VERSION ""

NS_ :

BS_:

BU_: PowertrainControlModule AtmosphericSensor SafetyRestraintSystem2 Aftertreatment_2_GasOutlet Aftertreatment_2_GasIntake DieselParticulateFilterControl Turbocharger SafetyRestraintSystem1 CabDisplay2 Aftertreatment_1_GasOutlet Aftertreatment_1_GasIntake OnBoardDataLogger OffBoardDiagnosticTool2 OffBoardDiagnosticTool1 FileServer ParkingBrakeController SeatController2 FanDriveController SteeringColumnUnit CommunicationUnitRadio CommunicationUnitSatellite CommunicationUnitCellular PropulsionBatteryCharger ChassisController2 ChassisController1 EngineValveControl AuxiliaryHeater2 AuxiliaryHeater1 ClutchUnit RampControl InformationSystem1 SuspensionSystemController2 OilSensor VehicleDynamicStability ExhaustEmissionController TransmissionDisplay2 TransmissionDisplay1 ClimateControl2 WaterPumpController RearAxleSteeringController LightingOperatorControl SeatController1 IgnitionController2 IgnitionController1 TirePressureController CabController2 CabController1 PneumaticSystemController SuspensionSystemController1 HydraulicPumpController EnduranceBrakingSystem RetarderExhaustEngine2 OnBoardDiagnosticUnit HeadwayController RetarderExhaustEngine1 CabDisplay1 ManagementComputer VirtualTerminal OffVehicleGateway PowerTakeOffFront HitchControl AuxiliaryValveControl BodyController TractorTrailerBridge1 StarterSystem ElectricalSystem VehicleSecurity VehicleNavigation AerodynamicControl ElectricalChargingSystem ClimateControl1 TripRecorder InstrumentCluster SuspensionDriveAxle2 SuspensionDriveAxle1 SuspensionSteerAxle SteeringController FuelSystem CruiseControl RetarderDriveline RetarderEngine BrakesDriveAxle2 BrakesDriveAxle1 BrakesSystemController BrakesSteerAxle AxleDrive2 AxleDrive1 AxleSteering PowerTakeOff ShiftConsoleSecondary ShiftConsolePrimary Transmission2 Transmission1 Engine2 Engine1

BO_ 2364643326 HVESP1S1: 8 Vector__XXX
 SG_ Status1CRC : 56|8@1+ (1,0) [0|255] "" Vector__XXX
 SG_ Status1Counter : 52|4@1+ (1,0) [0|15] "" Vector__XXX
 SG_ OperationalStatus : 44|4@1+ (1,0) [0|15] "" Vector__XXX
 SG_ HVBusConnectionStatus : 40|4@1+ (1,0) [0|15] "" Vector__XXX
 SG_ InternalChargerStatus : 32|2@1+ (1,0) [0|3] "" Vector__XXX
 SG_ CellBalancingActive : 30|2@1+ (1,0) [0|3] "" Vector__XXX
 SG_ CellBalanceStatus : 28|2@1+ (1,0) [0|3] "" Vector__XXX
 SG_ StOfChargeStatus : 24|4@1+ (1,0) [0|15] "" Vector__XXX
 SG_ InertiaSwStatus : 22|2@1+ (1,0) [0|3] "" Vector__XXX
 SG_ HVILStatus : 20|2@1+ (1,0) [0|3] "" Vector__XXX
 SG_ HVBusPassiveIsolTestStatus : 16|4@1+ (1,0) [0|15] "" Vector__XXX
 SG_ HVBusActiveIsolTestStatus : 12|4@1+ (1,0) [0|15] "" Vector__XXX
 SG_ CenterOfPackContactorSt : 10|2@1+ (1,0) [0|3] "" Vector__XXX
 SG_ HVBusPreChargeRelaySt : 8|2@1+ (1,0) [0|3] "" Vector__XXX
 SG_ HVBusDisconnectForewarning : 4|4@1+ (1,0) [0|15] "" Vector__XXX
 SG_ HVBusContactorSt11076 : 2|2@1+ (1,0) [0|3] "" Vector__XXX
 SG_ HVBusContactorSt : 0|2@1+ (1,0) [0|3] "" Vector__XXX

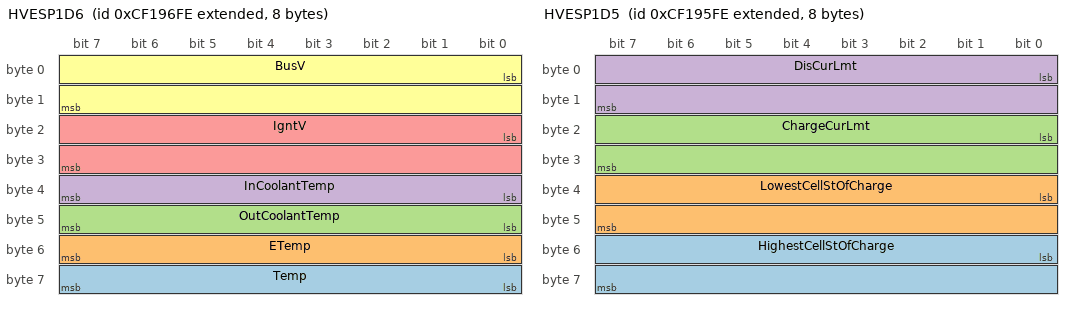
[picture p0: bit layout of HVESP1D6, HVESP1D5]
BO_ 2364643070 HVESP1D6: 8 Vector__XXX
 SG_ Temp : 56|8@1+ (1,-40) [-40|210] "°C" Vector__XXX
 SG_ ETemp : 48|8@1+ (1,-40) [-40|210] "°C" Vector__XXX
 SG_ OutCoolantTemp : 40|8@1+ (1,-40) [-40|210] "°C" Vector__XXX
 SG_ InCoolantTemp : 32|8@1+ (1,-40) [-40|210] "°C" Vector__XXX
 SG_ IgntV : 16|16@1+ (0.01,0) [0|642.55] "V" Vector__XXX
 SG_ BusV : 0|16@1+ (0.05,0) [0|3212.75] "V" Vector__XXX

BO_ 2364642814 HVESP1D5: 8 Vector__XXX
 SG_ HighestCellStOfCharge : 48|16@1+ (0.0015625,0) [0|100.3984375] "%" Vector__XXX
 SG_ LowestCellStOfCharge : 32|16@1+ (0.0015625,0) [0|100.3984375] "%" Vector__XXX
 SG_ ChargeCurLmt : 16|16@1+ (0.05,-1600) [0|1612.75] "A" Vector__XXX
 SG_ DisCurLmt : 0|16@1+ (0.05,-1600) [-1600|0] "A" Vector__XXX

BO_ 2364642558 HVESP1D4: 8 Vector__XXX
 SG_ CellBalancingCount : 32|16@1+ (1,0) [0|64255] "" Vector__XXX
 SG_ ChargeCapacity : 16|16@1+ (0.01,0) [0|642.55] "Ah" Vector__XXX
 SG_ DisCapacity : 0|16@1+ (0.01,0) [0|642.55] "Ah" Vector__XXX

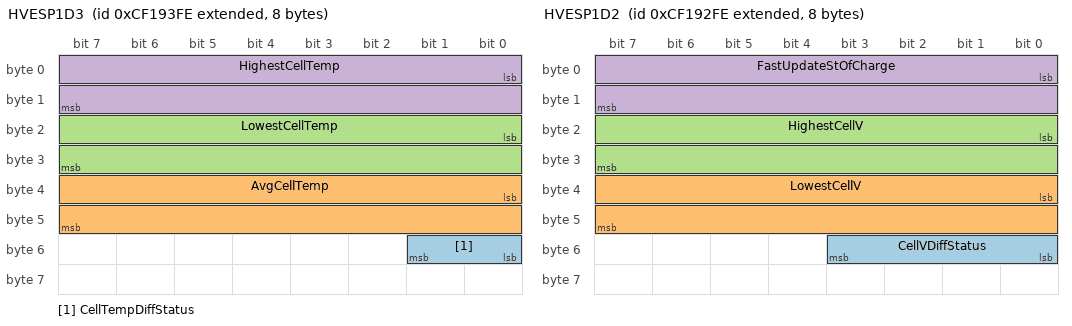
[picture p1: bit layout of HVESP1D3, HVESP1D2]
BO_ 2364642302 HVESP1D3: 8 Vector__XXX
 SG_ CellTempDiffStatus : 48|2@1+ (1,0) [0|3] "" Vector__XXX
 SG_ AvgCellTemp : 32|16@1+ (0.03125,-273) [-273|1734.96875] "°C" Vector__XXX
 SG_ LowestCellTemp : 16|16@1+ (0.03125,-273) [-273|1734.96875] "°C" Vector__XXX
 SG_ HighestCellTemp : 0|16@1+ (0.03125,-273) [-273|1734.96875] "°C" Vector__XXX

BO_ 2364642046 HVESP1D2: 8 Vector__XXX
 SG_ CellVDiffStatus : 48|4@1+ (1,0) [0|15] "" Vector__XXX
 SG_ LowestCellV : 32|16@1+ (0.001,0) [0|64.255] "V" Vector__XXX
 SG_ HighestCellV : 16|16@1+ (0.001,0) [0|64.255] "V" Vector__XXX
 SG_ FastUpdateStOfCharge : 0|16@1+ (0.0015625,0) [0|100.3984375] "%" Vector__XXX

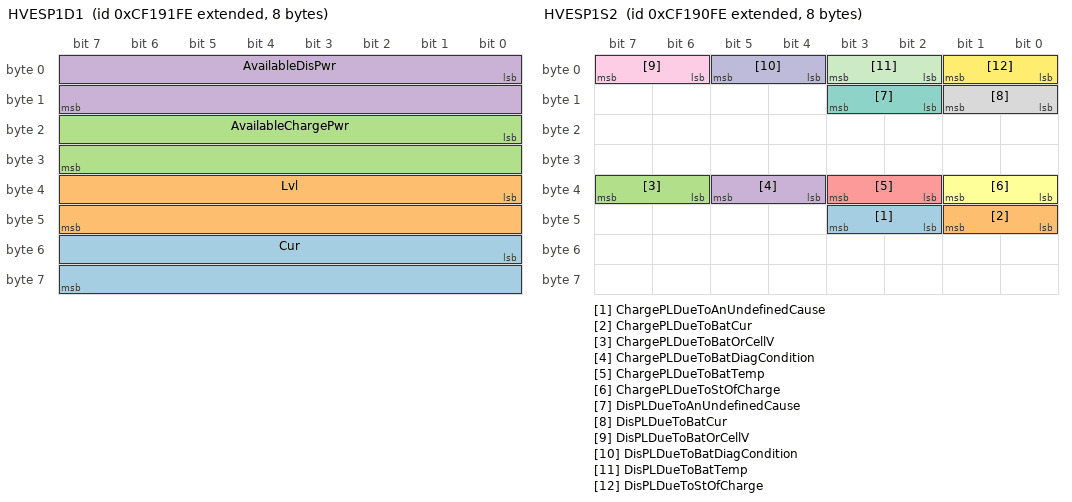
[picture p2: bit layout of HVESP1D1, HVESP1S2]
BO_ 2364641790 HVESP1D1: 8 Vector__XXX
 SG_ Cur : 48|16@1+ (0.05,-1600) [-1600|1612.75] "A" Vector__XXX
 SG_ Lvl : 32|16@1+ (0.05,0) [0|3212.75] "V" Vector__XXX
 SG_ AvailableChargePwr : 16|16@1+ (0.05,0) [0|3212.75] "kW" Vector__XXX
 SG_ AvailableDisPwr : 0|16@1+ (0.05,0) [0|3212.75] "kW" Vector__XXX

BO_ 2364641534 HVESP1S2: 8 Vector__XXX
 SG_ ChargePLDueToAnUndefinedCause : 42|2@1+ (1,0) [0|3] "" Vector__XXX
 SG_ ChargePLDueToBatCur : 40|2@1+ (1,0) [0|3] "" Vector__XXX
 SG_ ChargePLDueToBatOrCellV : 38|2@1+ (1,0) [0|3] "" Vector__XXX
 SG_ ChargePLDueToBatDiagCondition : 36|2@1+ (1,0) [0|3] "" Vector__XXX
 SG_ ChargePLDueToBatTemp : 34|2@1+ (1,0) [0|3] "" Vector__XXX
 SG_ ChargePLDueToStOfCharge : 32|2@1+ (1,0) [0|3] "" Vector__XXX
 SG_ DisPLDueToAnUndefinedCause : 10|2@1+ (1,0) [0|3] "" Vector__XXX
 SG_ DisPLDueToBatCur : 8|2@1+ (1,0) [0|3] "" Vector__XXX
 SG_ DisPLDueToBatOrCellV : 6|2@1+ (1,0) [0|3] "" Vector__XXX
 SG_ DisPLDueToBatDiagCondition : 4|2@1+ (1,0) [0|3] "" Vector__XXX
 SG_ DisPLDueToBatTemp : 2|2@1+ (1,0) [0|3] "" Vector__XXX
 SG_ DisPLDueToStOfCharge : 0|2@1+ (1,0) [0|3] "" Vector__XXX

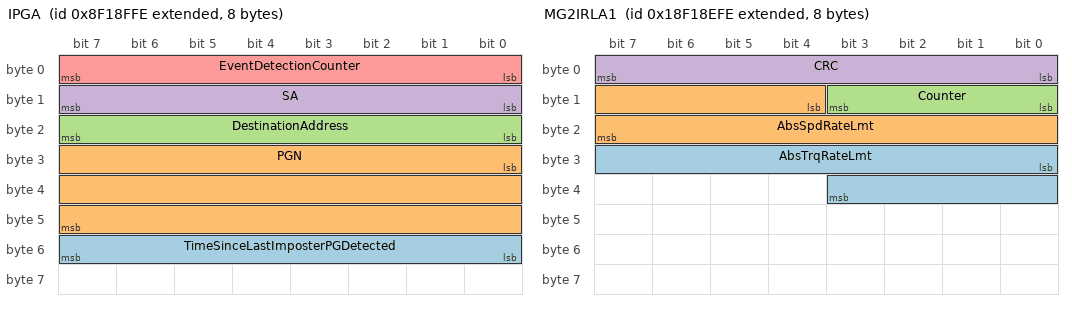
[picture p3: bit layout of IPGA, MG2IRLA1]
BO_ 2297532414 IPGA: 8 Vector__XXX
 SG_ TimeSinceLastImposterPGDetected : 48|8@1+ (1,0) [0|250] "min" Vector__XXX
 SG_ PGN : 24|24@1+ (1,0) [0|16777215] "" Vector__XXX
 SG_ DestinationAddress : 16|8@1+ (1,0) [0|255] "" Vector__XXX
 SG_ SA : 8|8@1+ (1,0) [0|255] "" Vector__XXX
 SG_ EventDetectionCounter : 0|8@1+ (1,0) [0|250] "" Vector__XXX

BO_ 2565967614 MG2IRLA1: 8 Vector__XXX
 SG_ AbsTrqRateLmt : 24|12@1+ (2,0) [0|8030] "%/s" Vector__XXX
 SG_ AbsSpdRateLmt : 12|12@1+ (0.25,0) [0|1003.75] "%/s" Vector__XXX
 SG_ Counter : 8|4@1+ (1,0) [0|15] "" Vector__XXX
 SG_ CRC : 0|8@1+ (1,0) [0|255] "" Vector__XXX

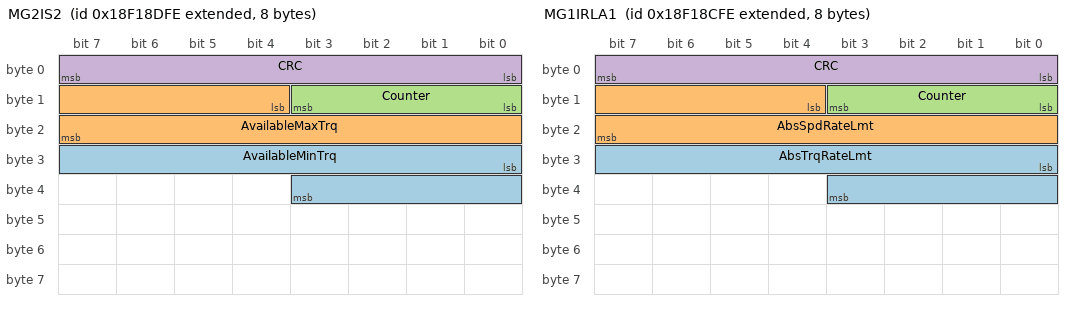
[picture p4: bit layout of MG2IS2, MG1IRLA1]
BO_ 2565967358 MG2IS2: 8 Vector__XXX
 SG_ AvailableMinTrq : 24|12@1+ (0.0625,-125) [-125|125.9375] "%" Vector__XXX
 SG_ AvailableMaxTrq : 12|12@1+ (0.0625,-125) [-125|125.9375] "%" Vector__XXX
 SG_ Counter : 8|4@1+ (1,0) [0|15] "" Vector__XXX
 SG_ CRC : 0|8@1+ (1,0) [0|255] "" Vector__XXX

BO_ 2565967102 MG1IRLA1: 8 Vector__XXX
 SG_ AbsTrqRateLmt : 24|12@1+ (2,0) [0|8030] "%/s" Vector__XXX
 SG_ AbsSpdRateLmt : 12|12@1+ (0.25,0) [0|1003.75] "%/s" Vector__XXX
 SG_ Counter : 8|4@1+ (1,0) [0|15] "" Vector__XXX
 SG_ CRC : 0|8@1+ (1,0) [0|255] "" Vector__XXX

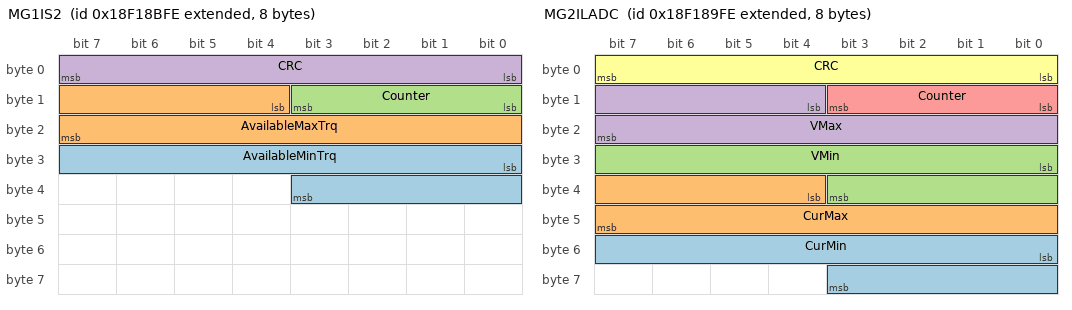
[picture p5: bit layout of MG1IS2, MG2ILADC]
BO_ 2565966846 MG1IS2: 8 Vector__XXX
 SG_ AvailableMinTrq : 24|12@1+ (0.0625,-125) [-125|125.9375] "%" Vector__XXX
 SG_ AvailableMaxTrq : 12|12@1+ (0.0625,-125) [-125|125.9375] "%" Vector__XXX
 SG_ Counter : 8|4@1+ (1,0) [0|15] "" Vector__XXX
 SG_ CRC : 0|8@1+ (1,0) [0|255] "" Vector__XXX

BO_ 2565966590 MG2ILV: 8 Vector__XXX
 SG_ UnswitchedSLIV : 16|16@1+ (0.05,0) [0|3212.75] "V" Vector__XXX
 SG_ SwitchedIgntV : 0|16@1+ (0.05,0) [0|3212.75] "V" Vector__XXX

BO_ 2565966334 MG2ILADC: 8 Vector__XXX
 SG_ CurMin : 48|12@1+ (0.0625,-125) [-125|125.9375] "%" Vector__XXX
 SG_ CurMax : 36|12@1+ (0.0625,-125) [-125|125.9375] "%" Vector__XXX
 SG_ VMin : 24|12@1+ (0.0625,-125) [-125|125.9375] "%" Vector__XXX
 SG_ VMax : 12|12@1+ (0.0625,-125) [-125|125.9375] "%" Vector__XXX
 SG_ Counter : 8|4@1+ (1,0) [0|15] "" Vector__XXX
 SG_ CRC : 0|8@1+ (1,0) [0|255] "" Vector__XXX

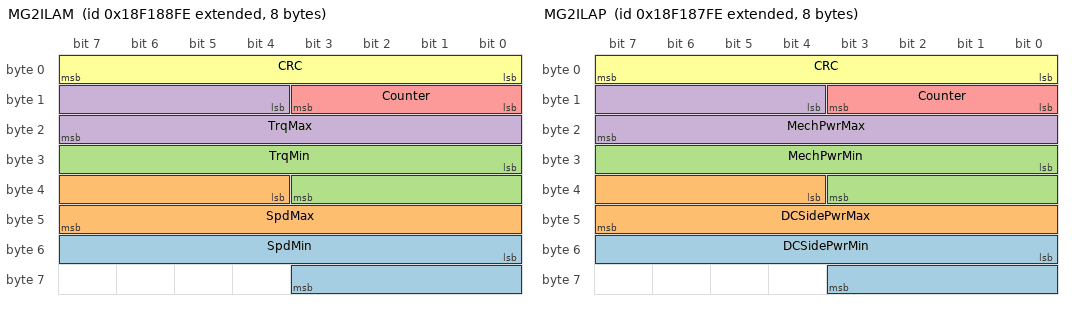
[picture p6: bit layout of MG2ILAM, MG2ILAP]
BO_ 2565966078 MG2ILAM: 8 Vector__XXX
 SG_ SpdMin : 48|12@1+ (0.0625,-125) [-125|125.9375] "%" Vector__XXX
 SG_ SpdMax : 36|12@1+ (0.0625,-125) [-125|125.9375] "%" Vector__XXX
 SG_ TrqMin : 24|12@1+ (0.0625,-125) [-125|125.9375] "%" Vector__XXX
 SG_ TrqMax : 12|12@1+ (0.0625,-125) [-125|125.9375] "%" Vector__XXX
 SG_ Counter : 8|4@1+ (1,0) [0|15] "" Vector__XXX
 SG_ CRC : 0|8@1+ (1,0) [0|255] "" Vector__XXX

BO_ 2565965822 MG2ILAP: 8 Vector__XXX
 SG_ DCSidePwrMin : 48|12@1+ (0.0625,-125) [-125|125.9375] "%" Vector__XXX
 SG_ DCSidePwrMax : 36|12@1+ (0.0625,-125) [-125|125.9375] "%" Vector__XXX
 SG_ MechPwrMin : 24|12@1+ (0.0625,-125) [-125|125.9375] "%" Vector__XXX
 SG_ MechPwrMax : 12|12@1+ (0.0625,-125) [-125|125.9375] "%" Vector__XXX
 SG_ Counter : 8|4@1+ (1,0) [0|15] "" Vector__XXX
 SG_ CRC : 0|8@1+ (1,0) [0|255] "" Vector__XXX

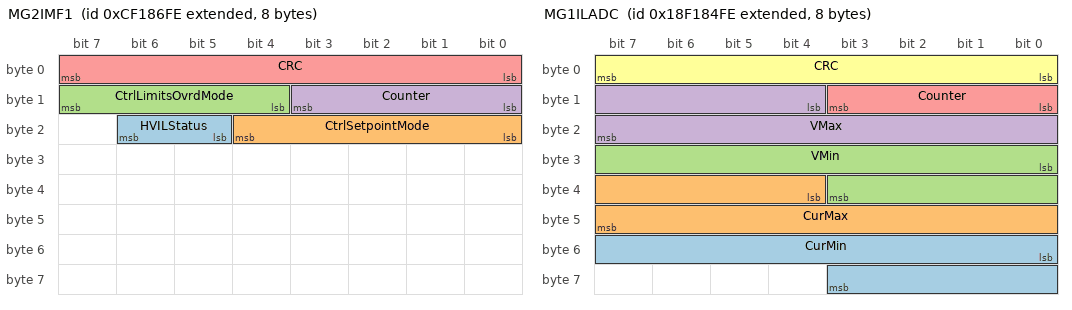
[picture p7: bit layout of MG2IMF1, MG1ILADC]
BO_ 2364638974 MG2IMF1: 8 Vector__XXX
 SG_ HVILStatus : 21|2@1+ (1,0) [0|3] "" Vector__XXX
 SG_ CtrlSetpointMode : 16|5@1+ (1,0) [0|31] "" Vector__XXX
 SG_ CtrlLimitsOvrdMode : 12|4@1+ (1,0) [0|15] "" Vector__XXX
 SG_ Counter : 8|4@1+ (1,0) [0|15] "" Vector__XXX
 SG_ CRC : 0|8@1+ (1,0) [0|255] "" Vector__XXX

BO_ 2565965310 MG1ILV: 8 Vector__XXX
 SG_ UnswitchedSLIV : 16|16@1+ (0.05,0) [0|3212.75] "V" Vector__XXX
 SG_ SwitchedIgntV : 0|16@1+ (0.05,0) [0|3212.75] "V" Vector__XXX

BO_ 2565965054 MG1ILADC: 8 Vector__XXX
 SG_ CurMin : 48|12@1+ (0.0625,-125) [-125|125.9375] "%" Vector__XXX
 SG_ CurMax : 36|12@1+ (0.0625,-125) [-125|125.9375] "%" Vector__XXX
 SG_ VMin : 24|12@1+ (0.0625,-125) [-125|125.9375] "%" Vector__XXX
 SG_ VMax : 12|12@1+ (0.0625,-125) [-125|125.9375] "%" Vector__XXX
 SG_ Counter : 8|4@1+ (1,0) [0|15] "" Vector__XXX
 SG_ CRC : 0|8@1+ (1,0) [0|255] "" Vector__XXX

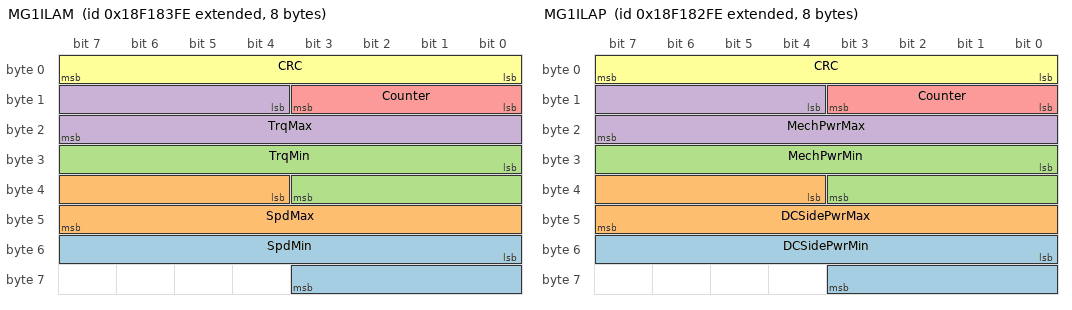
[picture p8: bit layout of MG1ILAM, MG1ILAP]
BO_ 2565964798 MG1ILAM: 8 Vector__XXX
 SG_ SpdMin : 48|12@1+ (0.0625,-125) [-125|125.9375] "%" Vector__XXX
 SG_ SpdMax : 36|12@1+ (0.0625,-125) [-125|125.9375] "%" Vector__XXX
 SG_ TrqMin : 24|12@1+ (0.0625,-125) [-125|125.9375] "%" Vector__XXX
 SG_ TrqMax : 12|12@1+ (0.0625,-125) [-125|125.9375] "%" Vector__XXX
 SG_ Counter : 8|4@1+ (1,0) [0|15] "" Vector__XXX
 SG_ CRC : 0|8@1+ (1,0) [0|255] "" Vector__XXX

BO_ 2565964542 MG1ILAP: 8 Vector__XXX
 SG_ DCSidePwrMin : 48|12@1+ (0.0625,-125) [-125|125.9375] "%" Vector__XXX
 SG_ DCSidePwrMax : 36|12@1+ (0.0625,-125) [-125|125.9375] "%" Vector__XXX
 SG_ MechPwrMin : 24|12@1+ (0.0625,-125) [-125|125.9375] "%" Vector__XXX
 SG_ MechPwrMax : 12|12@1+ (0.0625,-125) [-125|125.9375] "%" Vector__XXX
 SG_ Counter : 8|4@1+ (1,0) [0|15] "" Vector__XXX
 SG_ CRC : 0|8@1+ (1,0) [0|255] "" Vector__XXX

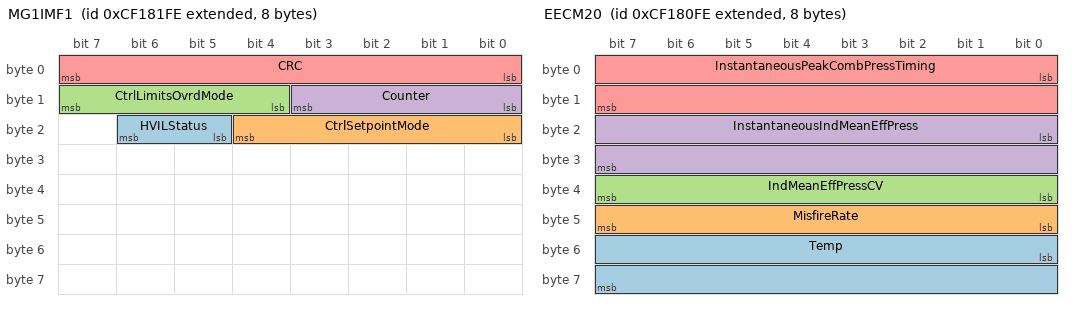
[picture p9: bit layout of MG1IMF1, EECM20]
BO_ 2364637694 MG1IMF1: 8 Vector__XXX
 SG_ HVILStatus : 21|2@1+ (1,0) [0|3] "" Vector__XXX
 SG_ CtrlSetpointMode : 16|5@1+ (1,0) [0|31] "" Vector__XXX
 SG_ CtrlLimitsOvrdMode : 12|4@1+ (1,0) [0|15] "" Vector__XXX
 SG_ Counter : 8|4@1+ (1,0) [0|15] "" Vector__XXX
 SG_ CRC : 0|8@1+ (1,0) [0|255] "" Vector__XXX

BO_ 2364637438 EECM20: 8 Vector__XXX
 SG_ Temp : 48|16@1+ (0.03125,-273) [-273|1734.96875] "°C" Vector__XXX
 SG_ MisfireRate : 40|8@1+ (0.4,0) [0|100] "%" Vector__XXX
 SG_ IndMeanEffPressCV : 32|8@1+ (0.04,0) [0|10] "%" Vector__XXX
 SG_ InstantaneousIndMeanEffPress : 16|16@1+ (0.0001220703125,-1) [-1|6.8436279296875] "MPa" Vector__XXX
 SG_ InstantaneousPeakCombPressTiming : 0|16@1+ (0.00390625,-125) [-125|125.99609375] "deg" Vector__XXX

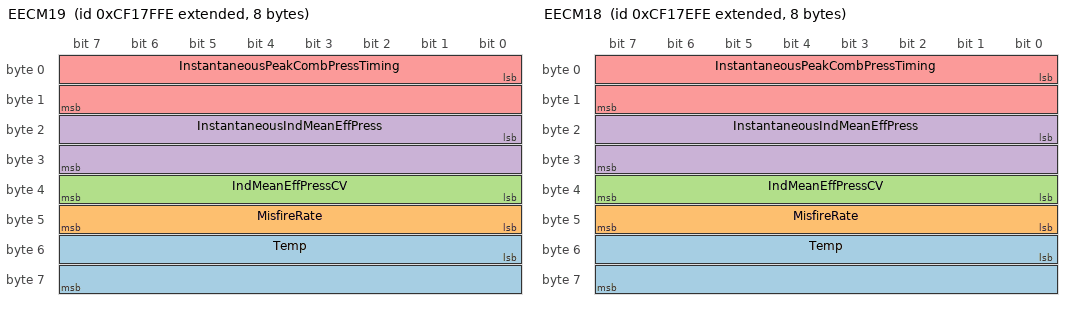
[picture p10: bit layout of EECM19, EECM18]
BO_ 2364637182 EECM19: 8 Vector__XXX
 SG_ Temp : 48|16@1+ (0.03125,-273) [-273|1734.96875] "°C" Vector__XXX
 SG_ MisfireRate : 40|8@1+ (0.4,0) [0|100] "%" Vector__XXX
 SG_ IndMeanEffPressCV : 32|8@1+ (0.04,0) [0|10] "%" Vector__XXX
 SG_ InstantaneousIndMeanEffPress : 16|16@1+ (0.0001220703125,-1) [-1|6.8436279296875] "MPa" Vector__XXX
 SG_ InstantaneousPeakCombPressTiming : 0|16@1+ (0.00390625,-125) [-125|125.99609375] "deg" Vector__XXX

BO_ 2364636926 EECM18: 8 Vector__XXX
 SG_ Temp : 48|16@1+ (0.03125,-273) [-273|1734.96875] "°C" Vector__XXX
 SG_ MisfireRate : 40|8@1+ (0.4,0) [0|100] "%" Vector__XXX
 SG_ IndMeanEffPressCV : 32|8@1+ (0.04,0) [0|10] "%" Vector__XXX
 SG_ InstantaneousIndMeanEffPress : 16|16@1+ (0.0001220703125,-1) [-1|6.8436279296875] "MPa" Vector__XXX
 SG_ InstantaneousPeakCombPressTiming : 0|16@1+ (0.00390625,-125) [-125|125.99609375] "deg" Vector__XXX

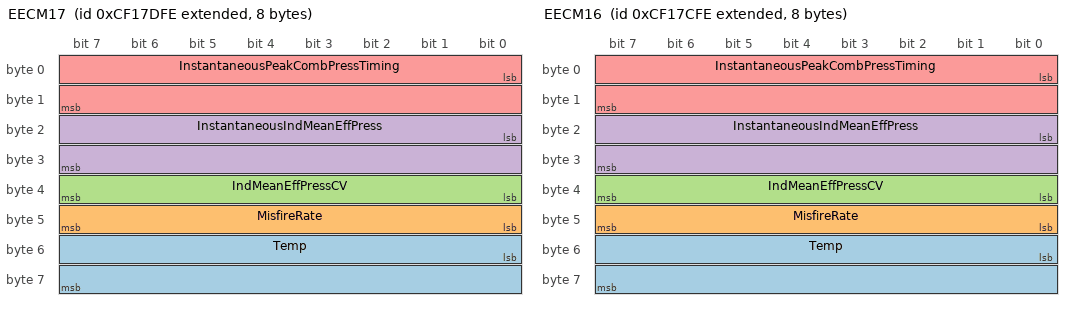
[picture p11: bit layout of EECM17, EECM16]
BO_ 2364636670 EECM17: 8 Vector__XXX
 SG_ Temp : 48|16@1+ (0.03125,-273) [-273|1734.96875] "°C" Vector__XXX
 SG_ MisfireRate : 40|8@1+ (0.4,0) [0|100] "%" Vector__XXX
 SG_ IndMeanEffPressCV : 32|8@1+ (0.04,0) [0|10] "%" Vector__XXX
 SG_ InstantaneousIndMeanEffPress : 16|16@1+ (0.0001220703125,-1) [-1|6.8436279296875] "MPa" Vector__XXX
 SG_ InstantaneousPeakCombPressTiming : 0|16@1+ (0.00390625,-125) [-125|125.99609375] "deg" Vector__XXX

BO_ 2364636414 EECM16: 8 Vector__XXX
 SG_ Temp : 48|16@1+ (0.03125,-273) [-273|1734.96875] "°C" Vector__XXX
 SG_ MisfireRate : 40|8@1+ (0.4,0) [0|100] "%" Vector__XXX
 SG_ IndMeanEffPressCV : 32|8@1+ (0.04,0) [0|10] "%" Vector__XXX
 SG_ InstantaneousIndMeanEffPress : 16|16@1+ (0.0001220703125,-1) [-1|6.8436279296875] "MPa" Vector__XXX
 SG_ InstantaneousPeakCombPressTiming : 0|16@1+ (0.00390625,-125) [-125|125.99609375] "deg" Vector__XXX

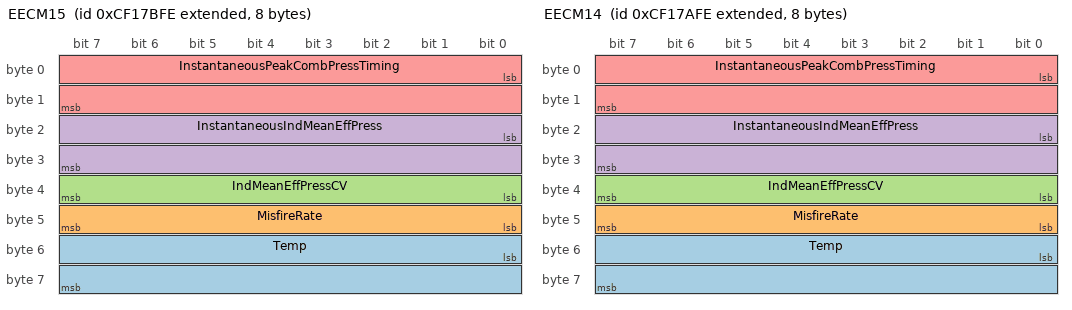
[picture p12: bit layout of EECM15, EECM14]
BO_ 2364636158 EECM15: 8 Vector__XXX
 SG_ Temp : 48|16@1+ (0.03125,-273) [-273|1734.96875] "°C" Vector__XXX
 SG_ MisfireRate : 40|8@1+ (0.4,0) [0|100] "%" Vector__XXX
 SG_ IndMeanEffPressCV : 32|8@1+ (0.04,0) [0|10] "%" Vector__XXX
 SG_ InstantaneousIndMeanEffPress : 16|16@1+ (0.0001220703125,-1) [-1|6.8436279296875] "MPa" Vector__XXX
 SG_ InstantaneousPeakCombPressTiming : 0|16@1+ (0.00390625,-125) [-125|125.99609375] "deg" Vector__XXX

BO_ 2364635902 EECM14: 8 Vector__XXX
 SG_ Temp : 48|16@1+ (0.03125,-273) [-273|1734.96875] "°C" Vector__XXX
 SG_ MisfireRate : 40|8@1+ (0.4,0) [0|100] "%" Vector__XXX
 SG_ IndMeanEffPressCV : 32|8@1+ (0.04,0) [0|10] "%" Vector__XXX
 SG_ InstantaneousIndMeanEffPress : 16|16@1+ (0.0001220703125,-1) [-1|6.8436279296875] "MPa" Vector__XXX
 SG_ InstantaneousPeakCombPressTiming : 0|16@1+ (0.00390625,-125) [-125|125.99609375] "deg" Vector__XXX

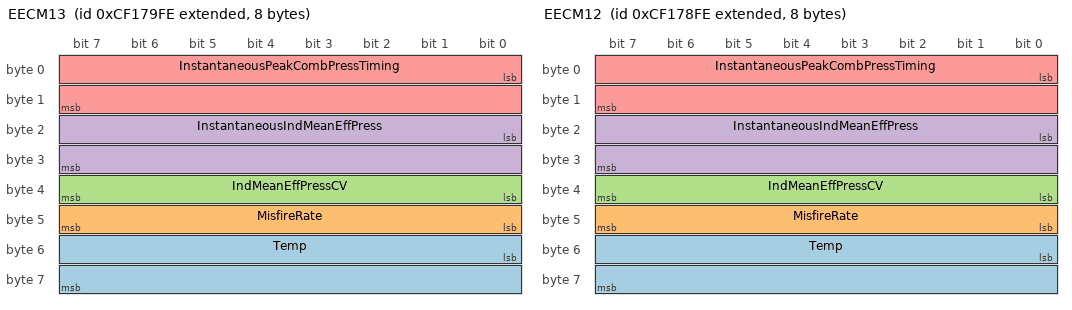
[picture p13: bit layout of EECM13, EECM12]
BO_ 2364635646 EECM13: 8 Vector__XXX
 SG_ Temp : 48|16@1+ (0.03125,-273) [-273|1734.96875] "°C" Vector__XXX
 SG_ MisfireRate : 40|8@1+ (0.4,0) [0|100] "%" Vector__XXX
 SG_ IndMeanEffPressCV : 32|8@1+ (0.04,0) [0|10] "%" Vector__XXX
 SG_ InstantaneousIndMeanEffPress : 16|16@1+ (0.0001220703125,-1) [-1|6.8436279296875] "MPa" Vector__XXX
 SG_ InstantaneousPeakCombPressTiming : 0|16@1+ (0.00390625,-125) [-125|125.99609375] "deg" Vector__XXX

BO_ 2364635390 EECM12: 8 Vector__XXX
 SG_ Temp : 48|16@1+ (0.03125,-273) [-273|1734.96875] "°C" Vector__XXX
 SG_ MisfireRate : 40|8@1+ (0.4,0) [0|100] "%" Vector__XXX
 SG_ IndMeanEffPressCV : 32|8@1+ (0.04,0) [0|10] "%" Vector__XXX
 SG_ InstantaneousIndMeanEffPress : 16|16@1+ (0.0001220703125,-1) [-1|6.8436279296875] "MPa" Vector__XXX
 SG_ InstantaneousPeakCombPressTiming : 0|16@1+ (0.00390625,-125) [-125|125.99609375] "deg" Vector__XXX

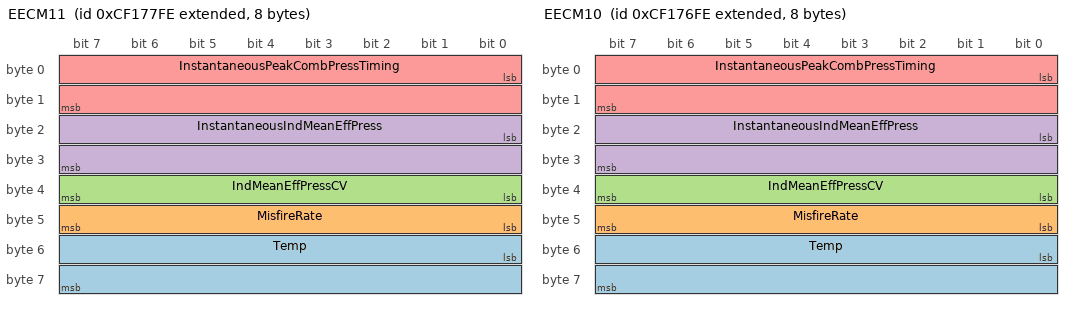
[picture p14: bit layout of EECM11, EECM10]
BO_ 2364635134 EECM11: 8 Vector__XXX
 SG_ Temp : 48|16@1+ (0.03125,-273) [-273|1734.96875] "°C" Vector__XXX
 SG_ MisfireRate : 40|8@1+ (0.4,0) [0|100] "%" Vector__XXX
 SG_ IndMeanEffPressCV : 32|8@1+ (0.04,0) [0|10] "%" Vector__XXX
 SG_ InstantaneousIndMeanEffPress : 16|16@1+ (0.0001220703125,-1) [-1|6.8436279296875] "MPa" Vector__XXX
 SG_ InstantaneousPeakCombPressTiming : 0|16@1+ (0.00390625,-125) [-125|125.99609375] "deg" Vector__XXX

BO_ 2364634878 EECM10: 8 Vector__XXX
 SG_ Temp : 48|16@1+ (0.03125,-273) [-273|1734.96875] "°C" Vector__XXX
 SG_ MisfireRate : 40|8@1+ (0.4,0) [0|100] "%" Vector__XXX
 SG_ IndMeanEffPressCV : 32|8@1+ (0.04,0) [0|10] "%" Vector__XXX
 SG_ InstantaneousIndMeanEffPress : 16|16@1+ (0.0001220703125,-1) [-1|6.8436279296875] "MPa" Vector__XXX
 SG_ InstantaneousPeakCombPressTiming : 0|16@1+ (0.00390625,-125) [-125|125.99609375] "deg" Vector__XXX

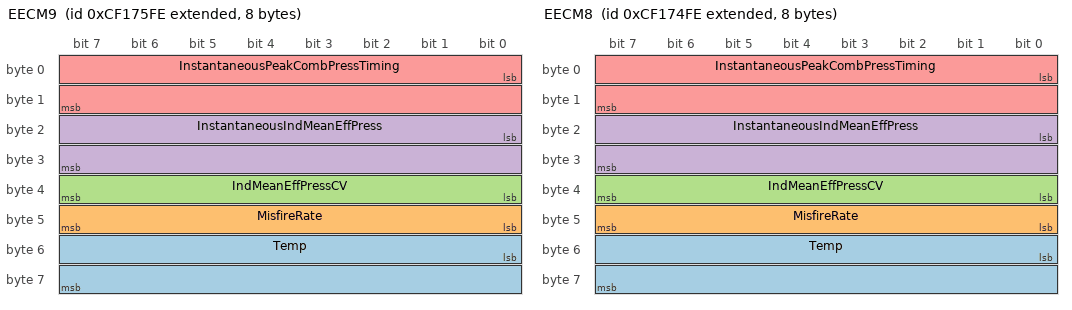
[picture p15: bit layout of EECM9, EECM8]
BO_ 2364634622 EECM9: 8 Vector__XXX
 SG_ Temp : 48|16@1+ (0.03125,-273) [-273|1734.96875] "°C" Vector__XXX
 SG_ MisfireRate : 40|8@1+ (0.4,0) [0|100] "%" Vector__XXX
 SG_ IndMeanEffPressCV : 32|8@1+ (0.04,0) [0|10] "%" Vector__XXX
 SG_ InstantaneousIndMeanEffPress : 16|16@1+ (0.0001220703125,-1) [-1|6.8436279296875] "MPa" Vector__XXX
 SG_ InstantaneousPeakCombPressTiming : 0|16@1+ (0.00390625,-125) [-125|125.99609375] "deg" Vector__XXX

BO_ 2364634366 EECM8: 8 Vector__XXX
 SG_ Temp : 48|16@1+ (0.03125,-273) [-273|1734.96875] "°C" Vector__XXX
 SG_ MisfireRate : 40|8@1+ (0.4,0) [0|100] "%" Vector__XXX
 SG_ IndMeanEffPressCV : 32|8@1+ (0.04,0) [0|10] "%" Vector__XXX
 SG_ InstantaneousIndMeanEffPress : 16|16@1+ (0.0001220703125,-1) [-1|6.8436279296875] "MPa" Vector__XXX
 SG_ InstantaneousPeakCombPressTiming : 0|16@1+ (0.00390625,-125) [-125|125.99609375] "deg" Vector__XXX

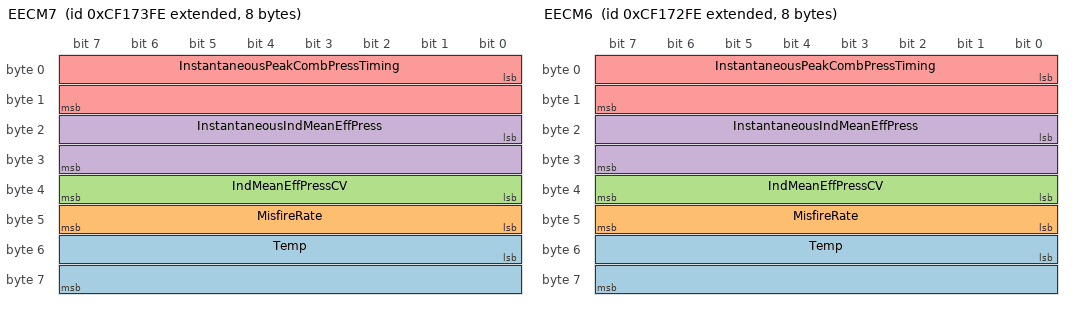
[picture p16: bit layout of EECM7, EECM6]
BO_ 2364634110 EECM7: 8 Vector__XXX
 SG_ Temp : 48|16@1+ (0.03125,-273) [-273|1734.96875] "°C" Vector__XXX
 SG_ MisfireRate : 40|8@1+ (0.4,0) [0|100] "%" Vector__XXX
 SG_ IndMeanEffPressCV : 32|8@1+ (0.04,0) [0|10] "%" Vector__XXX
 SG_ InstantaneousIndMeanEffPress : 16|16@1+ (0.0001220703125,-1) [-1|6.8436279296875] "MPa" Vector__XXX
 SG_ InstantaneousPeakCombPressTiming : 0|16@1+ (0.00390625,-125) [-125|125.99609375] "deg" Vector__XXX

BO_ 2364633854 EECM6: 8 Vector__XXX
 SG_ Temp : 48|16@1+ (0.03125,-273) [-273|1734.96875] "°C" Vector__XXX
 SG_ MisfireRate : 40|8@1+ (0.4,0) [0|100] "%" Vector__XXX
 SG_ IndMeanEffPressCV : 32|8@1+ (0.04,0) [0|10] "%" Vector__XXX
 SG_ InstantaneousIndMeanEffPress : 16|16@1+ (0.0001220703125,-1) [-1|6.8436279296875] "MPa" Vector__XXX
 SG_ InstantaneousPeakCombPressTiming : 0|16@1+ (0.00390625,-125) [-125|125.99609375] "deg" Vector__XXX

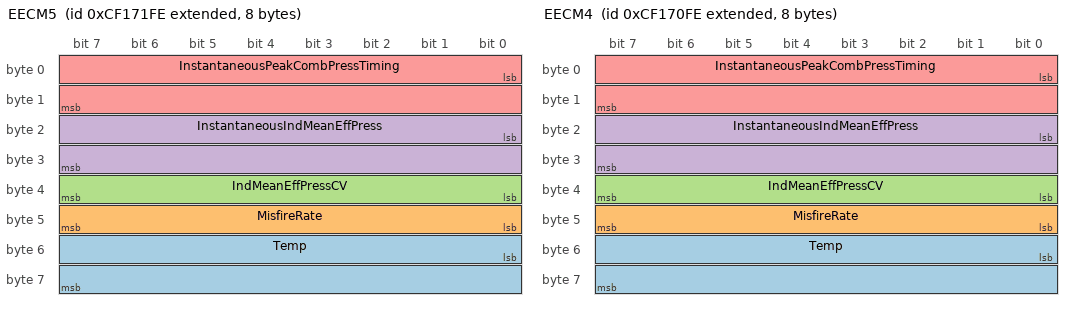
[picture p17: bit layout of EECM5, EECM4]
BO_ 2364633598 EECM5: 8 Vector__XXX
 SG_ Temp : 48|16@1+ (0.03125,-273) [-273|1734.96875] "°C" Vector__XXX
 SG_ MisfireRate : 40|8@1+ (0.4,0) [0|100] "%" Vector__XXX
 SG_ IndMeanEffPressCV : 32|8@1+ (0.04,0) [0|10] "%" Vector__XXX
 SG_ InstantaneousIndMeanEffPress : 16|16@1+ (0.0001220703125,-1) [-1|6.8436279296875] "MPa" Vector__XXX
 SG_ InstantaneousPeakCombPressTiming : 0|16@1+ (0.00390625,-125) [-125|125.99609375] "deg" Vector__XXX

BO_ 2364633342 EECM4: 8 Vector__XXX
 SG_ Temp : 48|16@1+ (0.03125,-273) [-273|1734.96875] "°C" Vector__XXX
 SG_ MisfireRate : 40|8@1+ (0.4,0) [0|100] "%" Vector__XXX
 SG_ IndMeanEffPressCV : 32|8@1+ (0.04,0) [0|10] "%" Vector__XXX
 SG_ InstantaneousIndMeanEffPress : 16|16@1+ (0.0001220703125,-1) [-1|6.8436279296875] "MPa" Vector__XXX
 SG_ InstantaneousPeakCombPressTiming : 0|16@1+ (0.00390625,-125) [-125|125.99609375] "deg" Vector__XXX

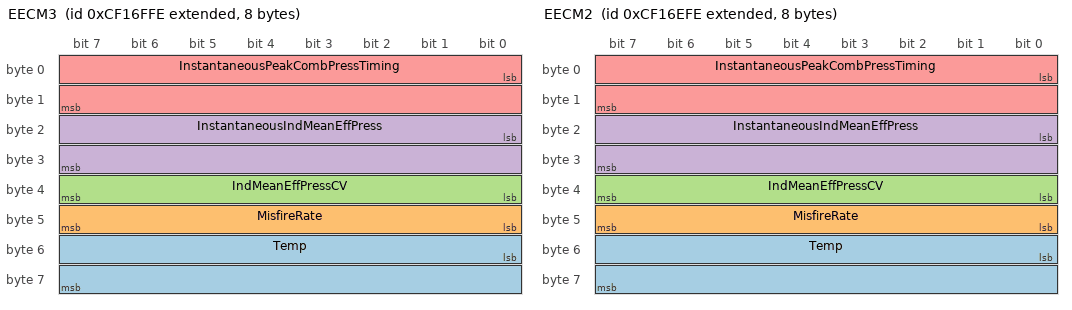
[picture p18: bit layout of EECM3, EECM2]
BO_ 2364633086 EECM3: 8 Vector__XXX
 SG_ Temp : 48|16@1+ (0.03125,-273) [-273|1734.96875] "°C" Vector__XXX
 SG_ MisfireRate : 40|8@1+ (0.4,0) [0|100] "%" Vector__XXX
 SG_ IndMeanEffPressCV : 32|8@1+ (0.04,0) [0|10] "%" Vector__XXX
 SG_ InstantaneousIndMeanEffPress : 16|16@1+ (0.0001220703125,-1) [-1|6.8436279296875] "MPa" Vector__XXX
 SG_ InstantaneousPeakCombPressTiming : 0|16@1+ (0.00390625,-125) [-125|125.99609375] "deg" Vector__XXX

BO_ 2364632830 EECM2: 8 Vector__XXX
 SG_ Temp : 48|16@1+ (0.03125,-273) [-273|1734.96875] "°C" Vector__XXX
 SG_ MisfireRate : 40|8@1+ (0.4,0) [0|100] "%" Vector__XXX
 SG_ IndMeanEffPressCV : 32|8@1+ (0.04,0) [0|10] "%" Vector__XXX
 SG_ InstantaneousIndMeanEffPress : 16|16@1+ (0.0001220703125,-1) [-1|6.8436279296875] "MPa" Vector__XXX
 SG_ InstantaneousPeakCombPressTiming : 0|16@1+ (0.00390625,-125) [-125|125.99609375] "deg" Vector__XXX

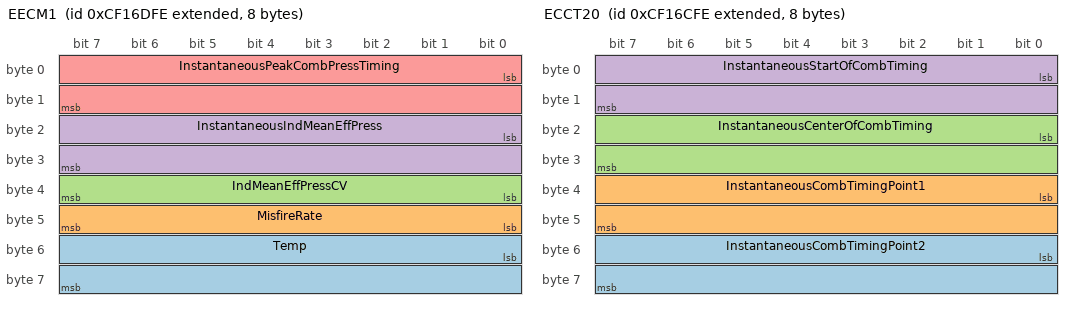
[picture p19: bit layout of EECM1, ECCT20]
BO_ 2364632574 EECM1: 8 Vector__XXX
 SG_ Temp : 48|16@1+ (0.03125,-273) [-273|1734.96875] "°C" Vector__XXX
 SG_ MisfireRate : 40|8@1+ (0.4,0) [0|100] "%" Vector__XXX
 SG_ IndMeanEffPressCV : 32|8@1+ (0.04,0) [0|10] "%" Vector__XXX
 SG_ InstantaneousIndMeanEffPress : 16|16@1+ (0.0001220703125,-1) [-1|6.8436279296875] "MPa" Vector__XXX
 SG_ InstantaneousPeakCombPressTiming : 0|16@1+ (0.00390625,-125) [-125|125.99609375] "deg" Vector__XXX

BO_ 2364632318 ECCT20: 8 Vector__XXX
 SG_ InstantaneousCombTimingPoint2 : 48|16@1+ (0.00390625,-125) [-125|125.99609375] "deg" Vector__XXX
 SG_ InstantaneousCombTimingPoint1 : 32|16@1+ (0.00390625,-125) [-125|125.99609375] "deg" Vector__XXX
 SG_ InstantaneousCenterOfCombTiming : 16|16@1+ (0.00390625,-125) [-125|125.99609375] "deg" Vector__XXX
 SG_ InstantaneousStartOfCombTiming : 0|16@1+ (0.00390625,-125) [-125|125.99609375] "deg" Vector__XXX

BO_ 2364632062 ECCT19: 8 Vector__XXX
 SG_ InstantaneousCombTimingPoint2 : 48|16@1+ (0.00390625,-125) [-125|125.99609375] "deg" Vector__XXX
 SG_ InstantaneousCombTimingPoint1 : 32|16@1+ (0.00390625,-125) [-125|125.99609375] "deg" Vector__XXX
 SG_ InstantaneousCenterOfCombTiming : 16|16@1+ (0.00390625,-125) [-125|125.99609375] "deg" Vector__XXX
 SG_ InstantaneousStartOfCombTiming : 0|16@1+ (0.00390625,-125) [-125|125.99609375] "deg" Vector__XXX

BO_ 2364631806 ECCT18: 8 Vector__XXX
 SG_ InstantaneousCombTimingPoint2 : 48|16@1+ (0.00390625,-125) [-125|125.99609375] "deg" Vector__XXX
 SG_ InstantaneousCombTimingPoint1 : 32|16@1+ (0.00390625,-125) [-125|125.99609375] "deg" Vector__XXX
 SG_ InstantaneousCenterOfCombTiming : 16|16@1+ (0.00390625,-125) [-125|125.99609375] "deg" Vector__XXX
 SG_ InstantaneousStartOfCombTiming : 0|16@1+ (0.00390625,-125) [-125|125.99609375] "deg" Vector__XXX

BO_ 2364631550 ECCT17: 8 Vector__XXX
 SG_ InstantaneousCombTimingPoint2 : 48|16@1+ (0.00390625,-125) [-125|125.99609375] "deg" Vector__XXX
 SG_ InstantaneousCombTimingPoint1 : 32|16@1+ (0.00390625,-125) [-125|125.99609375] "deg" Vector__XXX
 SG_ InstantaneousCenterOfCombTiming : 16|16@1+ (0.00390625,-125) [-125|125.99609375] "deg" Vector__XXX
 SG_ InstantaneousStartOfCombTiming : 0|16@1+ (0.00390625,-125) [-125|125.99609375] "deg" Vector__XXX

BO_ 2364631294 ECCT16: 8 Vector__XXX
 SG_ InstantaneousCombTimingPoint2 : 48|16@1+ (0.00390625,-125) [-125|125.99609375] "deg" Vector__XXX
 SG_ InstantaneousCombTimingPoint1 : 32|16@1+ (0.00390625,-125) [-125|125.99609375] "deg" Vector__XXX
 SG_ InstantaneousCenterOfCombTiming : 16|16@1+ (0.00390625,-125) [-125|125.99609375] "deg" Vector__XXX
 SG_ InstantaneousStartOfCombTiming : 0|16@1+ (0.00390625,-125) [-125|125.99609375] "deg" Vector__XXX

BO_ 2364631038 ECCT15: 8 Vector__XXX
 SG_ InstantaneousCombTimingPoint2 : 48|16@1+ (0.00390625,-125) [-125|125.99609375] "deg" Vector__XXX
 SG_ InstantaneousCombTimingPoint1 : 32|16@1+ (0.00390625,-125) [-125|125.99609375] "deg" Vector__XXX
 SG_ InstantaneousCenterOfCombTiming : 16|16@1+ (0.00390625,-125) [-125|125.99609375] "deg" Vector__XXX
 SG_ InstantaneousStartOfCombTiming : 0|16@1+ (0.00390625,-125) [-125|125.99609375] "deg" Vector__XXX

BO_ 2364630782 ECCT14: 8 Vector__XXX
 SG_ InstantaneousCombTimingPoint2 : 48|16@1+ (0.00390625,-125) [-125|125.99609375] "deg" Vector__XXX
 SG_ InstantaneousCombTimingPoint1 : 32|16@1+ (0.00390625,-125) [-125|125.99609375] "deg" Vector__XXX
 SG_ InstantaneousCenterOfCombTiming : 16|16@1+ (0.00390625,-125) [-125|125.99609375] "deg" Vector__XXX
 SG_ InstantaneousStartOfCombTiming : 0|16@1+ (0.00390625,-125) [-125|125.99609375] "deg" Vector__XXX

BO_ 2364630526 ECCT13: 8 Vector__XXX
 SG_ InstantaneousCombTimingPoint2 : 48|16@1+ (0.00390625,-125) [-125|125.99609375] "deg" Vector__XXX
 SG_ InstantaneousCombTimingPoint1 : 32|16@1+ (0.00390625,-125) [-125|125.99609375] "deg" Vector__XXX
 SG_ InstantaneousCenterOfCombTiming : 16|16@1+ (0.00390625,-125) [-125|125.99609375] "deg" Vector__XXX
 SG_ InstantaneousStartOfCombTiming : 0|16@1+ (0.00390625,-125) [-125|125.99609375] "deg" Vector__XXX

BO_ 2364630270 ECCT12: 8 Vector__XXX
 SG_ InstantaneousCombTimingPoint2 : 48|16@1+ (0.00390625,-125) [-125|125.99609375] "deg" Vector__XXX
 SG_ InstantaneousCombTimingPoint1 : 32|16@1+ (0.00390625,-125) [-125|125.99609375] "deg" Vector__XXX
 SG_ InstantaneousCenterOfCombTiming : 16|16@1+ (0.00390625,-125) [-125|125.99609375] "deg" Vector__XXX
 SG_ InstantaneousStartOfCombTiming : 0|16@1+ (0.00390625,-125) [-125|125.99609375] "deg" Vector__XXX

BO_ 2364630014 ECCT11: 8 Vector__XXX
 SG_ InstantaneousCombTimingPoint2 : 48|16@1+ (0.00390625,-125) [-125|125.99609375] "deg" Vector__XXX
 SG_ InstantaneousCombTimingPoint1 : 32|16@1+ (0.00390625,-125) [-125|125.99609375] "deg" Vector__XXX
 SG_ InstantaneousCenterOfCombTiming : 16|16@1+ (0.00390625,-125) [-125|125.99609375] "deg" Vector__XXX
 SG_ InstantaneousStartOfCombTiming : 0|16@1+ (0.00390625,-125) [-125|125.99609375] "deg" Vector__XXX

BO_ 2364629758 ECCT10: 8 Vector__XXX
 SG_ InstantaneousCombTimingPoint2 : 48|16@1+ (0.00390625,-125) [-125|125.99609375] "deg" Vector__XXX
 SG_ InstantaneousCombTimingPoint1 : 32|16@1+ (0.00390625,-125) [-125|125.99609375] "deg" Vector__XXX
 SG_ InstantaneousCenterOfCombTiming : 16|16@1+ (0.00390625,-125) [-125|125.99609375] "deg" Vector__XXX
 SG_ InstantaneousStartOfCombTiming : 0|16@1+ (0.00390625,-125) [-125|125.99609375] "deg" Vector__XXX

BO_ 2364629502 ECCT9: 8 Vector__XXX
 SG_ InstantaneousCombTimingPoint2 : 48|16@1+ (0.00390625,-125) [-125|125.99609375] "deg" Vector__XXX
 SG_ InstantaneousCombTimingPoint1 : 32|16@1+ (0.00390625,-125) [-125|125.99609375] "deg" Vector__XXX
 SG_ InstantaneousCenterOfCombTiming : 16|16@1+ (0.00390625,-125) [-125|125.99609375] "deg" Vector__XXX
 SG_ InstantaneousStartOfCombTiming : 0|16@1+ (0.00390625,-125) [-125|125.99609375] "deg" Vector__XXX

BO_ 2364629246 ECCT8: 8 Vector__XXX
 SG_ InstantaneousCombTimingPoint2 : 48|16@1+ (0.00390625,-125) [-125|125.99609375] "deg" Vector__XXX
 SG_ InstantaneousCombTimingPoint1 : 32|16@1+ (0.00390625,-125) [-125|125.99609375] "deg" Vector__XXX
 SG_ InstantaneousCenterOfCombTiming : 16|16@1+ (0.00390625,-125) [-125|125.99609375] "deg" Vector__XXX
 SG_ InstantaneousStartOfCombTiming : 0|16@1+ (0.00390625,-125) [-125|125.99609375] "deg" Vector__XXX

BO_ 2364628990 ECCT7: 8 Vector__XXX
 SG_ InstantaneousCombTimingPoint2 : 48|16@1+ (0.00390625,-125) [-125|125.99609375] "deg" Vector__XXX
 SG_ InstantaneousCombTimingPoint1 : 32|16@1+ (0.00390625,-125) [-125|125.99609375] "deg" Vector__XXX
 SG_ InstantaneousCenterOfCombTiming : 16|16@1+ (0.00390625,-125) [-125|125.99609375] "deg" Vector__XXX
 SG_ InstantaneousStartOfCombTiming : 0|16@1+ (0.00390625,-125) [-125|125.99609375] "deg" Vector__XXX

BO_ 2364628734 ECCT6: 8 Vector__XXX
 SG_ InstantaneousCombTimingPoint2 : 48|16@1+ (0.00390625,-125) [-125|125.99609375] "deg" Vector__XXX
 SG_ InstantaneousCombTimingPoint1 : 32|16@1+ (0.00390625,-125) [-125|125.99609375] "deg" Vector__XXX
 SG_ InstantaneousCenterOfCombTiming : 16|16@1+ (0.00390625,-125) [-125|125.99609375] "deg" Vector__XXX
 SG_ InstantaneousStartOfCombTiming : 0|16@1+ (0.00390625,-125) [-125|125.99609375] "deg" Vector__XXX

BO_ 2364628478 ECCT5: 8 Vector__XXX
 SG_ InstantaneousCombTimingPoint2 : 48|16@1+ (0.00390625,-125) [-125|125.99609375] "deg" Vector__XXX
 SG_ InstantaneousCombTimingPoint1 : 32|16@1+ (0.00390625,-125) [-125|125.99609375] "deg" Vector__XXX
 SG_ InstantaneousCenterOfCombTiming : 16|16@1+ (0.00390625,-125) [-125|125.99609375] "deg" Vector__XXX
 SG_ InstantaneousStartOfCombTiming : 0|16@1+ (0.00390625,-125) [-125|125.99609375] "deg" Vector__XXX

BO_ 2364628222 ECCT4: 8 Vector__XXX
 SG_ InstantaneousCombTimingPoint2 : 48|16@1+ (0.00390625,-125) [-125|125.99609375] "deg" Vector__XXX
 SG_ InstantaneousCombTimingPoint1 : 32|16@1+ (0.00390625,-125) [-125|125.99609375] "deg" Vector__XXX
 SG_ InstantaneousCenterOfCombTiming : 16|16@1+ (0.00390625,-125) [-125|125.99609375] "deg" Vector__XXX
 SG_ InstantaneousStartOfCombTiming : 0|16@1+ (0.00390625,-125) [-125|125.99609375] "deg" Vector__XXX

BO_ 2364627966 ECCT3: 8 Vector__XXX
 SG_ InstantaneousCombTimingPoint2 : 48|16@1+ (0.00390625,-125) [-125|125.99609375] "deg" Vector__XXX
 SG_ InstantaneousCombTimingPoint1 : 32|16@1+ (0.00390625,-125) [-125|125.99609375] "deg" Vector__XXX
 SG_ InstantaneousCenterOfCombTiming : 16|16@1+ (0.00390625,-125) [-125|125.99609375] "deg" Vector__XXX
 SG_ InstantaneousStartOfCombTiming : 0|16@1+ (0.00390625,-125) [-125|125.99609375] "deg" Vector__XXX

BO_ 2364627710 ECCT2: 8 Vector__XXX
 SG_ InstantaneousCombTimingPoint2 : 48|16@1+ (0.00390625,-125) [-125|125.99609375] "deg" Vector__XXX
 SG_ InstantaneousCombTimingPoint1 : 32|16@1+ (0.00390625,-125) [-125|125.99609375] "deg" Vector__XXX
 SG_ InstantaneousCenterOfCombTiming : 16|16@1+ (0.00390625,-125) [-125|125.99609375] "deg" Vector__XXX
 SG_ InstantaneousStartOfCombTiming : 0|16@1+ (0.00390625,-125) [-125|125.99609375] "deg" Vector__XXX

BO_ 2364627454 ECCT1: 8 Vector__XXX
 SG_ InstantaneousCombTimingPoint2 : 48|16@1+ (0.00390625,-125) [-125|125.99609375] "deg" Vector__XXX
 SG_ InstantaneousCombTimingPoint1 : 32|16@1+ (0.00390625,-125) [-125|125.99609375] "deg" Vector__XXX
 SG_ InstantaneousCenterOfCombTiming : 16|16@1+ (0.00390625,-125) [-125|125.99609375] "deg" Vector__XXX
 SG_ InstantaneousStartOfCombTiming : 0|16@1+ (0.00390625,-125) [-125|125.99609375] "deg" Vector__XXX

BO_ 2364627198 ECCP20: 8 Vector__XXX
 SG_ Timing4Press : 48|16@1+ (0.0009765625,0) [0|62.7490234375] "MPa" Vector__XXX
 SG_ Timing3Press : 32|16@1+ (0.0009765625,0) [0|62.7490234375] "MPa" Vector__XXX
 SG_ Timing2Press : 16|16@1+ (0.0009765625,0) [0|62.7490234375] "MPa" Vector__XXX
 SG_ Timing1Press : 0|16@1+ (0.0009765625,0) [0|62.7490234375] "MPa" Vector__XXX

BO_ 2364626942 ECCP19: 8 Vector__XXX
 SG_ Timing4Press : 48|16@1+ (0.0009765625,0) [0|62.7490234375] "MPa" Vector__XXX
 SG_ Timing3Press : 32|16@1+ (0.0009765625,0) [0|62.7490234375] "MPa" Vector__XXX
 SG_ Timing2Press : 16|16@1+ (0.0009765625,0) [0|62.7490234375] "MPa" Vector__XXX
 SG_ Timing1Press : 0|16@1+ (0.0009765625,0) [0|62.7490234375] "MPa" Vector__XXX

BO_ 2364626686 ECCP18: 8 Vector__XXX
 SG_ Timing4Press : 48|16@1+ (0.0009765625,0) [0|62.7490234375] "MPa" Vector__XXX
 SG_ Timing3Press : 32|16@1+ (0.0009765625,0) [0|62.7490234375] "MPa" Vector__XXX
 SG_ Timing2Press : 16|16@1+ (0.0009765625,0) [0|62.7490234375] "MPa" Vector__XXX
 SG_ Timing1Press : 0|16@1+ (0.0009765625,0) [0|62.7490234375] "MPa" Vector__XXX

BO_ 2364626430 ECCP17: 8 Vector__XXX
 SG_ Timing4Press : 48|16@1+ (0.0009765625,0) [0|62.7490234375] "MPa" Vector__XXX
 SG_ Timing3Press : 32|16@1+ (0.0009765625,0) [0|62.7490234375] "MPa" Vector__XXX
 SG_ Timing2Press : 16|16@1+ (0.0009765625,0) [0|62.7490234375] "MPa" Vector__XXX
 SG_ Timing1Press : 0|16@1+ (0.0009765625,0) [0|62.7490234375] "MPa" Vector__XXX

BO_ 2364626174 ECCP16: 8 Vector__XXX
 SG_ Timing4Press : 48|16@1+ (0.0009765625,0) [0|62.7490234375] "MPa" Vector__XXX
 SG_ Timing3Press : 32|16@1+ (0.0009765625,0) [0|62.7490234375] "MPa" Vector__XXX
 SG_ Timing2Press : 16|16@1+ (0.0009765625,0) [0|62.7490234375] "MPa" Vector__XXX
 SG_ Timing1Press : 0|16@1+ (0.0009765625,0) [0|62.7490234375] "MPa" Vector__XXX

BO_ 2364625918 ECCP15: 8 Vector__XXX
 SG_ Timing4Press : 48|16@1+ (0.0009765625,0) [0|62.7490234375] "MPa" Vector__XXX
 SG_ Timing3Press : 32|16@1+ (0.0009765625,0) [0|62.7490234375] "MPa" Vector__XXX
 SG_ Timing2Press : 16|16@1+ (0.0009765625,0) [0|62.7490234375] "MPa" Vector__XXX
 SG_ Timing1Press : 0|16@1+ (0.0009765625,0) [0|62.7490234375] "MPa" Vector__XXX

BO_ 2364625662 ECCP14: 8 Vector__XXX
 SG_ Timing4Press : 48|16@1+ (0.0009765625,0) [0|62.7490234375] "MPa" Vector__XXX
 SG_ Timing3Press : 32|16@1+ (0.0009765625,0) [0|62.7490234375] "MPa" Vector__XXX
 SG_ Timing2Press : 16|16@1+ (0.0009765625,0) [0|62.7490234375] "MPa" Vector__XXX
 SG_ Timing1Press : 0|16@1+ (0.0009765625,0) [0|62.7490234375] "MPa" Vector__XXX

BO_ 2364625406 ECCP13: 8 Vector__XXX
 SG_ Timing4Press : 48|16@1+ (0.0009765625,0) [0|62.7490234375] "MPa" Vector__XXX
 SG_ Timing3Press : 32|16@1+ (0.0009765625,0) [0|62.7490234375] "MPa" Vector__XXX
 SG_ Timing2Press : 16|16@1+ (0.0009765625,0) [0|62.7490234375] "MPa" Vector__XXX
 SG_ Timing1Press : 0|16@1+ (0.0009765625,0) [0|62.7490234375] "MPa" Vector__XXX

BO_ 2364625150 ECCP12: 8 Vector__XXX
 SG_ Timing4Press : 48|16@1+ (0.0009765625,0) [0|62.7490234375] "MPa" Vector__XXX
 SG_ Timing3Press : 32|16@1+ (0.0009765625,0) [0|62.7490234375] "MPa" Vector__XXX
 SG_ Timing2Press : 16|16@1+ (0.0009765625,0) [0|62.7490234375] "MPa" Vector__XXX
 SG_ Timing1Press : 0|16@1+ (0.0009765625,0) [0|62.7490234375] "MPa" Vector__XXX

BO_ 2364624894 ECCP11: 8 Vector__XXX
 SG_ Timing4Press : 48|16@1+ (0.0009765625,0) [0|62.7490234375] "MPa" Vector__XXX
 SG_ Timing3Press : 32|16@1+ (0.0009765625,0) [0|62.7490234375] "MPa" Vector__XXX
 SG_ Timing2Press : 16|16@1+ (0.0009765625,0) [0|62.7490234375] "MPa" Vector__XXX
 SG_ Timing1Press : 0|16@1+ (0.0009765625,0) [0|62.7490234375] "MPa" Vector__XXX

BO_ 2364624638 ECCP10: 8 Vector__XXX
 SG_ Timing4Press : 48|16@1+ (0.0009765625,0) [0|62.7490234375] "MPa" Vector__XXX
 SG_ Timing3Press : 32|16@1+ (0.0009765625,0) [0|62.7490234375] "MPa" Vector__XXX
 SG_ Timing2Press : 16|16@1+ (0.0009765625,0) [0|62.7490234375] "MPa" Vector__XXX
 SG_ Timing1Press : 0|16@1+ (0.0009765625,0) [0|62.7490234375] "MPa" Vector__XXX

BO_ 2364624382 ECCP9: 8 Vector__XXX
 SG_ Timing4Press : 48|16@1+ (0.0009765625,0) [0|62.7490234375] "MPa" Vector__XXX
 SG_ Timing3Press : 32|16@1+ (0.0009765625,0) [0|62.7490234375] "MPa" Vector__XXX
 SG_ Timing2Press : 16|16@1+ (0.0009765625,0) [0|62.7490234375] "MPa" Vector__XXX
 SG_ Timing1Press : 0|16@1+ (0.0009765625,0) [0|62.7490234375] "MPa" Vector__XXX

BO_ 2364624126 ECCP8: 8 Vector__XXX
 SG_ Timing4Press : 48|16@1+ (0.0009765625,0) [0|62.7490234375] "MPa" Vector__XXX
 SG_ Timing3Press : 32|16@1+ (0.0009765625,0) [0|62.7490234375] "MPa" Vector__XXX
 SG_ Timing2Press : 16|16@1+ (0.0009765625,0) [0|62.7490234375] "MPa" Vector__XXX
 SG_ Timing1Press : 0|16@1+ (0.0009765625,0) [0|62.7490234375] "MPa" Vector__XXX

BO_ 2364623870 ECCP7: 8 Vector__XXX
 SG_ Timing4Press : 48|16@1+ (0.0009765625,0) [0|62.7490234375] "MPa" Vector__XXX
 SG_ Timing3Press : 32|16@1+ (0.0009765625,0) [0|62.7490234375] "MPa" Vector__XXX
 SG_ Timing2Press : 16|16@1+ (0.0009765625,0) [0|62.7490234375] "MPa" Vector__XXX
 SG_ Timing1Press : 0|16@1+ (0.0009765625,0) [0|62.7490234375] "MPa" Vector__XXX

BO_ 2364623614 ECCP6: 8 Vector__XXX
 SG_ Timing4Press : 48|16@1+ (0.0009765625,0) [0|62.7490234375] "MPa" Vector__XXX
 SG_ Timing3Press : 32|16@1+ (0.0009765625,0) [0|62.7490234375] "MPa" Vector__XXX
 SG_ Timing2Press : 16|16@1+ (0.0009765625,0) [0|62.7490234375] "MPa" Vector__XXX
 SG_ Timing1Press : 0|16@1+ (0.0009765625,0) [0|62.7490234375] "MPa" Vector__XXX

BO_ 2364623358 ECCP5: 8 Vector__XXX
 SG_ Timing4Press : 48|16@1+ (0.0009765625,0) [0|62.7490234375] "MPa" Vector__XXX
 SG_ Timing3Press : 32|16@1+ (0.0009765625,0) [0|62.7490234375] "MPa" Vector__XXX
 SG_ Timing2Press : 16|16@1+ (0.0009765625,0) [0|62.7490234375] "MPa" Vector__XXX
 SG_ Timing1Press : 0|16@1+ (0.0009765625,0) [0|62.7490234375] "MPa" Vector__XXX

BO_ 2364623102 ECCP4: 8 Vector__XXX
 SG_ Timing4Press : 48|16@1+ (0.0009765625,0) [0|62.7490234375] "MPa" Vector__XXX
 SG_ Timing3Press : 32|16@1+ (0.0009765625,0) [0|62.7490234375] "MPa" Vector__XXX
 SG_ Timing2Press : 16|16@1+ (0.0009765625,0) [0|62.7490234375] "MPa" Vector__XXX
 SG_ Timing1Press : 0|16@1+ (0.0009765625,0) [0|62.7490234375] "MPa" Vector__XXX

BO_ 2364622846 ECCP3: 8 Vector__XXX
 SG_ Timing4Press : 48|16@1+ (0.0009765625,0) [0|62.7490234375] "MPa" Vector__XXX
 SG_ Timing3Press : 32|16@1+ (0.0009765625,0) [0|62.7490234375] "MPa" Vector__XXX
 SG_ Timing2Press : 16|16@1+ (0.0009765625,0) [0|62.7490234375] "MPa" Vector__XXX
 SG_ Timing1Press : 0|16@1+ (0.0009765625,0) [0|62.7490234375] "MPa" Vector__XXX

BO_ 2364622590 ECCP2: 8 Vector__XXX
 SG_ Timing4Press : 48|16@1+ (0.0009765625,0) [0|62.7490234375] "MPa" Vector__XXX
 SG_ Timing3Press : 32|16@1+ (0.0009765625,0) [0|62.7490234375] "MPa" Vector__XXX
 SG_ Timing2Press : 16|16@1+ (0.0009765625,0) [0|62.7490234375] "MPa" Vector__XXX
 SG_ Timing1Press : 0|16@1+ (0.0009765625,0) [0|62.7490234375] "MPa" Vector__XXX

CM_ BO_ 2364643326 "High Voltage Energy Storage Pack 1 Status 1
Status data set 1 for High Voltage Energy Storage Pack 1.";
CM_ SG_ 2364643326 Status1CRC "The CRC is defined as follows:
• Length: 8 bits
• Polynomial: x^8+x^5+x^3+x^2+x+1
• Initial Value: FFh
• Input Data Reflection: Not reflected
• Result Data Reflection: Not reflected
• XOR value: FFh
SAE makes no claim of the functional safety ...";
CM_ SG_ 2364643326 Status1Counter "The message counter is used to detect situations where the transmitting ECU malfunction repeats the same frame all the time. The receiver of the information may use the counter parameter to detect this situation. The transmitting device will ...";
CM_ SG_ 2364643326 OperationalStatus "Provides feedback on where this High Voltage Energy Storage Pack instance is in its operating spectrum, and includes feedback in response to the Operation Consent [i.e. SPN 11035 (HVESP1 Operation Consent)] and Power Down Command [i.e. SPN 11030 ...";
CM_ SG_ 2364643326 HVBusConnectionStatus "This parameter provides high level feedback on this High Voltage Energy Storage Pack instance high voltage bus connection.  For specific contactor information, see SPN 11075 (HVESP1 High-Voltage Bus (Positive) Contactor State), SPN 11076 (HVESP1 ...";
CM_ SG_ 2364643326 InternalChargerStatus "Indicates that the charger in this HVES instance is on.  External chargers may use the External Energy Source Connection Status (SPN 7898) and related SPs.
This parameter is for one of multiple packs in an HVESS. If there is only one pack in the ...";
CM_ SG_ 2364643326 CellBalancingActive "Indicates whether or not the cells in this High Voltage Energy Storage Pack instance are currently being balanced.
This parameter is for one of multiple packs in an HVESS.  If there is only one pack in the system, the HVESS parameters should be ...";
CM_ SG_ 2364643326 CellBalanceStatus "Indicates whether or not the cells in this High Voltage Energy Storage Pack instance are balanced.
This parameter is for one of multiple packs in an HVESS.  If there is only one pack in the system, the HVESS parameters should be used. If there are ...";
CM_ SG_ 2364643326 StOfChargeStatus "Status of this High Voltage Energy Storage Pack instance State of Charge (SOC).  Note:  A given HVES controller may not support all of the states.
This parameter is for one of multiple packs in an HVESS.  If there is only one pack in the system, ...";
CM_ SG_ 2364643326 InertiaSwStatus "Switch indicating that an impact has been sensed by this High Voltage Energy Storage Pack instance. The impact indication may require action by another controller, or by this HVES instance itself.  For example, a controller may elect to take this ...";
CM_ SG_ 2364643326 HVILStatus "Status of the High Voltage Interlock Loop from the viewpoint of this High Voltage Energy Storage Pack instance.
This parameter is for one of multiple packs in an HVESS. If there is only one pack in the system, the HVESS parameters should be used ...";
CM_ SG_ 2364643326 HVBusPassiveIsolTestStatus "Status of the high-voltage bus electrical passive isolation test as performed by this High Voltage Energy Storage Pack instance.
This parameter is for one of multiple packs in an HVESS. If there is only one pack in the system, the HVESS parameters ...";
CM_ SG_ 2364643326 HVBusActiveIsolTestStatus "Status of the high-voltage bus electrical active isolation test as performed by this High Voltage Energy Storage Pack instance.
This parameter is for one of multiple packs in an HVESS. If there is only one pack in the system, the HVESS parameters ...";
CM_ SG_ 2364643326 CenterOfPackContactorSt "Position of the center high-voltage contactor.  When this contactor is closed, the positive half of this High Voltage Energy Storage Pack instance is connected to the negative half.  If a system controls the positive, negative, and center contactors ...";
CM_ SG_ 2364643326 HVBusPreChargeRelaySt "Position of the high-voltage bus contactor pre-charge relay.  When this relay is closed, this High Voltage Energy Storage Pack instance is bringing the high-voltage bus up to its operating level.
This parameter is for one of multiple packs in an ...";
CM_ SG_ 2364643326 HVBusDisconnectForewarning "Indicates that this High Voltage Energy Storage Pack instance is about to disconnect from the high voltage bus due to unacceptable conditions.
This parameter is for one of multiple packs in an HVESS. If there is only one pack in the system, the ...";
CM_ SG_ 2364643326 HVBusContactorSt11076 "Position of this High Voltage Energy Storage Pack instance negative side bus contactor.  When this contactor is closed, the negative side of this HVES instance is connected to the negative side of the high-voltage bus.  If a system controls the ...";
CM_ SG_ 2364643326 HVBusContactorSt "Position of this High Voltage Energy Storage Pack instance positive side bus contactor.  When this contactor is closed, the positive side of this HVES instance is connected to the positive side of the high-voltage bus.  In systems where all ...";
CM_ BO_ 2364643070 "High Voltage Energy Storage Pack 1 Data 6
Data set 6 (external or interface data) for High Voltage Energy Storage Pack 1.";
CM_ SG_ 2364643070 Temp "The temperature of this High Voltage Energy Storage Pack instance. The value may be determined from a unique sensor specifically for this purpose, or by aggregating various temperature sensor readings within the pack.
This parameter is for one of ...";
CM_ SG_ 2364643070 ETemp "The temperature of the electronics or control modules in this High Voltage Energy Storage Pack instance.  If there are multiple temperature sensors then this parameter would be set to the maximum sensor reading.
This parameter is for one of ...";
CM_ SG_ 2364643070 OutCoolantTemp "The temperature of liquid coolant as it exits this High Voltage Energy Storage Pack instance.
This parameter is for one of multiple packs in an HVESS.  If there is only one pack in the system, the HVESS parameters should be used. If there are ...";
CM_ SG_ 2364643070 InCoolantTemp "The temperature of liquid coolant as it enters this High Voltage Energy Storage Pack instance.
This parameter is for one of multiple packs in an HVESS.  If there is only one pack in the system, the HVESS parameters should be used. If there are ...";
CM_ SG_ 2364643070 IgntV "The voltage level at the ignition input of this High Voltage Energy Storage Pack controller.
This parameter is for one of multiple packs in an HVESS.  If there is only one pack in the system, the HVESS parameters should be used.  If there are ...";
CM_ SG_ 2364643070 BusV "The voltage level of the high voltage bus, as measured by this High Voltage Energy Storage Pack instance on the bus side (not the battery side) of its contactors.
This parameter is for one of multiple packs in an HVESS.  If there is only one pack ...";
CM_ BO_ 2364642814 "High Voltage Energy Storage Pack 1 Data 5
Data set 5 (electrical data) for High Voltage Energy Storage Pack 1.";
CM_ SG_ 2364642814 HighestCellStOfCharge "Indicates the state of charge of the highest-charged cell in this High Voltage Energy Storage Pack instance.  0% means no charge remaining, 100% means the cell is fully charged.  If a single state of charge value covers more than one cell, the value ...";
CM_ SG_ 2364642814 LowestCellStOfCharge "Indicates the state of charge of the lowest-charged cell in this High Voltage Energy Storage Pack instance.  0% means no charge remaining, 100% means the cell is fully charged.   If a single state of charge value covers more than one cell, the value ...";
CM_ SG_ 2364642814 ChargeCurLmt "The maximum instantaneous current flow limit into this High Voltage Energy Storage Pack instance. This parameter is defined from the high voltage energy storage pack's point of view and should reflect the instantaneous capability of the pack.  The ...";
CM_ SG_ 2364642814 DisCurLmt "The maximum instantaneous current flow limit out of this High Voltage Energy Storage Pack instance. This parameter is defined from the high voltage energy storage pack's point of view and should reflect the instantaneous capability of the pack.  The ...";
CM_ BO_ 2364642558 "High Voltage Energy Storage Pack 1 Data 4
Data set 4 (electrical data) for High Voltage Energy Storage Pack 1.";
CM_ SG_ 2364642558 CellBalancingCount "The number of cells that are currently being balanced in this High Voltage Energy Storage Pack instance.
This parameter is for one of multiple packs in an HVESS.  If there is only one pack in the system, the HVESS parameters should be used.  If ...";
CM_ SG_ 2364642558 ChargeCapacity "The amount of unused electrical charge storage in this High Voltage Energy Storage Pack instance that is available to be filled by charging, i.e. “how much empty space is remaining in the tank”.  See SPN 11091 (HVESP1 Charge Energy Capacity) for ...";
CM_ SG_ 2364642558 DisCapacity "The amount of stored electrical charge in this High Voltage Energy Storage Pack instance that is available for use by the hybrid system, i.e. “how full is the tank”.  See SPN 11090 (HVESP1 Discharge Energy Capacity) for kilowatt-hours (kWh).
This ...";
CM_ BO_ 2364642302 "High Voltage Energy Storage Pack 1 Data 3
Data set 3 (thermal data) for High Voltage Energy Storage Pack 1.";
CM_ SG_ 2364642302 CellTempDiffStatus "Indicates whether or not the differential between the highest and lowest cell temperatures are within acceptable limits per this High Voltage Energy Storage Pack instance.  The actual temperature differential can be calculated by subtracting SPN ...";
CM_ SG_ 2364642302 AvgCellTemp "The average temperature level of all cells in this High Voltage Energy Storage Pack instance.
This parameter is for one of multiple packs in an HVESS.  If there is only one pack in the system, the HVESS parameters should be used.  If there are ...";
CM_ SG_ 2364642302 LowestCellTemp "The lowest temperature level reported by any cell in this High Voltage Energy Storage Pack instance.  If a single temperature sensor covers more than one cell, the value in this parameter is for the smallest group of cells measured.  See SPN 11122 ...";
CM_ SG_ 2364642302 HighestCellTemp "The highest temperature level reported by any cell in this High Voltage Energy Storage Pack instance.  If a single temperature sensor covers more than one cell, the value in this parameter is for the smallest group of cells measured.   See SPN 11120 ...";
CM_ BO_ 2364642046 "High Voltage Energy Storage Pack 1 Data 2
Data set 2 (electrical data) for High Voltage Energy Storage Pack 1.";
CM_ SG_ 2364642046 CellVDiffStatus "Indicates whether or not the differential between the highest and lowest cell voltages are within acceptable limits, according to this High Voltage Energy Storage Pack instance. The actual voltage differential can be calculated by subtracting SPN ...";
CM_ SG_ 2364642046 LowestCellV "The lowest voltage level reported by any cell in this High Voltage Energy Storage Pack instance. If a single voltage sensor covers more than one cell, the value in this parameter is for the smallest group of cells measured.  See SPN 11117 (HVESP1 ...";
CM_ SG_ 2364642046 HighestCellV "The highest voltage level reported by any cell in this High Voltage Energy Storage Pack instance. If a single voltage sensor covers more than one cell, the value in this parameter is for the smallest group of cells measured. See SPN 11115 (HVESP1 ...";
CM_ SG_ 2364642046 FastUpdateStOfCharge "Indicates this High Voltage Energy Storage Pack instance state of charge.  0% means no charge remaining, 100% means the system is fully charged in terms of physical limits of this energy storage pack instance.  Acceptable state of charge upper and ...";
CM_ BO_ 2364641790 "High Voltage Energy Storage Pack 1 Data 1
Data set 1 (electrical data) for High Voltage Energy Storage Pack 1.";
CM_ SG_ 2364641790 Cur "The current in or out of this High Voltage Energy Storage Pack instance. This parameter should be synchronized with SPN 11052 (HVESP1 Voltage Level) such that a realized power value can be calculated.  This parameter is defined from the high voltage ...";
CM_ SG_ 2364641790 Lvl "The voltage level of this High Voltage Energy Storage Pack instance. This parameter should be synchronized with SPN 11053 (HVESP1 Current) such that a realized power value can be calculated.  If the HVES component physically contains the contactors ...";
CM_ SG_ 2364641790 AvailableChargePwr "The rate at which this High Voltage Energy Storage Pack instance can currently receive energy from a regenerative or recharging system.
This parameter is for one of multiple packs in an HVESS.  If there is only one pack in the system, the HVESS ...";
CM_ SG_ 2364641790 AvailableDisPwr "The rate at which this High Voltage Energy Storage Pack instance can currently provide energy for propulsion or other uses.
This parameter is for one of multiple packs in an HVESS.  If there is only one pack in the system, the HVESS parameters ...";
CM_ BO_ 2364641534 "High Voltage Energy Storage Pack 1 Status 2
Status data set 2 for High Voltage Energy Storage Pack 1.";
CM_ SG_ 2364641534 ChargePLDueToAnUndefinedCause "Indicates whether or not charge power of this HVES instance is being limited due to an undefined cause.
This parameter is for one of multiple packs in an HVESS.  If there is only one pack in the system, the HVESS parameters should be used. If there ...";
CM_ SG_ 2364641534 ChargePLDueToBatCur "Indicates whether or not charge power of this HVES instance is being limited due to battery current.
This parameter is for one of multiple packs in an HVESS.  If there is only one pack in the system, the HVESS parameters should be used. If there ...";
CM_ SG_ 2364641534 ChargePLDueToBatOrCellV "Indicates whether or not charge power of this HVES instance is being limited due to a battery or cell voltage level.
This parameter is for one of multiple packs in an HVESS.  If there is only one pack in the system, the HVESS parameters should be ...";
CM_ SG_ 2364641534 ChargePLDueToBatDiagCondition "Indicates whether or not charge power of this HVES instance is being limited due to a battery diagnostic condition.
This parameter is for one of multiple packs in an HVESS.  If there is only one pack in the system, the HVESS parameters should be ...";
CM_ SG_ 2364641534 ChargePLDueToBatTemp "Indicates whether or not charge power of this HVES instance is being limited due to battery temperature.
This parameter is for one of multiple packs in an HVESS.  If there is only one pack in the system, the HVESS parameters should be used. If ...";
CM_ SG_ 2364641534 ChargePLDueToStOfCharge "Indicates whether or not charge power of this HVES instance is being limited due to state of charge.
This parameter is for one of multiple packs in an HVESS.  If there is only one pack in the system, the HVESS parameters should be used. If there ...";
CM_ SG_ 2364641534 DisPLDueToAnUndefinedCause "Indicates whether or not discharge power of this HVES instance is being limited due to an undefined cause.
This parameter is for one of multiple packs in an HVESS.  If there is only one pack in the system, the HVESS parameters should be used. If ...";
CM_ SG_ 2364641534 DisPLDueToBatCur "Indicates whether or not discharge power of this HVES instance is being limited due to battery current.
This parameter is for one of multiple packs in an HVESS.  If there is only one pack in the system, the HVESS parameters should be used. If there ...";
CM_ SG_ 2364641534 DisPLDueToBatOrCellV "Indicates whether or not discharge power of this HVES instance is being limited due to a battery or cell voltage level.
This parameter is for one of multiple packs in an HVESS.  If there is only one pack in the system, the HVESS parameters should ...";
CM_ SG_ 2364641534 DisPLDueToBatDiagCondition "Indicates whether or not discharge power of this HVES instance is being limited due to a battery diagnostic condition.
This parameter is for one of multiple packs in an HVESS.  If there is only one pack in the system, the HVESS parameters should be ...";
CM_ SG_ 2364641534 DisPLDueToBatTemp "Indicates whether or not discharge power of this HVES instance is being limited due to battery temperature.
This parameter is for one of multiple packs in an HVESS.  If there is only one pack in the system, the HVESS parameters should be used. If ...";
CM_ SG_ 2364641534 DisPLDueToStOfCharge "Indicates whether or not discharge power of this HVES instance is being limited due to state of charge.
This parameter is for one of multiple packs in an HVESS.  If there is only one pack in the system, the HVESS parameters should be used. If there ...";
CM_ BO_ 2297532414 "Impostor PG Alert
An \"impostor\" is defined as a network component broadcasting messages from a source address that has already been successfully and rightfully claimed by an existing network component. The unexpected duplicate communication could ...";
CM_ SG_ 2297532414 TimeSinceLastImposterPGDetected "For the given impostor PG being reported on, this parameter indicates how much time has elapsed since the impostor PG instance was last detected during the current ECU power cycle, i.e. when the last attack ended. See SPN 10840 for details on how to ...";
CM_ SG_ 2297532414 PGN "This parameter identifies an unexpected duplicate PG (message) being broadcast from a source address that is already rightfully claimed. If no impostor PG(s) have been detected, each byte of this parameter shall be set to a value of 255.";
CM_ SG_ 2297532414 DestinationAddress "Indicates the destination address to which the impostor is broadcasting the detected PG. If no impostor PG(s) have been detected, this parameter shall be set to a value of 254.";
CM_ SG_ 2297532414 SA "Indicates the source address from which an impostor is broadcasting the detected PG. If no impostor PG(s) have been detected, this parameter shall be set to a value of 254.";
CM_ SG_ 2297532414 EventDetectionCounter "For a given detected impostor PG being reported on, this parameter indicates the number of impostor message sequences that have been detected by the legitimate sender since the counter was last reset.
The counter increments on the first detection ...";
CM_ BO_ 2565967614 "Motor/Generator 2 Inverter Rate Limits Active 1
Reports the active rate limits for this instance of inverter being controlled. Some examples of use would be for a hybrid or electric vehicle propulsion motor or generator.";
CM_ SG_ 2565967614 AbsTrqRateLmt "The inverter reports its active maximum rate of change for the absolute motor torque (i.e. |d(torque)|/dt) in all control modes.
Refer to SPN 10236 [Reference Torque] to convert %/sec to Nm/sec.
(Torque Rate Limit in Nm/sec) = (Torque Rate Limit ...";
CM_ SG_ 2565967614 AbsSpdRateLmt "The Inverter reports its active maximum rate of change for the absolute motor speed  (i.e. |d(speed)|/dt) in all control modes.
Refer to SPN 10237 [Reference Speed] to convert %/sec to RPM/sec.
(Speed Rate Limit in rpm/sec) = (Speed Rate Limit in ...";
CM_ SG_ 2565967614 Counter "The message counter is used to detect situations where the transmitting ECU malfunction repeats the same frame all the time. The receiver of the information may use the counter parameter to detect this situation. The transmitting device will ...";
CM_ SG_ 2565967614 CRC "The CRC is defined as follows:
• Length: 8 bits
• Polynomial: x^8+x^5+x^3+x^2+x+1
• Initial Value: FFh
• Input Data Reflection: Not reflected
• Result Data Reflection: Not reflected
• XOR value: FFh
SAE makes no claim of the functional safety ...";
CM_ BO_ 2565967358 "Motor/Generator 2 Inverter Status 2
Second Status Message from the Inverter.  Some examples of use would be for a hybrid or electric vehicle propulsion motor or generator.";
CM_ SG_ 2565967358 AvailableMinTrq "This is an estimate of the minimum available motor torque including active deratings at the present motor speed.  This refers to the motor rotor output and excludes any gearbox that may be attached to the motor.
Refer to SPN 10236 [Reference ...";
CM_ SG_ 2565967358 AvailableMaxTrq "This is an estimate of the maximum available motor torque including active deratings at the present motor speed.  This refers to the motor rotor output and excludes any gearbox that may be attached to the motor.
Refer to SPN 10236 [Reference ...";
CM_ SG_ 2565967358 Counter "The message counter is used to detect situations where the transmitting ECU malfunction repeats the same frame all the time. The receiver of the information may use the counter parameter to detect this situation. The transmitting device will ...";
CM_ SG_ 2565967358 CRC "The CRC is defined as follows:
• Length: 8 bits
• Polynomial: x^8+x^5+x^3+x^2+x+1
• Initial Value: FFh
• Input Data Reflection: Not reflected
• Result Data Reflection: Not reflected
• XOR value: FFh
SAE makes no claim of the functional safety ...";
CM_ BO_ 2565967102 "Motor/Generator 1 Inverter Rate Limits Active 1
Reports the active rate limits for this instance of inverter being controlled. Some examples of use would be for a hybrid or electric vehicle propulsion motor or generator.";
CM_ SG_ 2565967102 AbsTrqRateLmt "The active maximum rate of change for the absolute motor torque (i.e. |d(torque)|/dt) in all control modes of this motor/generator inverter instance.
Refer to SPN 10170 [Reference Torque] to convert %/sec to Nm/sec.
(Torque Rate Limit in Nm/sec) = ...";
CM_ SG_ 2565967102 AbsSpdRateLmt "The active maximum rate of change for the absolute motor speed  (i.e. |d(speed)|/dt) in all control modes of this motor/generator inverter instance.
Refer to SPN 10171 [Reference Speed] to convert %/sec to RPM/sec.
(Speed Rate Limit in rpm/sec) = ...";
CM_ SG_ 2565967102 Counter "The message counter is used to detect situations where the transmitting ECU malfunction repeats the same frame all the time. The receiver of the information may use the counter parameter to detect this situation. The transmitting device will ...";
CM_ SG_ 2565967102 CRC "The CRC is defined as follows:
• Length: 8 bits
• Polynomial: x^8+x^5+x^3+x^2+x+1
• Initial Value: FFh
• Input Data Reflection: Not reflected
• Result Data Reflection: Not reflected
• XOR value: FFh
SAE makes no claim of the functional safety ...";
CM_ BO_ 2565966846 "Motor/Generator 1 Inverter Status 2
Second Status Message from the Inverter.  Some examples of use would be for a hybrid or electric vehicle propulsion motor or generator.";
CM_ SG_ 2565966846 AvailableMinTrq "This is an estimate of the minimum available motor torque including active deratings at the present motor speed.  This refers to the motor rotor output and excludes any gearbox that may be attached to the motor.
Refer to SPN 10170 [Reference ...";
CM_ SG_ 2565966846 AvailableMaxTrq "This is an estimate of the maximum available motor torque including active deratings at the present motor speed.  This refers to the motor rotor output and excludes any gearbox that may be attached to the motor.
Refer to SPN 10170 [Reference ...";
CM_ SG_ 2565966846 Counter "The message counter is used to detect situations where the transmitting ECU malfunction repeats the same frame all the time. The receiver of the information may use the counter parameter to detect this situation. The transmitting device will ...";
CM_ SG_ 2565966846 CRC "The CRC is defined as follows:
• Length: 8 bits
• Polynomial: x^8+x^5+x^3+x^2+x+1
• Initial Value: FFh
• Input Data Reflection: Not reflected
• Result Data Reflection: Not reflected
• XOR value: FFh
SAE makes no claim of the functional safety ...";
CM_ BO_ 2565966590 "Motor/Generator 2 Inverter Low Voltage
Low Voltage data from this Motor/Generator Inverter.";
CM_ SG_ 2565966590 UnswitchedSLIV "Continuously supplied SLI power to this instance of the inverter controller.";
CM_ SG_ 2565966590 SwitchedIgntV "Switched Ignition voltage supplied to this instance of the inverter controller.";
CM_ BO_ 2565966334 "Motor/Generator 2 Inverter Limits Active DC Side
The DC side electrical limits the inverter is actually using.  These may differ from the requested limits.";
CM_ SG_ 2565966334 CurMin "The inverter keeps the DC side current above this value.  This limit may be set in response to a Limits Request or determined by the inverter based on operating conditions.
Refer to SPN 10268 [Reference Current] to convert % to Amps.
While ...";
CM_ SG_ 2565966334 CurMax "The inverter keeps the DC side current below this value.  This limit may be set in response to a Limits Request or determined by the inverter based on operating conditions.
Refer to SPN 10268 [Reference Current] to convert % to Amps.
While ...";
CM_ SG_ 2565966334 VMin "The inverter keeps the DC side voltage above this value.  This limit may be set in response to a Limits Request or determined by the inverter based on operating conditions.
Refer to SPN 10269 [Reference Voltage] to convert % to Volts.
While DC ...";
CM_ SG_ 2565966334 VMax "The inverter keeps the DC side voltage below this value.  This limit may be set in response to a Limits Request or determined by the inverter based on operating conditions.
Refer to SPN 10269 [Reference Voltage] to convert % to Volts.
While DC ...";
CM_ SG_ 2565966334 Counter "The message counter is used to detect situations where the transmitting ECU malfunction repeats the same frame all the time. The receiver of the information may use the counter parameter to detect this situation. The transmitting device will ...";
CM_ SG_ 2565966334 CRC "The CRC is defined as follows:
• Length: 8 bits
• Polynomial: x^8+x^5+x^3+x^2+x+1
• Initial Value: FFh
• Input Data Reflection: Not reflected
• Result Data Reflection: Not reflected
• XOR value: FFh
SAE makes no claim of the functional safety ...";
CM_ BO_ 2565966078 "Motor/Generator 2 Inverter Limits Active Mechanical
The Torque and Speed limits the inverter is actually using.  These may differ from the requested limits.";
CM_ SG_ 2565966078 SpdMin "The inverter keeps the motor Speed above this value.  This limit may be set in response to a Limits Request or determined by the inverter based on operating conditions.

Refer to SPN 10237 [Reference Speed] to convert % to rpm.";
CM_ SG_ 2565966078 SpdMax "The inverter keeps the motor speed below this value.  This limit may be set in response to a Limits Request or determined by the inverter based on operating conditions.

Refer to SPN 10237 [Reference Speed] to convert % to rpm.";
CM_ SG_ 2565966078 TrqMin "The inverter keeps the motor torque above this value.  This limit may be set in response to a Limits Request or determined by the inverter based on operating conditions.

Refer to SPN 10236 [Reference Torque] to convert % to Nm.";
CM_ SG_ 2565966078 TrqMax "The inverter keeps the motor torque below this value.  This limit may be set in response to a Limits Request or determined by the inverter based on operating conditions.

Refer to SPN 10236 [Reference Torque] to convert % to Nm.";
CM_ SG_ 2565966078 Counter "The message counter is used to detect situations where the transmitting ECU malfunction repeats the same frame all the time. The receiver of the information may use the counter parameter to detect this situation. The transmitting device will ...";
CM_ SG_ 2565966078 CRC "The CRC is defined as follows:
• Length: 8 bits
• Polynomial: x^8+x^5+x^3+x^2+x+1
• Initial Value: FFh
• Input Data Reflection: Not reflected
• Result Data Reflection: Not reflected
• XOR value: FFh
SAE makes no claim of the functional safety ...";
CM_ BO_ 2565965822 "Motor/Generator 2 Inverter Limits Active Power
The electrical and mechanical power limits the inverter is actually using.  These may differ from the requested limits.";
CM_ SG_ 2565965822 DCSidePwrMin "The inverter keeps the DC side power above this value.   This limit may be set in response to a Limits Request or determined by the inverter based on operating conditions.
Refer to SPN 10238 [Reference Power] to convert % to kW.
For example, in a ...";
CM_ SG_ 2565965822 DCSidePwrMax "The inverter keeps the DC Side power below this value.   This limit may be set in response to a Limits Request or determined by the inverter based on operating conditions.
Refer to SPN 10238 [Reference Power] to convert % to kW.
For example, in a ...";
CM_ SG_ 2565965822 MechPwrMin "The inverter keeps the mechanical motor power above this value.   This limit may be set in response to a Limits Request or determined by the inverter based on operating conditions.
Refer to SPN 10238 [Reference Power] to convert % to kW.
For ...";
CM_ SG_ 2565965822 MechPwrMax "The inverter keeps the mechanical motor power below this value.   This limit may be set in response to a Limits Request or determined by the inverter based on operating conditions.
Refer to SPN 10238 [Reference Power] to convert % to kW.
For ...";
CM_ SG_ 2565965822 Counter "The message counter is used to detect situations where the transmitting ECU malfunction repeats the same frame all the time. The receiver of the information may use the counter parameter to detect this situation. The transmitting device will ...";
CM_ SG_ 2565965822 CRC "The CRC is defined as follows:
• Length: 8 bits
• Polynomial: x^8+x^5+x^3+x^2+x+1
• Initial Value: FFh
• Input Data Reflection: Not reflected
• Result Data Reflection: Not reflected
• XOR value: FFh
SAE makes no claim of the functional safety ...";
CM_ BO_ 2364638974 "Motor/Generator 2 Inverter Mode Feedback 1
The first mode feedback message from the inverter.";
CM_ SG_ 2364638974 HVILStatus "Reports the High Voltage Interlock Loop (HVIL) state.

00b = HVIL Closed
01b = HVIL Open
10b = Error
11b = Not Available";
CM_ SG_ 2364638974 CtrlSetpointMode "Reports the inverter mode (See SPN 10228 [Control Setpoint Mode Request] for requested mode).
Passive modes:
0 = Powered On - the inverter is commanded to be powered on and able to communicate, but the Power Stage is disabled e.g. no switching or ...";
CM_ SG_ 2364638974 CtrlLimitsOvrdMode "During normal operation this will have the same value as SPN 10225 [Control Limits Request Override Mode].
0 = Operating limits are not overridden.  If a limit was previously active, then it has reverted to its normal value as defined by its ...";
CM_ SG_ 2364638974 Counter "The message counter is used to detect situations where the transmitting ECU malfunction repeats the same frame all the time. The receiver of the information may use the counter parameter to detect this situation. The transmitting device will ...";
CM_ SG_ 2364638974 CRC "The CRC is defined as follows:
• Length: 8 bits
• Polynomial: x^8+x^5+x^3+x^2+x+1
• Initial Value: FFh
• Input Data Reflection: Not reflected
• Result Data Reflection: Not reflected
• XOR value: FFh
SAE makes no claim of the functional safety ...";
CM_ BO_ 2565965310 "Motor/Generator 1 Inverter Low Voltage
Low Voltage data from this Motor/Generator Inverter.";
CM_ SG_ 2565965310 UnswitchedSLIV "Continuously supplied SLI power to this instance of the inverter controller.";
CM_ SG_ 2565965310 SwitchedIgntV "Switched Ignition voltage supplied to this instance of the inverter controller.";
CM_ BO_ 2565965054 "Motor/Generator 1 Inverter Limits Active DC Side
The DC side electrical limits the inverter is actually using.  These may differ from the requested limits.";
CM_ SG_ 2565965054 CurMin "The inverter keeps the DC side current above this value.  This limit may be set in response to a Limits Request or determined by the inverter based on operating conditions.
Refer to SPN 10202 [Reference Current] to convert % to Amps.
While ...";
CM_ SG_ 2565965054 CurMax "The inverter keeps the DC side current below this value.  This limit may be set in response to a Limits Request or determined by the inverter based on operating conditions.
Refer to SPN 10202 [Reference Current] to convert % to Amps.
While ...";
CM_ SG_ 2565965054 VMin "The inverter keeps the DC side voltage above this value.  This limit may be set in response to a Limits Request or determined by the inverter based on operating conditions.
Refer to SPN 10203 [Reference Voltage] to convert % to Volts.
While DC ...";
CM_ SG_ 2565965054 VMax "The inverter keeps the DC side voltage below this value.  This limit may be set in response to a Limits Request or determined by the inverter based on operating conditions.
Refer to SPN 10203 [Reference Voltage] to convert % to Volts.
While DC ...";
CM_ SG_ 2565965054 Counter "The message counter is used to detect situations where the transmitting ECU malfunction repeats the same frame all the time. The receiver of the information may use the counter parameter to detect this situation. The transmitting device will ...";
CM_ SG_ 2565965054 CRC "The CRC is defined as follows:
• Length: 8 bits
• Polynomial: x^8+x^5+x^3+x^2+x+1
• Initial Value: FFh
• Input Data Reflection: Not reflected
• Result Data Reflection: Not reflected
• XOR value: FFh
SAE makes no claim of the functional safety ...";
CM_ BO_ 2565964798 "Motor/Generator 1 Inverter Limits Active Mechanical
The Torque and Speed limits the inverter is actually using.  These may differ from the requested limits.";
CM_ SG_ 2565964798 SpdMin "The inverter keeps the motor Speed above this value.  This limit may be set in response to a Limits Request or determined by the inverter based on operating conditions.

Refer to SPN 10171 [Reference Speed] to convert % to rpm.";
CM_ SG_ 2565964798 SpdMax "The inverter keeps the motor speed below this value.  This limit may be set in response to a Limits Request or determined by the inverter based on operating conditions.

Refer to SPN 10171 [Reference Speed] to convert % to rpm.";
CM_ SG_ 2565964798 TrqMin "The inverter keeps the motor torque above this value.  This limit may be set in response to a Limits Request or determined by the inverter based on operating conditions.

Refer to SPN 10170 [Reference Torque] to convert % to Nm.";
CM_ SG_ 2565964798 TrqMax "The inverter keeps the motor torque below this value.  This limit may be set in response to a Limits Request or determined by the inverter based on operating conditions.

Refer to SPN 10170 [Reference Torque] to convert % to Nm.";
CM_ SG_ 2565964798 Counter "The message counter is used to detect situations where the transmitting ECU malfunction repeats the same frame all the time. The receiver of the information may use the counter parameter to detect this situation. The transmitting device will ...";
CM_ SG_ 2565964798 CRC "The CRC is defined as follows:
• Length: 8 bits
• Polynomial: x^8+x^5+x^3+x^2+x+1
• Initial Value: FFh
• Input Data Reflection: Not reflected
• Result Data Reflection: Not reflected
• XOR value: FFh
SAE makes no claim of the functional safety ...";
CM_ BO_ 2565964542 "Motor/Generator 1 Inverter Limits Active Power
The electrical and mechanical power limits the inverter is actually using.  These may differ from the requested limits.";
CM_ SG_ 2565964542 DCSidePwrMin "The inverter keeps the DC side power above this value.   This limit may be set in response to a Limits Request or determined by the inverter based on operating conditions.
Refer to SPN 10172 [Reference Power] to convert % to kW.
For example, in a ...";
CM_ SG_ 2565964542 DCSidePwrMax "The inverter keeps the DC Side power below this value.   This limit may be set in response to a Limits Request or determined by the inverter based on operating conditions.
Refer to SPN 10172 [Reference Power] to convert % to kW.
For example, in a ...";
CM_ SG_ 2565964542 MechPwrMin "The inverter keeps the mechanical motor power above this value.   This limit may be set in response to a Limits Request or determined by the inverter based on operating conditions.
Refer to SPN 10172 [Reference Power] to convert % to kW.
For ...";
CM_ SG_ 2565964542 MechPwrMax "The inverter keeps the mechanical motor power below this value.   This limit may be set in response to a Limits Request or determined by the inverter based on operating conditions.
Refer to SPN 10172 [Reference Power] to convert % to kW.
For ...";
CM_ SG_ 2565964542 Counter "The message counter is used to detect situations where the transmitting ECU malfunction repeats the same frame all the time. The receiver of the information may use the counter parameter to detect this situation. The transmitting device will ...";
CM_ SG_ 2565964542 CRC "The CRC is defined as follows:
• Length: 8 bits
• Polynomial: x^8+x^5+x^3+x^2+x+1
• Initial Value: FFh
• Input Data Reflection: Not reflected
• Result Data Reflection: Not reflected
• XOR value: FFh
SAE makes no claim of the functional safety ...";
CM_ BO_ 2364637694 "Motor/Generator 1 Inverter Mode Feedback 1
The first mode feedback message from the inverter.";
CM_ SG_ 2364637694 HVILStatus "Reports the High Voltage Interlock Loop (HVIL) state.

00b = HVIL Closed
01b = HVIL Open
10b = Error
11b = Not Available";
CM_ SG_ 2364637694 CtrlSetpointMode "Reports the inverter mode (See SPN 10162 [Control Setpoint Mode Request] for requested mode).
Passive modes:
0 = Powered On - the inverter is commanded to be powered on and able to communicate, but the Power Stage is disabled e.g. no switching or ...";
CM_ SG_ 2364637694 CtrlLimitsOvrdMode "During normal operation this will have the same value as SPN 10159 [Control Limits Request Override Mode].
0 = Operating limits are not overridden.  If a limit was previously active, then it has reverted to its normal value as defined by its ...";
CM_ SG_ 2364637694 Counter "The message counter is used to detect situations where the transmitting ECU malfunction repeats the same frame all the time. The receiver of the information may use the counter parameter to detect this situation. The transmitting device will ...";
CM_ SG_ 2364637694 CRC "The CRC is defined as follows:
• Length: 8 bits
• Polynomial: x^8+x^5+x^3+x^2+x+1
• Initial Value: FFh
• Input Data Reflection: Not reflected
• Result Data Reflection: Not reflected
• XOR value: FFh
SAE makes no claim of the functional safety ...";
CM_ BO_ 2364637438 "Engine Cylinder 20 Combustion Metrics
Reports measurements of key combustion metrics for engine cylinder 20";
CM_ SG_ 2364637438 Temp "Gas temperature in cylinder measured at the cylinder head of cylinder 20.";
CM_ SG_ 2364637438 MisfireRate "The misfire rate of engine Cylinder 20 over the number of engine cycles in SPN6394 represented as a percentage.";
CM_ SG_ 2364637438 IndMeanEffPressCV "The indicated mean effective pressure coefficient of variance is the variability seen in IMEP over the number of engine cycles in SPN6394 represented as a percentage.";
CM_ SG_ 2364637438 InstantaneousIndMeanEffPress "The indicated mean effective pressure (IMEP) is the work delivered to the piston over the entire cycle, per unit displaced volume.  This SP reports for the current engine cycle.  See SPN 6559 for an average value.  Negative range is to cover ...";
CM_ SG_ 2364637438 InstantaneousPeakCombPressTiming "The timing in crank angle degrees of the observed peak pressure during the current combustion cycle.  When the combustion happens after the TDC (Top Dead Center) of this cylinder, the timing is referred in terms of positive angle and if combustion ...";
CM_ BO_ 2364637182 "Engine Cylinder 19 Combustion Metrics
Reports measurements of key combustion metrics for engine cylinder 19";
CM_ SG_ 2364637182 Temp "Gas temperature in cylinder measured at the cylinder head of cylinder 19.";
CM_ SG_ 2364637182 MisfireRate "The misfire rate of engine Cylinder 19 over the number of engine cycles in SPN6394 represented as a percentage.";
CM_ SG_ 2364637182 IndMeanEffPressCV "The indicated mean effective pressure coefficient of variance is the variability seen in IMEP over the number of engine cycles in SPN6394 represented as a percentage.";
CM_ SG_ 2364637182 InstantaneousIndMeanEffPress "The indicated mean effective pressure (IMEP) is the work delivered to the piston over the entire cycle, per unit displaced volume.  This SP reports for the current engine cycle.  See SPN 6555 for an average value.  Negative range is to cover ...";
CM_ SG_ 2364637182 InstantaneousPeakCombPressTiming "The timing in crank angle degrees of the observed peak pressure during the current combustion cycle.  When the combustion happens after the TDC (Top Dead Center) of this cylinder, the timing is referred in terms of positive angle and if combustion ...";
CM_ BO_ 2364636926 "Engine Cylinder 18 Combustion Metrics
Reports measurements of key combustion metrics for engine cylinder 18";
CM_ SG_ 2364636926 Temp "Gas temperature in cylinder measured at the cylinder head of cylinder 18.";
CM_ SG_ 2364636926 MisfireRate "The misfire rate of engine Cylinder 18 over the number of engine cycles in SPN6394 represented as a percentage.";
CM_ SG_ 2364636926 IndMeanEffPressCV "The indicated mean effective pressure coefficient of variance is the variability seen in IMEP over the number of engine cycles in SPN6394 represented as a percentage.";
CM_ SG_ 2364636926 InstantaneousIndMeanEffPress "The indicated mean effective pressure (IMEP) is the work delivered to the piston over the entire cycle, per unit displaced volume.  This SP reports for the current engine cycle.  See SPN 6551 for an average value.  Negative range is to cover ...";
CM_ SG_ 2364636926 InstantaneousPeakCombPressTiming "The timing in crank angle degrees of the observed peak pressure during the current combustion cycle.  When the combustion happens after the TDC (Top Dead Center) of this cylinder, the timing is referred in terms of positive angle and if combustion ...";
CM_ BO_ 2364636670 "Engine Cylinder 17 Combustion Metrics
Reports measurements of key combustion metrics for engine cylinder 17";
CM_ SG_ 2364636670 Temp "Gas temperature in cylinder measured at the cylinder head of cylinder 17.";
CM_ SG_ 2364636670 MisfireRate "The misfire rate of engine Cylinder 17 over the number of engine cycles in SPN6394 represented as a percentage.";
CM_ SG_ 2364636670 IndMeanEffPressCV "The indicated mean effective pressure coefficient of variance is the variability seen in IMEP over the number of engine cycles in SPN6394 represented as a percentage.";
CM_ SG_ 2364636670 InstantaneousIndMeanEffPress "The indicated mean effective pressure (IMEP) is the work delivered to the piston over the entire cycle, per unit displaced volume.  This SP reports for the current engine cycle.  See SPN 6547 for an average value.  Negative range is to cover ...";
CM_ SG_ 2364636670 InstantaneousPeakCombPressTiming "The timing in crank angle degrees of the observed peak pressure during the current combustion cycle.  When the combustion happens after the TDC (Top Dead Center) of this cylinder, the timing is referred in terms of positive angle and if combustion ...";
CM_ BO_ 2364636414 "Engine Cylinder 16 Combustion Metrics
Reports measurements of key combustion metrics for engine cylinder 16";
CM_ SG_ 2364636414 Temp "Gas temperature in cylinder measured at the cylinder head of cylinder 16.";
CM_ SG_ 2364636414 MisfireRate "The misfire rate of engine Cylinder 16 over the number of engine cycles in SPN6394 represented as a percentage.";
CM_ SG_ 2364636414 IndMeanEffPressCV "The indicated mean effective pressure coefficient of variance is the variability seen in IMEP over the number of engine cycles in SPN6394 represented as a percentage.";
CM_ SG_ 2364636414 InstantaneousIndMeanEffPress "The indicated mean effective pressure (IMEP) is the work delivered to the piston over the entire cycle, per unit displaced volume.  This SP reports for the current engine cycle.  See SPN 6543 for an average value.  Negative range is to cover ...";
CM_ SG_ 2364636414 InstantaneousPeakCombPressTiming "The timing in crank angle degrees of the observed peak pressure during the current combustion cycle.  When the combustion happens after the TDC (Top Dead Center) of this cylinder, the timing is referred in terms of positive angle and if combustion ...";
CM_ BO_ 2364636158 "Engine Cylinder 15 Combustion Metrics
Reports measurements of key combustion metrics for engine cylinder 15";
CM_ SG_ 2364636158 Temp "Gas temperature in cylinder measured at the cylinder head of cylinder 15.";
CM_ SG_ 2364636158 MisfireRate "The misfire rate of engine Cylinder 15 over the number of engine cycles in SPN6394 represented as a percentage.";
CM_ SG_ 2364636158 IndMeanEffPressCV "The indicated mean effective pressure coefficient of variance is the variability seen in IMEP over the number of engine cycles in SPN6394 represented as a percentage.";
CM_ SG_ 2364636158 InstantaneousIndMeanEffPress "The indicated mean effective pressure (IMEP) is the work delivered to the piston over the entire cycle, per unit displaced volume.  This SP reports for the current engine cycle.  See SPN 6539 for an average value.  Negative range is to cover ...";
CM_ SG_ 2364636158 InstantaneousPeakCombPressTiming "The timing in crank angle degrees of the observed peak pressure during the current combustion cycle.  When the combustion happens after the TDC (Top Dead Center) of this cylinder, the timing is referred in terms of positive angle and if combustion ...";
CM_ BO_ 2364635902 "Engine Cylinder 14 Combustion Metrics
Reports measurements of key combustion metrics for engine cylinder 14";
CM_ SG_ 2364635902 Temp "Gas temperature in cylinder measured at the cylinder head of cylinder 14.";
CM_ SG_ 2364635902 MisfireRate "The misfire rate of engine Cylinder 14 over the number of engine cycles in SPN6394 represented as a percentage.";
CM_ SG_ 2364635902 IndMeanEffPressCV "The indicated mean effective pressure coefficient of variance is the variability seen in IMEP over the number of engine cycles in SPN6394 represented as a percentage.";
CM_ SG_ 2364635902 InstantaneousIndMeanEffPress "The indicated mean effective pressure (IMEP) is the work delivered to the piston over the entire cycle, per unit displaced volume.  This SP reports for the current engine cycle.  See SPN 6535 for an average value.  Negative range is to cover ...";
CM_ SG_ 2364635902 InstantaneousPeakCombPressTiming "The timing in crank angle degrees of the observed peak pressure during the current combustion cycle.  When the combustion happens after the TDC (Top Dead Center) of this cylinder, the timing is referred in terms of positive angle and if combustion ...";
CM_ BO_ 2364635646 "Engine Cylinder 13 Combustion Metrics
Reports measurements of key combustion metrics for engine cylinder 13";
CM_ SG_ 2364635646 Temp "Gas temperature in cylinder measured at the cylinder head of cylinder 13.";
CM_ SG_ 2364635646 MisfireRate "The misfire rate of engine Cylinder 13 over the number of engine cycles in SPN6394 represented as a percentage.";
CM_ SG_ 2364635646 IndMeanEffPressCV "The indicated mean effective pressure coefficient of variance is the variability seen in IMEP over the number of engine cycles in SPN6394 represented as a percentage.";
CM_ SG_ 2364635646 InstantaneousIndMeanEffPress "The indicated mean effective pressure (IMEP) is the work delivered to the piston over the entire cycle, per unit displaced volume.  This SP reports for the current engine cycle.  See SPN 6531 for an average value.  Negative range is to cover ...";
CM_ SG_ 2364635646 InstantaneousPeakCombPressTiming "The timing in crank angle degrees of the observed peak pressure during the current combustion cycle.  When the combustion happens after the TDC (Top Dead Center) of this cylinder, the timing is referred in terms of positive angle and if combustion ...";
CM_ BO_ 2364635390 "Engine Cylinder 12 Combustion Metrics
Reports measurements of key combustion metrics for engine cylinder 12";
CM_ SG_ 2364635390 Temp "Gas temperature in cylinder measured at the cylinder head of cylinder 12.";
CM_ SG_ 2364635390 MisfireRate "The misfire rate of engine Cylinder 12 over the number of engine cycles in SPN6394 represented as a percentage.";
CM_ SG_ 2364635390 IndMeanEffPressCV "The indicated mean effective pressure coefficient of variance is the variability seen in IMEP over the number of engine cycles in SPN6394 represented as a percentage.";
CM_ SG_ 2364635390 InstantaneousIndMeanEffPress "The indicated mean effective pressure (IMEP) is the work delivered to the piston over the entire cycle, per unit displaced volume.  This SP reports for the current engine cycle.  See SPN 6527 for an average value.  Negative range is to cover ...";
CM_ SG_ 2364635390 InstantaneousPeakCombPressTiming "The timing in crank angle degrees of the observed peak pressure during the current combustion cycle.  When the combustion happens after the TDC (Top Dead Center) of this cylinder, the timing is referred in terms of positive angle and if combustion ...";
CM_ BO_ 2364635134 "Engine Cylinder 11 Combustion Metrics
Reports measurements of key combustion metrics for engine cylinder 11";
CM_ SG_ 2364635134 Temp "Gas temperature in cylinder measured at the cylinder head of cylinder 11.";
CM_ SG_ 2364635134 MisfireRate "The misfire rate of engine Cylinder 11 over the number of engine cycles in SPN6394 represented as a percentage.";
CM_ SG_ 2364635134 IndMeanEffPressCV "The indicated mean effective pressure coefficient of variance is the variability seen in IMEP over the number of engine cycles in SPN6394 represented as a percentage.";
CM_ SG_ 2364635134 InstantaneousIndMeanEffPress "The indicated mean effective pressure (IMEP) is the work delivered to the piston over the entire cycle, per unit displaced volume.  This SP reports for the current engine cycle.  See SPN 6523 for an average value.  Negative range is to cover ...";
CM_ SG_ 2364635134 InstantaneousPeakCombPressTiming "The timing in crank angle degrees of the observed peak pressure during the current combustion cycle.  When the combustion happens after the TDC (Top Dead Center) of this cylinder, the timing is referred in terms of positive angle and if combustion ...";
CM_ BO_ 2364634878 "Engine Cylinder 10 Combustion Metrics
Reports measurements of key combustion metrics for engine cylinder 10";
CM_ SG_ 2364634878 Temp "Gas temperature in cylinder measured at the cylinder head of cylinder 10.";
CM_ SG_ 2364634878 MisfireRate "The misfire rate of engine Cylinder 10 over the number of engine cycles in SPN6394 represented as a percentage.";
CM_ SG_ 2364634878 IndMeanEffPressCV "The indicated mean effective pressure coefficient of variance is the variability seen in IMEP over the number of engine cycles in SPN6394 represented as a percentage.";
CM_ SG_ 2364634878 InstantaneousIndMeanEffPress "The indicated mean effective pressure (IMEP) is the work delivered to the piston over the entire cycle, per unit displaced volume.  This SP reports for the current engine cycle.  See SPN 6519 for an average value.  Negative range is to cover ...";
CM_ SG_ 2364634878 InstantaneousPeakCombPressTiming "The timing in crank angle degrees of the observed peak pressure during the current combustion cycle.  When the combustion happens after the TDC (Top Dead Center) of this cylinder, the timing is referred in terms of positive angle and if combustion ...";
CM_ BO_ 2364634622 "Engine Cylinder 9 Combustion Metrics
Reports measurements of key combustion metrics for engine cylinder 9";
CM_ SG_ 2364634622 Temp "Gas temperature in cylinder measured at the cylinder head of cylinder 9.";
CM_ SG_ 2364634622 MisfireRate "The misfire rate of engine Cylinder 9 over the number of engine cycles in SPN6394 represented as a percentage.";
CM_ SG_ 2364634622 IndMeanEffPressCV "The indicated mean effective pressure coefficient of variance is the variability seen in IMEP over the number of engine cycles in SPN6394 represented as a percentage.";
CM_ SG_ 2364634622 InstantaneousIndMeanEffPress "The indicated mean effective pressure (IMEP) is the work delivered to the piston over the entire cycle, per unit displaced volume.  This SP reports for the current engine cycle.  See SPN 6515 for an average value.  Negative range is to cover ...";
CM_ SG_ 2364634622 InstantaneousPeakCombPressTiming "The timing in crank angle degrees of the observed peak pressure during the current combustion cycle.  When the combustion happens after the TDC (Top Dead Center) of this cylinder, the timing is referred in terms of positive angle and if combustion ...";
CM_ BO_ 2364634366 "Engine Cylinder 8 Combustion Metrics
Reports measurements of key combustion metrics for engine cylinder 8";
CM_ SG_ 2364634366 Temp "Gas temperature in cylinder measured at the cylinder head of cylinder 8.";
CM_ SG_ 2364634366 MisfireRate "The misfire rate of engine Cylinder 8 over the number of engine cycles in SPN6394 represented as a percentage.";
CM_ SG_ 2364634366 IndMeanEffPressCV "The indicated mean effective pressure coefficient of variance is the variability seen in IMEP over the number of engine cycles in SPN6394 represented as a percentage.";
CM_ SG_ 2364634366 InstantaneousIndMeanEffPress "The indicated mean effective pressure (IMEP) is the work delivered to the piston over the entire cycle, per unit displaced volume.  This SP reports for the current engine cycle.  See SPN 6511 for an average value.  Negative range is to cover ...";
CM_ SG_ 2364634366 InstantaneousPeakCombPressTiming "The timing in crank angle degrees of the observed peak pressure during the current combustion cycle.  When the combustion happens after the TDC (Top Dead Center) of this cylinder, the timing is referred in terms of positive angle and if combustion ...";
CM_ BO_ 2364634110 "Engine Cylinder 7 Combustion Metrics
Reports measurements of key combustion metrics for engine cylinder 7";
CM_ SG_ 2364634110 Temp "Gas temperature in cylinder measured at the cylinder head of cylinder 7.";
CM_ SG_ 2364634110 MisfireRate "The misfire rate of engine Cylinder 7 over the number of engine cycles in SPN6394 represented as a percentage.";
CM_ SG_ 2364634110 IndMeanEffPressCV "The indicated mean effective pressure coefficient of variance is the variability seen in IMEP over the number of engine cycles in SPN6394 represented as a percentage.";
CM_ SG_ 2364634110 InstantaneousIndMeanEffPress "The indicated mean effective pressure (IMEP) is the work delivered to the piston over the entire cycle, per unit displaced volume.  This SP reports for the current engine cycle.  See SPN 6507 for an average value.  Negative range is to cover ...";
CM_ SG_ 2364634110 InstantaneousPeakCombPressTiming "The timing in crank angle degrees of the observed peak pressure during the current combustion cycle.  When the combustion happens after the TDC (Top Dead Center) of this cylinder, the timing is referred in terms of positive angle and if combustion ...";
CM_ BO_ 2364633854 "Engine Cylinder 6 Combustion Metrics
Reports measurements of key combustion metrics for engine cylinder 6";
CM_ SG_ 2364633854 Temp "Gas temperature in cylinder measured at the cylinder head of cylinder 6.";
CM_ SG_ 2364633854 MisfireRate "The misfire rate of engine Cylinder 6 over the number of engine cycles in SPN6394 represented as a percentage.";
CM_ SG_ 2364633854 IndMeanEffPressCV "The indicated mean effective pressure coefficient of variance is the variability seen in IMEP over the number of engine cycles in SPN6394 represented as a percentage.";
CM_ SG_ 2364633854 InstantaneousIndMeanEffPress "The indicated mean effective pressure (IMEP) is the work delivered to the piston over the entire cycle, per unit displaced volume.  This SP reports for the current engine cycle.  See SPN 6503 for an average value.  Negative range is to cover ...";
CM_ SG_ 2364633854 InstantaneousPeakCombPressTiming "The timing in crank angle degrees of the observed peak pressure during the current combustion cycle.  When the combustion happens after the TDC (Top Dead Center) of this cylinder, the timing is referred in terms of positive angle and if combustion ...";
CM_ BO_ 2364633598 "Engine Cylinder 5 Combustion Metrics
Reports measurements of key combustion metrics for engine cylinder 5";
CM_ SG_ 2364633598 Temp "Gas temperature in cylinder measured at the cylinder head of cylinder 5.";
CM_ SG_ 2364633598 MisfireRate "The misfire rate of engine Cylinder 5 over the number of engine cycles in SPN6394 represented as a percentage.";
CM_ SG_ 2364633598 IndMeanEffPressCV "The indicated mean effective pressure coefficient of variance is the variability seen in IMEP over the number of engine cycles in SPN6394 represented as a percentage.";
CM_ SG_ 2364633598 InstantaneousIndMeanEffPress "The indicated mean effective pressure (IMEP) is the work delivered to the piston over the entire cycle, per unit displaced volume.  This SP reports for the current engine cycle.  See SPN 6499 for an average value.  Negative range is to cover ...";
CM_ SG_ 2364633598 InstantaneousPeakCombPressTiming "The timing in crank angle degrees of the observed peak pressure during the current combustion cycle.  When the combustion happens after the TDC (Top Dead Center) of this cylinder, the timing is referred in terms of positive angle and if combustion ...";
CM_ BO_ 2364633342 "Engine Cylinder 4 Combustion Metrics
Reports measurements of key combustion metrics for engine cylinder 4";
CM_ SG_ 2364633342 Temp "Gas temperature in cylinder measured at the cylinder head of cylinder 4.";
CM_ SG_ 2364633342 MisfireRate "The misfire rate of engine Cylinder 4 over the number of engine cycles in SPN6394 represented as a percentage.";
CM_ SG_ 2364633342 IndMeanEffPressCV "The indicated mean effective pressure coefficient of variance is the variability seen in IMEP over the number of engine cycles in SPN6394 represented as a percentage.";
CM_ SG_ 2364633342 InstantaneousIndMeanEffPress "The indicated mean effective pressure (IMEP) is the work delivered to the piston over the entire cycle, per unit displaced volume.  This SP reports for the current engine cycle.  See SPN 6495 for an average value.  Negative range is to cover ...";
CM_ SG_ 2364633342 InstantaneousPeakCombPressTiming "The timing in crank angle degrees of the observed peak pressure during the current combustion cycle.  When the combustion happens after the TDC (Top Dead Center) of this cylinder, the timing is referred in terms of positive angle and if combustion ...";
CM_ BO_ 2364633086 "Engine Cylinder 3 Combustion Metrics
Reports measurements of key combustion metrics for engine cylinder 3";
CM_ SG_ 2364633086 Temp "Gas temperature in cylinder measured at the cylinder head of cylinder 3.";
CM_ SG_ 2364633086 MisfireRate "The misfire rate of engine Cylinder 3 over the number of engine cycles in SPN6394 represented as a percentage.";
CM_ SG_ 2364633086 IndMeanEffPressCV "The indicated mean effective pressure coefficient of variance is the variability seen in IMEP over the number of engine cycles in SPN6394 represented as a percentage.";
CM_ SG_ 2364633086 InstantaneousIndMeanEffPress "The indicated mean effective pressure (IMEP) is the work delivered to the piston over the entire cycle, per unit displaced volume.  This SP reports for the current engine cycle.  See SPN 6491 for an average value.  Negative range is to cover ...";
CM_ SG_ 2364633086 InstantaneousPeakCombPressTiming "The timing in crank angle degrees of the observed peak pressure during the current combustion cycle.  When the combustion happens after the TDC (Top Dead Center) of this cylinder, the timing is referred in terms of positive angle and if combustion ...";
CM_ BO_ 2364632830 "Engine Cylinder 2 Combustion Metrics
Reports measurements of key combustion metrics for engine cylinder 2";
CM_ SG_ 2364632830 Temp "Gas temperature in cylinder measured at the cylinder head of cylinder 2.";
CM_ SG_ 2364632830 MisfireRate "The misfire rate of engine Cylinder 2 over the number of engine cycles in SPN6394 represented as a percentage.";
CM_ SG_ 2364632830 IndMeanEffPressCV "The indicated mean effective pressure coefficient of variance is the variability seen in IMEP over the number of engine cycles in SPN6394 represented as a percentage.";
CM_ SG_ 2364632830 InstantaneousIndMeanEffPress "The indicated mean effective pressure (IMEP) is the work delivered to the piston over the entire cycle, per unit displaced volume.  This SP reports for the current engine cycle.  See SPN 6487 for an average value.  Negative range is to cover ...";
CM_ SG_ 2364632830 InstantaneousPeakCombPressTiming "The timing in crank angle degrees of the observed peak pressure during the current combustion cycle.  When the combustion happens after the TDC (Top Dead Center) of this cylinder, the timing is referred in terms of positive angle and if combustion ...";
CM_ BO_ 2364632574 "Engine Cylinder 1 Combustion Metrics
Reports measurements of key combustion metrics for engine cylinder 1";
CM_ SG_ 2364632574 Temp "Gas temperature in cylinder measured at the cylinder head of cylinder 1.";
CM_ SG_ 2364632574 MisfireRate "The misfire rate of engine cylinder 1 over the number of engine cycles in SPN6394 represented as a percentage.";
CM_ SG_ 2364632574 IndMeanEffPressCV "The indicated mean effective pressure coefficient of variance is the variability seen in IMEP over the number of engine cycles in SPN6394 represented as a percentage.";
CM_ SG_ 2364632574 InstantaneousIndMeanEffPress "The indicated mean effective pressure (IMEP) is the work delivered to the piston over the entire cycle, per unit displaced volume.  This SP reports for the current engine cycle.  See SPN 6483 for an average value.  Negative range is to cover ...";
CM_ SG_ 2364632574 InstantaneousPeakCombPressTiming "The timing in crank angle degrees of the observed peak pressure during the current combustion cycle.  When the combustion happens after the TDC (Top Dead Center) of this cylinder, the timing is referred in terms of positive angle and if combustion ...";
CM_ BO_ 2364632318 "Engine Cylinder 20 Combustion Timing
Reports the timing relative to TDC of Engine Cylinder 20 for which the respective percentage of fuel has been burned.";
CM_ SG_ 2364632318 InstantaneousCombTimingPoint2 "Engine Cylinder 20 Instantaneous Combustion Timing, Point 2 is defined as the crank angle for which y% of the fuel mass has been burned by Cylinder 20 in the present engine cycle.  y% is defined in SPN 9936. The data will report FB00h (64256) when ...";
CM_ SG_ 2364632318 InstantaneousCombTimingPoint1 "Engine Cylinder 20 Instantaneous Combustion Timing, Point 1 is defined as the crank angle for which x% of the fuel mass has been burned by Cylinder 20 in the present engine cycle.  x% is defined in SPN 9935. The data will report FB00h (64256) when ...";
CM_ SG_ 2364632318 InstantaneousCenterOfCombTiming "Instantaneous Center of Combustion timing is defined as the crank angle for which 50% of the fuel mass has been burned in the present engine cycle.  The data will report FB00h (64256) when the engine is not running.  Center of Combustion is used to ...";
CM_ SG_ 2364632318 InstantaneousStartOfCombTiming "Instantaneous Start of Combustion timing is defined as the crank angle for which less than 5% of the fuel mass has been burned in the present engine cycle.  The data will report FB00h (64256) when the engine is not running.   When the combustion ...";
CM_ BO_ 2364632062 "Engine Cylinder 19 Combustion Timing
Reports the timing relative to TDC of Engine Cylinder 19 for which the respective percentage of fuel has been burned.";
CM_ SG_ 2364632062 InstantaneousCombTimingPoint2 "Engine Cylinder 19 Instantaneous Combustion Timing, Point 2 is defined as the crank angle for which y% of the fuel mass has been burned by Cylinder 19 in the present engine cycle.  y% is defined in SPN 9936. The data will report FB00h (64256) when ...";
CM_ SG_ 2364632062 InstantaneousCombTimingPoint1 "Engine Cylinder 19 Instantaneous Combustion Timing, Point 1 is defined as the crank angle for which x% of the fuel mass has been burned by Cylinder 19 in the present engine cycle.  x% is defined in SPN 9935. The data will report FB00h (64256) when ...";
CM_ SG_ 2364632062 InstantaneousCenterOfCombTiming "Instantaneous Center of Combustion timing is defined as the crank angle for which 50% of the fuel mass has been burned in the present engine cycle.  The data will report FB00h (64256) when the engine is not running.  Center of Combustion is used to ...";
CM_ SG_ 2364632062 InstantaneousStartOfCombTiming "Instantaneous Start of Combustion timing is defined as the crank angle for which less than 5% of the fuel mass has been burned in the present engine cycle.  The data will report FB00h (64256) when the engine is not running.   When the combustion ...";
CM_ BO_ 2364631806 "Engine Cylinder 18 Combustion Timing
Reports the timing relative to TDC of Engine Cylinder 18 for which the respective percentage of fuel has been burned.";
CM_ SG_ 2364631806 InstantaneousCombTimingPoint2 "Engine Cylinder 18 Instantaneous Combustion Timing, Point 2 is defined as the crank angle for which y% of the fuel mass has been burned by Cylinder 18 in the present engine cycle.  y% is defined in SPN 9936. The data will report FB00h (64256) when ...";
CM_ SG_ 2364631806 InstantaneousCombTimingPoint1 "Engine Cylinder 18 Instantaneous Combustion Timing, Point 1 is defined as the crank angle for which x% of the fuel mass has been burned by Cylinder 18 in the present engine cycle.  x% is defined in SPN 9935. The data will report FB00h (64256) when ...";
CM_ SG_ 2364631806 InstantaneousCenterOfCombTiming "Instantaneous Center of Combustion timing is defined as the crank angle for which 50% of the fuel mass has been burned in the present engine cycle.  The data will report FB00h (64256) when the engine is not running.  Center of Combustion is used to ...";
CM_ SG_ 2364631806 InstantaneousStartOfCombTiming "Instantaneous Start of Combustion timing is defined as the crank angle for which less than 5% of the fuel mass has been burned in the present engine cycle.  The data will report FB00h (64256) when the engine is not running.   When the combustion ...";
CM_ BO_ 2364631550 "Engine Cylinder 17 Combustion Timing
Reports the timing relative to TDC of Engine Cylinder 17 for which the respective percentage of fuel has been burned.";
CM_ SG_ 2364631550 InstantaneousCombTimingPoint2 "Engine Cylinder 17 Instantaneous Combustion Timing, Point 2 is defined as the crank angle for which y% of the fuel mass has been burned by Cylinder 17 in the present engine cycle.  y% is defined in SPN 9936. The data will report FB00h (64256) when ...";
CM_ SG_ 2364631550 InstantaneousCombTimingPoint1 "Engine Cylinder 17 Instantaneous Combustion Timing, Point 1 is defined as the crank angle for which x% of the fuel mass has been burned by Cylinder 17 in the present engine cycle.  x% is defined in SPN 9935. The data will report FB00h (64256) when ...";
CM_ SG_ 2364631550 InstantaneousCenterOfCombTiming "Instantaneous Center of Combustion timing is defined as the crank angle for which 50% of the fuel mass has been burned in the present engine cycle.  The data will report FB00h (64256) when the engine is not running.  Center of Combustion is used to ...";
CM_ SG_ 2364631550 InstantaneousStartOfCombTiming "Instantaneous Start of Combustion timing is defined as the crank angle for which less than 5% of the fuel mass has been burned in the present engine cycle.  The data will report FB00h (64256) when the engine is not running.   When the combustion ...";
CM_ BO_ 2364631294 "Engine Cylinder 16 Combustion Timing
Reports the timing relative to TDC of Engine Cylinder 16 for which the respective percentage of fuel has been burned.";
CM_ SG_ 2364631294 InstantaneousCombTimingPoint2 "Engine Cylinder 16 Instantaneous Combustion Timing, Point 2 is defined as the crank angle for which y% of the fuel mass has been burned by Cylinder 16 in the present engine cycle.  y% is defined in SPN 9936. The data will report FB00h (64256) when ...";
CM_ SG_ 2364631294 InstantaneousCombTimingPoint1 "Engine Cylinder 16 Instantaneous Combustion Timing, Point 1 is defined as the crank angle for which x% of the fuel mass has been burned by Cylinder 16 in the present engine cycle.  x% is defined in SPN 9935. The data will report FB00h (64256) when ...";
CM_ SG_ 2364631294 InstantaneousCenterOfCombTiming "Instantaneous Center of Combustion timing is defined as the crank angle for which 50% of the fuel mass has been burned in the present engine cycle.  The data will report FB00h (64256) when the engine is not running.  Center of Combustion is used to ...";
CM_ SG_ 2364631294 InstantaneousStartOfCombTiming "Instantaneous Start of Combustion timing is defined as the crank angle for which less than 5% of the fuel mass has been burned in the present engine cycle.  The data will report FB00h (64256) when the engine is not running.   When the combustion ...";
CM_ BO_ 2364631038 "Engine Cylinder 15 Combustion Timing
Reports the timing relative to TDC of Engine Cylinder 15 for which the respective percentage of fuel has been burned.";
CM_ SG_ 2364631038 InstantaneousCombTimingPoint2 "Engine Cylinder 15 Instantaneous Combustion Timing, Point 2 is defined as the crank angle for which y% of the fuel mass has been burned by Cylinder 15 in the present engine cycle.  y% is defined in SPN 9936. The data will report FB00h (64256) when ...";
CM_ SG_ 2364631038 InstantaneousCombTimingPoint1 "Engine Cylinder 15 Instantaneous Combustion Timing, Point 1 is defined as the crank angle for which x% of the fuel mass has been burned by Cylinder 15 in the present engine cycle.  x% is defined in SPN 9935. The data will report FB00h (64256) when ...";
CM_ SG_ 2364631038 InstantaneousCenterOfCombTiming "Instantaneous Center of Combustion timing is defined as the crank angle for which 50% of the fuel mass has been burned in the present engine cycle.  The data will report FB00h (64256) when the engine is not running.  Center of Combustion is used to ...";
CM_ SG_ 2364631038 InstantaneousStartOfCombTiming "Instantaneous Start of Combustion timing is defined as the crank angle for which less than 5% of the fuel mass has been burned in the present engine cycle.  The data will report FB00h (64256) when the engine is not running.   When the combustion ...";
CM_ BO_ 2364630782 "Engine Cylinder 14 Combustion Timing
Reports the timing relative to TDC of Engine Cylinder 14 for which the respective percentage of fuel has been burned.";
CM_ SG_ 2364630782 InstantaneousCombTimingPoint2 "Engine Cylinder 14 Instantaneous Combustion Timing, Point 2 is defined as the crank angle for which y% of the fuel mass has been burned by Cylinder 14 in the present engine cycle.  y% is defined in SPN 9936. The data will report FB00h (64256) when ...";
CM_ SG_ 2364630782 InstantaneousCombTimingPoint1 "Engine Cylinder 14 Instantaneous Combustion Timing, Point 1 is defined as the crank angle for which x% of the fuel mass has been burned by Cylinder 14 in the present engine cycle.  x% is defined in SPN 9935. The data will report FB00h (64256) when ...";
CM_ SG_ 2364630782 InstantaneousCenterOfCombTiming "Instantaneous Center of Combustion timing is defined as the crank angle for which 50% of the fuel mass has been burned in the present engine cycle.  The data will report FB00h (64256) when the engine is not running.  Center of Combustion is used to ...";
CM_ SG_ 2364630782 InstantaneousStartOfCombTiming "Instantaneous Start of Combustion timing is defined as the crank angle for which less than 5% of the fuel mass has been burned in the present engine cycle.  The data will report FB00h (64256) when the engine is not running.   When the combustion ...";
CM_ BO_ 2364630526 "Engine Cylinder 13 Combustion Timing
Reports the timing relative to TDC of Engine Cylinder 13 for which the respective percentage of fuel has been burned.";
CM_ SG_ 2364630526 InstantaneousCombTimingPoint2 "Engine Cylinder 13 Instantaneous Combustion Timing, Point 2 is defined as the crank angle for which y% of the fuel mass has been burned by Cylinder 13 in the present engine cycle.  y% is defined in SPN 9936. The data will report FB00h (64256) when ...";
CM_ SG_ 2364630526 InstantaneousCombTimingPoint1 "Engine Cylinder 13 Instantaneous Combustion Timing, Point 1 is defined as the crank angle for which x% of the fuel mass has been burned by Cylinder 13 in the present engine cycle.  x% is defined in SPN 9935. The data will report FB00h (64256) when ...";
CM_ SG_ 2364630526 InstantaneousCenterOfCombTiming "Instantaneous Center of Combustion timing is defined as the crank angle for which 50% of the fuel mass has been burned in the present engine cycle.  The data will report FB00h (64256) when the engine is not running.  Center of Combustion is used to ...";
CM_ SG_ 2364630526 InstantaneousStartOfCombTiming "Instantaneous Start of Combustion timing is defined as the crank angle for which less than 5% of the fuel mass has been burned in the present engine cycle.  The data will report FB00h (64256) when the engine is not running.   When the combustion ...";
CM_ BO_ 2364630270 "Engine Cylinder 12 Combustion Timing
Reports the timing relative to TDC of Engine Cylinder 12 for which the respective percentage of fuel has been burned.";
CM_ SG_ 2364630270 InstantaneousCombTimingPoint2 "Engine Cylinder 12 Instantaneous Combustion Timing, Point 2 is defined as the crank angle for which y% of the fuel mass has been burned by Cylinder 12 in the present engine cycle.  y% is defined in SPN 9936. The data will report FB00h (64256) when ...";
CM_ SG_ 2364630270 InstantaneousCombTimingPoint1 "Engine Cylinder 12 Instantaneous Combustion Timing, Point 1 is defined as the crank angle for which x% of the fuel mass has been burned by Cylinder 12 in the present engine cycle.  x% is defined in SPN 9935. The data will report FB00h (64256) when ...";
CM_ SG_ 2364630270 InstantaneousCenterOfCombTiming "Instantaneous Center of Combustion timing is defined as the crank angle for which 50% of the fuel mass has been burned in the present engine cycle.  The data will report FB00h (64256) when the engine is not running.  Center of Combustion is used to ...";
CM_ SG_ 2364630270 InstantaneousStartOfCombTiming "Instantaneous Start of Combustion timing is defined as the crank angle for which less than 5% of the fuel mass has been burned in the present engine cycle.  The data will report FB00h (64256) when the engine is not running.   When the combustion ...";
CM_ BO_ 2364630014 "Engine Cylinder 11 Combustion Timing
Reports the timing relative to TDC of Engine Cylinder 11 for which the respective percentage of fuel has been burned.";
CM_ SG_ 2364630014 InstantaneousCombTimingPoint2 "Engine Cylinder 11 Instantaneous Combustion Timing, Point 2 is defined as the crank angle for which y% of the fuel mass has been burned by Cylinder 11 in the present engine cycle.  y% is defined in SPN 9936. The data will report FB00h (64256) when ...";
CM_ SG_ 2364630014 InstantaneousCombTimingPoint1 "Engine Cylinder 11 Instantaneous Combustion Timing, Point 1 is defined as the crank angle for which x% of the fuel mass has been burned by Cylinder 11 in the present engine cycle.  x% is defined in SPN 9935. The data will report FB00h (64256) when ...";
CM_ SG_ 2364630014 InstantaneousCenterOfCombTiming "Instantaneous Center of Combustion timing is defined as the crank angle for which 50% of the fuel mass has been burned in the present engine cycle.  The data will report FB00h (64256) when the engine is not running.  Center of Combustion is used to ...";
CM_ SG_ 2364630014 InstantaneousStartOfCombTiming "Instantaneous Start of Combustion timing is defined as the crank angle for which less than 5% of the fuel mass has been burned in the present engine cycle.  The data will report FB00h (64256) when the engine is not running.   When the combustion ...";
CM_ BO_ 2364629758 "Engine Cylinder 10 Combustion Timing
Reports the timing relative to TDC of Engine Cylinder 10 for which the respective percentage of fuel has been burned.";
CM_ SG_ 2364629758 InstantaneousCombTimingPoint2 "Engine Cylinder 10 Instantaneous Combustion Timing, Point 2 is defined as the crank angle for which y% of the fuel mass has been burned by Cylinder 10 in the present engine cycle.  y% is defined in SPN 9936. The data will report FB00h (64256) when ...";
CM_ SG_ 2364629758 InstantaneousCombTimingPoint1 "Engine Cylinder 10 Instantaneous Combustion Timing, Point 1 is defined as the crank angle for which x% of the fuel mass has been burned by Cylinder 10 in the present engine cycle.  x% is defined in SPN 9935. The data will report FB00h (64256) when ...";
CM_ SG_ 2364629758 InstantaneousCenterOfCombTiming "Instantaneous Center of Combustion timing is defined as the crank angle for which 50% of the fuel mass has been burned in the present engine cycle.  The data will report FB00h (64256) when the engine is not running.  Center of Combustion is used to ...";
CM_ SG_ 2364629758 InstantaneousStartOfCombTiming "Instantaneous Start of Combustion timing is defined as the crank angle for which less than 5% of the fuel mass has been burned in the present engine cycle.  The data will report FB00h (64256) when the engine is not running.   When the combustion ...";
CM_ BO_ 2364629502 "Engine Cylinder 9 Combustion Timing
Reports the timing relative to TDC of Engine Cylinder 9 for which the respective percentage of fuel has been burned.";
CM_ SG_ 2364629502 InstantaneousCombTimingPoint2 "Engine Cylinder 9 Instantaneous Combustion Timing, Point 2 is defined as the crank angle for which y% of the fuel mass has been burned by Cylinder 9 in the present engine cycle.  y% is defined in SPN 9936. The data will report FB00h (64256) when the ...";
CM_ SG_ 2364629502 InstantaneousCombTimingPoint1 "Engine Cylinder 9 Instantaneous Combustion Timing, Point 1 is defined as the crank angle for which x% of the fuel mass has been burned by Cylinder 9 in the present engine cycle.  x% is defined in SPN 9935. The data will report FB00h (64256) when the ...";
CM_ SG_ 2364629502 InstantaneousCenterOfCombTiming "Instantaneous Center of Combustion timing is defined as the crank angle for which 50% of the fuel mass has been burned in the present engine cycle.  The data will report FB00h (64256) when the engine is not running.  Center of Combustion is used to ...";
CM_ SG_ 2364629502 InstantaneousStartOfCombTiming "Instantaneous Start of Combustion timing is defined as the crank angle for which less than 5% of the fuel mass has been burned in the present engine cycle.  The data will report FB00h (64256) when the engine is not running.   When the combustion ...";
CM_ BO_ 2364629246 "Engine Cylinder 8 Combustion Timing
Reports the timing relative to TDC of Engine Cylinder 8 for which the respective percentage of fuel has been burned.";
CM_ SG_ 2364629246 InstantaneousCombTimingPoint2 "Engine Cylinder 8 Instantaneous Combustion Timing, Point 2 is defined as the crank angle for which y% of the fuel mass has been burned by Cylinder 8 in the present engine cycle.  y% is defined in SPN 9936. The data will report FB00h (64256) when the ...";
CM_ SG_ 2364629246 InstantaneousCombTimingPoint1 "Engine Cylinder 8 Instantaneous Combustion Timing, Point 1 is defined as the crank angle for which x% of the fuel mass has been burned by Cylinder 8 in the present engine cycle.  x% is defined in SPN 9935. The data will report FB00h (64256) when the ...";
CM_ SG_ 2364629246 InstantaneousCenterOfCombTiming "Instantaneous Center of Combustion timing is defined as the crank angle for which 50% of the fuel mass has been burned in the present engine cycle.  The data will report FB00h (64256) when the engine is not running.  Center of Combustion is used to ...";
CM_ SG_ 2364629246 InstantaneousStartOfCombTiming "Instantaneous Start of Combustion timing is defined as the crank angle for which less than 5% of the fuel mass has been burned in the present engine cycle.  The data will report FB00h (64256) when the engine is not running.   When the combustion ...";
CM_ BO_ 2364628990 "Engine Cylinder 7 Combustion Timing
Reports the timing relative to TDC of Engine Cylinder 7 for which the respective percentage of fuel has been burned.";
CM_ SG_ 2364628990 InstantaneousCombTimingPoint2 "Engine Cylinder 7 Instantaneous Combustion Timing, Point 2 is defined as the crank angle for which y% of the fuel mass has been burned by Cylinder 7 in the present engine cycle.  y% is defined in SPN 9936. The data will report FB00h (64256) when the ...";
CM_ SG_ 2364628990 InstantaneousCombTimingPoint1 "Engine Cylinder 7 Instantaneous Combustion Timing, Point 1 is defined as the crank angle for which x% of the fuel mass has been burned by Cylinder 7 in the present engine cycle.  x% is defined in SPN 9935. The data will report FB00h (64256) when the ...";
CM_ SG_ 2364628990 InstantaneousCenterOfCombTiming "Instantaneous Center of Combustion timing is defined as the crank angle for which 50% of the fuel mass has been burned in the present engine cycle.  The data will report FB00h (64256) when the engine is not running.  Center of Combustion is used to ...";
CM_ SG_ 2364628990 InstantaneousStartOfCombTiming "Instantaneous Start of Combustion timing is defined as the crank angle for which less than 5% of the fuel mass has been burned in the present engine cycle.  The data will report FB00h (64256) when the engine is not running.   When the combustion ...";
CM_ BO_ 2364628734 "Engine Cylinder 6 Combustion Timing
Reports the timing relative to TDC of Engine Cylinder 6 for which the respective percentage of fuel has been burned.";
CM_ SG_ 2364628734 InstantaneousCombTimingPoint2 "Engine Cylinder 6 Instantaneous Combustion Timing, Point 2 is defined as the crank angle for which y% of the fuel mass has been burned by Cylinder 6 in the present engine cycle.  y% is defined in SPN 9936. The data will report FB00h (64256) when the ...";
CM_ SG_ 2364628734 InstantaneousCombTimingPoint1 "Engine Cylinder 6 Instantaneous Combustion Timing, Point 1 is defined as the crank angle for which x% of the fuel mass has been burned by Cylinder 6 in the present engine cycle.  x% is defined in SPN 9935. The data will report FB00h (64256) when the ...";
CM_ SG_ 2364628734 InstantaneousCenterOfCombTiming "Instantaneous Center of Combustion timing is defined as the crank angle for which 50% of the fuel mass has been burned in the present engine cycle.  The data will report FB00h (64256) when the engine is not running.  Center of Combustion is used to ...";
CM_ SG_ 2364628734 InstantaneousStartOfCombTiming "Instantaneous Start of Combustion timing is defined as the crank angle for which less than 5% of the fuel mass has been burned in the present engine cycle.  The data will report FB00h (64256) when the engine is not running.   When the combustion ...";
CM_ BO_ 2364628478 "Engine Cylinder 5 Combustion Timing
Reports the timing relative to TDC of Engine Cylinder 5 for which the respective percentage of fuel has been burned.";
CM_ SG_ 2364628478 InstantaneousCombTimingPoint2 "Engine Cylinder 5 Instantaneous Combustion Timing, Point 2 is defined as the crank angle for which y% of the fuel mass has been burned by Cylinder 5 in the present engine cycle.  y% is defined in SPN 9936. The data will report FB00h (64256) when the ...";
CM_ SG_ 2364628478 InstantaneousCombTimingPoint1 "Engine Cylinder 5 Instantaneous Combustion Timing, Point 1 is defined as the crank angle for which x% of the fuel mass has been burned by Cylinder 5 in the present engine cycle.  x% is defined in SPN 9935. The data will report FB00h (64256) when the ...";
CM_ SG_ 2364628478 InstantaneousCenterOfCombTiming "Instantaneous Center of Combustion timing is defined as the crank angle for which 50% of the fuel mass has been burned in the present engine cycle.  The data will report FB00h (64256) when the engine is not running.  Center of Combustion is used to ...";
CM_ SG_ 2364628478 InstantaneousStartOfCombTiming "Instantaneous Start of Combustion timing is defined as the crank angle for which less than 5% of the fuel mass has been burned in the present engine cycle.  The data will report FB00h (64256) when the engine is not running.   When the combustion ...";
CM_ BO_ 2364628222 "Engine Cylinder 4 Combustion Timing
Reports the timing relative to TDC of Engine Cylinder 4 for which the respective percentage of fuel has been burned.";
CM_ SG_ 2364628222 InstantaneousCombTimingPoint2 "Engine Cylinder 4 Instantaneous Combustion Timing, Point 2 is defined as the crank angle for which y% of the fuel mass has been burned by Cylinder 4 in the present engine cycle.  y% is defined in SPN 9936. The data will report FB00h (64256) when the ...";
CM_ SG_ 2364628222 InstantaneousCombTimingPoint1 "Engine Cylinder 4 Instantaneous Combustion Timing, Point 1 is defined as the crank angle for which x% of the fuel mass has been burned by Cylinder 4 in the present engine cycle.  x% is defined in SPN 9935. The data will report FB00h (64256) when the ...";
CM_ SG_ 2364628222 InstantaneousCenterOfCombTiming "Instantaneous Center of Combustion timing is defined as the crank angle for which 50% of the fuel mass has been burned in the present engine cycle.  The data will report FB00h (64256) when the engine is not running.  Center of Combustion is used to ...";
CM_ SG_ 2364628222 InstantaneousStartOfCombTiming "Instantaneous Start of Combustion timing is defined as the crank angle for which less than 5% of the fuel mass has been burned in the present engine cycle.  The data will report FB00h (64256) when the engine is not running.   When the combustion ...";
CM_ BO_ 2364627966 "Engine Cylinder 3 Combustion Timing
Reports the timing relative to TDC of Engine Cylinder 3 for which the respective percentage of fuel has been burned.";
CM_ SG_ 2364627966 InstantaneousCombTimingPoint2 "Engine Cylinder 3 Instantaneous Combustion Timing, Point 2 is defined as the crank angle for which y% of the fuel mass has been burned by Cylinder 3 in the present engine cycle.  y% is defined in SPN 9936. The data will report FB00h (64256) when the ...";
CM_ SG_ 2364627966 InstantaneousCombTimingPoint1 "Engine Cylinder 3 Instantaneous Combustion Timing, Point 1 is defined as the crank angle for which x% of the fuel mass has been burned by Cylinder 3 in the present engine cycle.  x% is defined in SPN 9935. The data will report FB00h (64256) when the ...";
CM_ SG_ 2364627966 InstantaneousCenterOfCombTiming "Instantaneous Center of Combustion timing is defined as the crank angle for which 50% of the fuel mass has been burned in the present engine cycle.  The data will report FB00h (64256) when the engine is not running.  Center of Combustion is used to ...";
CM_ SG_ 2364627966 InstantaneousStartOfCombTiming "Instantaneous Start of Combustion timing is defined as the crank angle for which less than 5% of the fuel mass has been burned in the present engine cycle.  The data will report FB00h (64256) when the engine is not running.   When the combustion ...";
CM_ BO_ 2364627710 "Engine Cylinder 2 Combustion Timing
Reports the timing relative to TDC of Engine Cylinder 2 for which the respective percentage of fuel has been burned.";
CM_ SG_ 2364627710 InstantaneousCombTimingPoint2 "Engine Cylinder 2 Instantaneous Combustion Timing, Point 2 is defined as the crank angle for which y% of the fuel mass has been burned by Cylinder 2 in the present engine cycle.  y% is defined in SPN 9936. The data will report FB00h (64256) when the ...";
CM_ SG_ 2364627710 InstantaneousCombTimingPoint1 "Engine Cylinder 2 Instantaneous Combustion Timing, Point 1 is defined as the crank angle for which x% of the fuel mass has been burned by Cylinder 2 in the present engine cycle.  x% is defined in SPN 9935. The data will report FB00h (64256) when the ...";
CM_ SG_ 2364627710 InstantaneousCenterOfCombTiming "Instantaneous Center of Combustion timing is defined as the crank angle for which 50% of the fuel mass has been burned in the present engine cycle.  The data will report FB00h (64256) when the engine is not running.  Center of Combustion is used to ...";
CM_ SG_ 2364627710 InstantaneousStartOfCombTiming "Instantaneous Start of Combustion timing is defined as the crank angle for which less than 5% of the fuel mass has been burned in the present engine cycle.  The data will report FB00h (64256) when the engine is not running.   When the combustion ...";
CM_ BO_ 2364627454 "Engine Cylinder 1 Combustion Timing
Reports the timing relative to TDC of Engine Cylinder 1 for which the respective percentage of fuel has been burned.";
CM_ SG_ 2364627454 InstantaneousCombTimingPoint2 "Engine Cylinder 1 Instantaneous Combustion Timing, Point 2 is defined as the crank angle for which y% of the fuel mass has been burned by Cylinder 1 in the present engine cycle.  y% is defined in SPN 9936. The data will report FB00h (64256) when the ...";
CM_ SG_ 2364627454 InstantaneousCombTimingPoint1 "Engine Cylinder 1 Instantaneous Combustion Timing, Point 1 is defined as the crank angle for which x% of the fuel mass has been burned by Cylinder 1 in the present engine cycle.  x% is defined in SPN 9935. The data will report FB00h (64256) when the ...";
CM_ SG_ 2364627454 InstantaneousCenterOfCombTiming "Instantaneous Center of Combustion timing is defined as the crank angle for which 50% of the fuel mass has been burned in the present engine cycle.  The data will report FB00h (64256) when the engine is not running.  Center of Combustion is used to ...";
CM_ SG_ 2364627454 InstantaneousStartOfCombTiming "Instantaneous Start of Combustion timing is defined as the crank angle for which less than 5% of the fuel mass has been burned in the present engine cycle.  The data will report FB00h (64256) when the engine is not running.   When the combustion ...";
CM_ BO_ 2364627198 "Engine Cylinder 20 Combustion Pressures
Used to transmit the combustion pressure at 4 user-defined timing locations for Engine Cylinder 20";
CM_ SG_ 2364627198 Timing4Press "In-cylinder pressure for Cylinder #20 at user-defined timing location #4 as per SPN 9848.  Will report FB00h (64256) when engine is not running.";
CM_ SG_ 2364627198 Timing3Press "In-cylinder pressure for Cylinder #20 at user-defined timing location #3 as per SPN 9847.  Will report FB00h (64256) when engine is not running.";
CM_ SG_ 2364627198 Timing2Press "In-cylinder pressure for Cylinder #20 at user-defined timing location #2 as per SPN 9846.  Will report FB00h (64256) when engine is not running.";
CM_ SG_ 2364627198 Timing1Press "In-cylinder pressure for Cylinder #20 at user-defined timing location #1 as per SPN 9845.  Will report FB00h (64256) when engine is not running.";
CM_ BO_ 2364626942 "Engine Cylinder 19 Combustion Pressures
Used to transmit the combustion pressure at 4 user-defined timing locations for Engine Cylinder 19.";
CM_ SG_ 2364626942 Timing4Press "In-cylinder pressure for Cylinder #19 at user-defined timing location #4 as per SPN 9848.  Will report FB00h (64256) when engine is not running.";
CM_ SG_ 2364626942 Timing3Press "In-cylinder pressure for Cylinder #19 at user-defined timing location #3 as per SPN 9847.  Will report FB00h (64256) when engine is not running.";
CM_ SG_ 2364626942 Timing2Press "In-cylinder pressure for Cylinder #19 at user-defined timing location #2 as per SPN 9846.  Will report FB00h (64256) when engine is not running.";
CM_ SG_ 2364626942 Timing1Press "In-cylinder pressure for Cylinder #19 at user-defined timing location #1 as per SPN 9845.  Will report FB00h (64256) when engine is not running.";
CM_ BO_ 2364626686 "Engine Cylinder 18 Combustion Pressures
Used to transmit the combustion pressure at 4 user-defined timing locations for Engine Cylinder 18.";
CM_ SG_ 2364626686 Timing4Press "In-cylinder pressure for Cylinder #18 at user-defined timing location #4 as per SPN 9848.  Will report FB00h (64256) when engine is not running.";
CM_ SG_ 2364626686 Timing3Press "In-cylinder pressure for Cylinder #18 at user-defined timing location #3 as per SPN 9847.  Will report FB00h (64256) when engine is not running.";
CM_ SG_ 2364626686 Timing2Press "In-cylinder pressure for Cylinder #18 at user-defined timing location #2 as per SPN 9846.  Will report FB00h (64256) when engine is not running.";
CM_ SG_ 2364626686 Timing1Press "In-cylinder pressure for Cylinder #18 at user-defined timing location #1 as per SPN 9845.  Will report FB00h (64256) when engine is not running.";
CM_ BO_ 2364626430 "Engine Cylinder 17 Combustion Pressures
Used to transmit the combustion pressure at 4 user-defined timing locations for Engine Cylinder 17.";
CM_ SG_ 2364626430 Timing4Press "In-cylinder pressure for Cylinder #17 at user-defined timing location #4 as per SPN 9848.  Will report FB00h (64256) when engine is not running.";
CM_ SG_ 2364626430 Timing3Press "In-cylinder pressure for Cylinder #17 at user-defined timing location #3 as per SPN 9847.  Will report FB00h (64256) when engine is not running.";
CM_ SG_ 2364626430 Timing2Press "In-cylinder pressure for Cylinder #17 at user-defined timing location #2 as per SPN 9846.  Will report FB00h (64256) when engine is not running.";
CM_ SG_ 2364626430 Timing1Press "In-cylinder pressure for Cylinder #17 at user-defined timing location #1 as per SPN 9845.  Will report FB00h (64256) when engine is not running.";
CM_ BO_ 2364626174 "Engine Cylinder 16 Combustion Pressures
Used to transmit the combustion pressure at 4 user-defined timing locations for Engine Cylinder 16.";
CM_ SG_ 2364626174 Timing4Press "In-cylinder pressure for Cylinder #16 at user-defined timing location #4 as per SPN 9848.  Will report FB00h (64256) when engine is not running.";
CM_ SG_ 2364626174 Timing3Press "In-cylinder pressure for Cylinder #16 at user-defined timing location #3 as per SPN 9847.  Will report FB00h (64256) when engine is not running.";
CM_ SG_ 2364626174 Timing2Press "In-cylinder pressure for Cylinder #16 at user-defined timing location #2 as per SPN 9846.  Will report FB00h (64256) when engine is not running.";
CM_ SG_ 2364626174 Timing1Press "In-cylinder pressure for Cylinder #16 at user-defined timing location #1 as per SPN 9845.  Will report FB00h (64256) when engine is not running.";
CM_ BO_ 2364625918 "Engine Cylinder 15 Combustion Pressures
Used to transmit the combustion pressure at 4 user-defined timing locations for Engine Cylinder 15.";
CM_ SG_ 2364625918 Timing4Press "In-cylinder pressure for Cylinder #15 at user-defined timing location #4 as per SPN 9848.  Will report FB00h (64256) when engine is not running.";
CM_ SG_ 2364625918 Timing3Press "In-cylinder pressure for Cylinder #15 at user-defined timing location #3 as per SPN 9847.  Will report FB00h (64256) when engine is not running.";
CM_ SG_ 2364625918 Timing2Press "In-cylinder pressure for Cylinder #15 at user-defined timing location #2 as per SPN 9846.  Will report FB00h (64256) when engine is not running.";
CM_ SG_ 2364625918 Timing1Press "In-cylinder pressure for Cylinder #15 at user-defined timing location #1 as per SPN 9845.  Will report FB00h (64256) when engine is not running.";
CM_ BO_ 2364625662 "Engine Cylinder 14 Combustion Pressures
Used to transmit the combustion pressure at 4 user-defined timing locations for Engine Cylinder 14.";
CM_ SG_ 2364625662 Timing4Press "In-cylinder pressure for Cylinder #14 at user-defined timing location #4 as per SPN 9848.  Will report FB00h (64256) when engine is not running.";
CM_ SG_ 2364625662 Timing3Press "In-cylinder pressure for Cylinder #14 at user-defined timing location #3 as per SPN 9847.  Will report FB00h (64256) when engine is not running.";
CM_ SG_ 2364625662 Timing2Press "In-cylinder pressure for Cylinder #14 at user-defined timing location #2 as per SPN 9846.  Will report FB00h (64256) when engine is not running.";
CM_ SG_ 2364625662 Timing1Press "In-cylinder pressure for Cylinder #14 at user-defined timing location #1 as per SPN 9845.  Will report FB00h (64256) when engine is not running.";
CM_ BO_ 2364625406 "Engine Cylinder 13 Combustion Pressures
Used to transmit the combustion pressure at 4 user-defined timing locations for Engine Cylinder 13.";
CM_ SG_ 2364625406 Timing4Press "In-cylinder pressure for Cylinder #13 at user-defined timing location #4 as per SPN 9848.  Will report FB00h (64256) when engine is not running.";
CM_ SG_ 2364625406 Timing3Press "In-cylinder pressure for Cylinder #13 at user-defined timing location #3 as per SPN 9847.  Will report FB00h (64256) when engine is not running.";
CM_ SG_ 2364625406 Timing2Press "In-cylinder pressure for Cylinder #13 at user-defined timing location #2 as per SPN 9846.  Will report FB00h (64256) when engine is not running.";
CM_ SG_ 2364625406 Timing1Press "In-cylinder pressure for Cylinder #13 at user-defined timing location #1 as per SPN 9845.  Will report FB00h (64256) when engine is not running.";
CM_ BO_ 2364625150 "Engine Cylinder 12 Combustion Pressures
Used to transmit the combustion pressure at 4 user-defined timing locations for Engine Cylinder 12.";
CM_ SG_ 2364625150 Timing4Press "In-cylinder pressure for Cylinder #12 at user-defined timing location #4 as per SPN 9848.  Will report FB00h (64256) when engine is not running.";
CM_ SG_ 2364625150 Timing3Press "In-cylinder pressure for Cylinder #12 at user-defined timing location #3 as per SPN 9847.  Will report FB00h (64256) when engine is not running.";
CM_ SG_ 2364625150 Timing2Press "In-cylinder pressure for Cylinder #12 at user-defined timing location #2 as per SPN 9846.  Will report FB00h (64256) when engine is not running.";
CM_ SG_ 2364625150 Timing1Press "In-cylinder pressure for Cylinder #12 at user-defined timing location #1 as per SPN 9845.  Will report FB00h (64256) when engine is not running.";
CM_ BO_ 2364624894 "Engine Cylinder 11 Combustion Pressures
Used to transmit the combustion pressure at 4 user-defined timing locations for Engine Cylinder 11.";
CM_ SG_ 2364624894 Timing4Press "In-cylinder pressure for Cylinder #11 at user-defined timing location #4 as per SPN 9848.  Will report FB00h (64256) when engine is not running.";
CM_ SG_ 2364624894 Timing3Press "In-cylinder pressure for Cylinder #11 at user-defined timing location #3 as per SPN 9847.  Will report FB00h (64256) when engine is not running.";
CM_ SG_ 2364624894 Timing2Press "In-cylinder pressure for Cylinder #11 at user-defined timing location #2 as per SPN 9846.  Will report FB00h (64256) when engine is not running.";
CM_ SG_ 2364624894 Timing1Press "In-cylinder pressure for Cylinder #11 at user-defined timing location #1 as per SPN 9845.  Will report FB00h (64256) when engine is not running.";
CM_ BO_ 2364624638 "Engine Cylinder 10 Combustion Pressures
Used to transmit the combustion pressure at 4 user-defined timing locations for Engine Cylinder 10.";
CM_ SG_ 2364624638 Timing4Press "In-cylinder pressure for Cylinder #10 at user-defined timing location #4 as per SPN 9848.  Will report FB00h (64256) when engine is not running.";
CM_ SG_ 2364624638 Timing3Press "In-cylinder pressure for Cylinder #10 at user-defined timing location #3 as per SPN 9847.  Will report FB00h (64256) when engine is not running.";
CM_ SG_ 2364624638 Timing2Press "In-cylinder pressure for Cylinder #10 at user-defined timing location #2 as per SPN 9846.  Will report FB00h (64256) when engine is not running.";
CM_ SG_ 2364624638 Timing1Press "In-cylinder pressure for Cylinder #10 at user-defined timing location #1 as per SPN 9845.  Will report FB00h (64256) when engine is not running.";
CM_ BO_ 2364624382 "Engine Cylinder 9 Combustion Pressures
Used to transmit the combustion pressure at 4 user-defined timing locations for Engine Cylinder 9.";
CM_ SG_ 2364624382 Timing4Press "In-cylinder pressure for Cylinder #9 at user-defined timing location #4 as per SPN 9848.  Will report FB00h (64256) when engine is not running.";
CM_ SG_ 2364624382 Timing3Press "In-cylinder pressure for Cylinder #9 at user-defined timing location #3 as per SPN 9847.  Will report FB00h (64256) when engine is not running.";
CM_ SG_ 2364624382 Timing2Press "In-cylinder pressure for Cylinder #9 at user-defined timing location #2 as per SPN 9846.  Will report FB00h (64256) when engine is not running.";
CM_ SG_ 2364624382 Timing1Press "In-cylinder pressure for Cylinder #9 at user-defined timing location #1 as per SPN 9845.  Will report FB00h (64256) when engine is not running.";
CM_ BO_ 2364624126 "Engine Cylinder 8 Combustion Pressures
Used to transmit the combustion pressure at 4 user-defined timing locations for Engine Cylinder 8.";
CM_ SG_ 2364624126 Timing4Press "In-cylinder pressure for Cylinder #8 at user-defined timing location #4 as per SPN 9848.  Will report FB00h (64256) when engine is not running.";
CM_ SG_ 2364624126 Timing3Press "In-cylinder pressure for Cylinder #8 at user-defined timing location #3 as per SPN 9847.  Will report FB00h (64256) when engine is not running.";
CM_ SG_ 2364624126 Timing2Press "In-cylinder pressure for Cylinder #8 at user-defined timing location #2 as per SPN 9846.  Will report FB00h (64256) when engine is not running.";
CM_ SG_ 2364624126 Timing1Press "In-cylinder pressure for Cylinder #8 at user-defined timing location #1 as per SPN 9845.  Will report FB00h (64256) when engine is not running.";
CM_ BO_ 2364623870 "Engine Cylinder 7 Combustion Pressures
Used to transmit the combustion pressure at 4 user-defined timing locations for Engine Cylinder 7.";
CM_ SG_ 2364623870 Timing4Press "In-cylinder pressure for Cylinder #7 at user-defined timing location #4 as per SPN 9848.  Will report FB00h (64256) when engine is not running.";
CM_ SG_ 2364623870 Timing3Press "In-cylinder pressure for Cylinder #7 at user-defined timing location #3 as per SPN 9847.  Will report FB00h (64256) when engine is not running.";
CM_ SG_ 2364623870 Timing2Press "In-cylinder pressure for Cylinder #7 at user-defined timing location #2 as per SPN 9846.  Will report FB00h (64256) when engine is not running.";
CM_ SG_ 2364623870 Timing1Press "In-cylinder pressure for Cylinder #7 at user-defined timing location #1 as per SPN 9845.  Will report FB00h (64256) when engine is not running.";
CM_ BO_ 2364623614 "Engine Cylinder 6 Combustion Pressures
Used to transmit the combustion pressure at 4 user-defined timing locations for Engine Cylinder 6.";
CM_ SG_ 2364623614 Timing4Press "In-cylinder pressure for Cylinder #6 at user-defined timing location #4 as per SPN 9848.  Will report FB00h (64256) when engine is not running.";
CM_ SG_ 2364623614 Timing3Press "In-cylinder pressure for Cylinder #6 at user-defined timing location #3 as per SPN 9847.  Will report FB00h (64256) when engine is not running.";
CM_ SG_ 2364623614 Timing2Press "In-cylinder pressure for Cylinder #6 at user-defined timing location #2 as per SPN 9846.  Will report FB00h (64256) when engine is not running.";
CM_ SG_ 2364623614 Timing1Press "In-cylinder pressure for Cylinder #6 at user-defined timing location #1 as per SPN 9845.  Will report FB00h (64256) when engine is not running.";
CM_ BO_ 2364623358 "Engine Cylinder 5 Combustion Pressures
Used to transmit the combustion pressure at 4 user-defined timing locations for Engine Cylinder 5.";
CM_ SG_ 2364623358 Timing4Press "In-cylinder pressure for Cylinder #5 at user-defined timing location #4 as per SPN 9848.  Will report FB00h (64256) when engine is not running.";
CM_ SG_ 2364623358 Timing3Press "In-cylinder pressure for Cylinder #5 at user-defined timing location #3 as per SPN 9847.  Will report FB00h (64256) when engine is not running.";
CM_ SG_ 2364623358 Timing2Press "In-cylinder pressure for Cylinder #5 at user-defined timing location #2 as per SPN 9846.  Will report FB00h (64256) when engine is not running.";
CM_ SG_ 2364623358 Timing1Press "In-cylinder pressure for Cylinder #5 at user-defined timing location #1 as per SPN 9845.  Will report FB00h (64256) when engine is not running.";
CM_ BO_ 2364623102 "Engine Cylinder 4 Combustion Pressures
Used to transmit the combustion pressure at 4 user-defined timing locations for Engine Cylinder 4.";
CM_ SG_ 2364623102 Timing4Press "In-cylinder pressure for Cylinder #4 at user-defined timing location #4 as per SPN 9848.  Will report FB00h (64256) when engine is not running.";
CM_ SG_ 2364623102 Timing3Press "In-cylinder pressure for Cylinder #4 at user-defined timing location #3 as per SPN 9847.  Will report FB00h (64256) when engine is not running.";
CM_ SG_ 2364623102 Timing2Press "In-cylinder pressure for Cylinder #4 at user-defined timing location #2 as per SPN 9846.  Will report FB00h (64256) when engine is not running.";
CM_ SG_ 2364623102 Timing1Press "In-cylinder pressure for Cylinder #4 at user-defined timing location #1 as per SPN 9845.  Will report FB00h (64256) when engine is not running.";
CM_ BO_ 2364622846 "Engine Cylinder 3 Combustion Pressures
Used to transmit the combustion pressure at 4 user-defined timing locations for Engine Cylinder 3.";
CM_ SG_ 2364622846 Timing4Press "In-cylinder pressure for Cylinder #3 at user-defined timing location #4 as per SPN 9848.  Will report FB00h (64256) when engine is not running.";
CM_ SG_ 2364622846 Timing3Press "In-cylinder pressure for Cylinder #3 at user-defined timing location #3 as per SPN 9847.  Will report FB00h (64256) when engine is not running.";
CM_ SG_ 2364622846 Timing2Press "In-cylinder pressure for Cylinder #3 at user-defined timing location #2 as per SPN 9846.  Will report FB00h (64256) when engine is not running.";
CM_ SG_ 2364622846 Timing1Press "In-cylinder pressure for Cylinder #3 at user-defined timing location #1 as per SPN 9845.  Will report FB00h (64256) when engine is not running.";
CM_ BO_ 2364622590 "Engine Cylinder 2 Combustion Pressures
Used to transmit the combustion pressure at 4 user-defined timing locations for Engine Cylinder 2.";
CM_ SG_ 2364622590 Timing4Press "In-cylinder pressure for Cylinder #2 at user-defined timing location #4 as per SPN 9848.  Will report FB00h (64256) when engine is not running.";
CM_ SG_ 2364622590 Timing3Press "In-cylinder pressure for Cylinder #2 at user-defined timing location #3 as per SPN 9847.  Will report FB00h (64256) when engine is not running.";
CM_ SG_ 2364622590 Timing2Press "In-cylinder pressure for Cylinder #2 at user-defined timing location #2 as per SPN 9846.  Will report FB00h (64256) when engine is not running.";
CM_ SG_ 2364622590 Timing1Press "In-cylinder pressure for Cylinder #2 at user-defined timing location #1 as per SPN 9845.  Will report FB00h (64256) when engine is not running.";
BA_DEF_ SG_  "GenSigInactiveValue" INT 0 0;
BA_DEF_ SG_  "SigType" ENUM  "Default","Range","RangeSigned","ASCII","Discrete","Control","ReferencePGN","DTC","StringDelimiter","StringLength","StringLengthControl","MessageCounter","MessageChecksum";
BA_DEF_ SG_  "GenSigStartValue" INT 0 2147483647;
BA_DEF_ SG_  "GenSigSendType" ENUM  "Cyclic","OnWrite","OnWriteWithRepetition","OnChange","OnChangeWithRepetition","IfActive","IfActiveWithRepetition","NoSigSendType";
BA_DEF_ SG_  "GenSigILSupport" ENUM  "No","Yes";
BA_DEF_ SG_  "SPN" INT 0 524287;
BA_DEF_ BO_  "J1939CPgSendTimeout" INT -1 3600000;
BA_DEF_ BO_  "J1939CPgTOS" INT 0 7;
BA_DEF_ BO_  "J1939PgAppearanceOnBus" ENUM  "Default","CAN_Extended","CANFD_Extended";
BA_DEF_ BO_  "FsJ1939UseCrcAndCounter" STRING ;
BA_DEF_ BO_  "TpJ1939VarDlc" ENUM  "No","Yes";
BA_DEF_ BO_  "GenMsgNrOfRepetition" INT 0 1000000;
BA_DEF_ BO_  "GenMsgCycleTimeFast" INT 0 3600000;
BA_DEF_ BO_  "GenMsgFastOnStart" INT 0 100000;
BA_DEF_ BO_  "GenMsgStartDelayTime" INT 0 100000;
BA_DEF_ BO_  "GenMsgILSupport" ENUM  "No","Yes";
BA_DEF_ BO_  "GenMsgDelayTime" INT 0 1000;
BA_DEF_ BO_  "GenMsgRequestable" INT 0 1;
BA_DEF_ BO_  "GenMsgSendType" ENUM  "cyclic","NotUsed","NotUsed","NotUsed","NotUsed","NotUsed","NotUsed","IfActive","noMsgSendType";
BA_DEF_ BO_  "VFrameFormat" ENUM  "StandardCAN","ExtendedCAN","reserved","J1939PG","reserved","reserved","reserved","reserved","reserved","reserved","reserved","reserved","reserved","reserved","StandardCAN_FD","ExtendedCAN_FD";
BA_DEF_ BO_  "SingleFrame" INT 0 1;
BA_DEF_ BO_  "GenMsgCycleTime" INT 0 3600000;
BA_DEF_ SG_  "SystemSignalLongSymbol" STRING ;
BA_DEF_DEF_  "GenSigInactiveValue" 0;
BA_DEF_DEF_  "SigType" "Default";
BA_DEF_DEF_  "GenSigStartValue" 0;
BA_DEF_DEF_  "GenSigSendType" "NoSigSendType";
BA_DEF_DEF_  "GenSigILSupport" "Yes";
BA_DEF_DEF_  "SPN" 0;
BA_DEF_DEF_  "J1939CPgSendTimeout" -1;
BA_DEF_DEF_  "J1939CPgTOS" 2;
BA_DEF_DEF_  "J1939PgAppearanceOnBus" "Default";
BA_DEF_DEF_  "FsJ1939UseCrcAndCounter" "";
BA_DEF_DEF_  "TpJ1939VarDlc" "No";
BA_DEF_DEF_  "GenMsgNrOfRepetition" 0;
BA_DEF_DEF_  "GenMsgCycleTimeFast" 0;
BA_DEF_DEF_  "GenMsgFastOnStart" 0;
BA_DEF_DEF_  "GenMsgStartDelayTime" 0;
BA_DEF_DEF_  "GenMsgILSupport" "Yes";
BA_DEF_DEF_  "GenMsgDelayTime" 0;
BA_DEF_DEF_  "GenMsgRequestable" 1;
BA_DEF_DEF_  "GenMsgSendType" "noMsgSendType";
BA_DEF_DEF_  "VFrameFormat" "J1939PG";
BA_DEF_DEF_  "SingleFrame" 1;
BA_DEF_DEF_  "GenMsgCycleTime" 0;
BA_DEF_DEF_  "SystemSignalLongSymbol" "";
BA_ "FsJ1939UseCrcAndCounter" BO_ 2364643326 "Aa";
BA_ "GenMsgDelayTime" BO_ 2364643326 20;
BA_ "GenMsgSendType" BO_ 2364643326 0;
BA_ "GenMsgCycleTime" BO_ 2364643326 100;
BA_ "GenMsgSendType" BO_ 2364643070 0;
BA_ "GenMsgCycleTime" BO_ 2364643070 100;
BA_ "GenMsgSendType" BO_ 2364642814 0;
BA_ "GenMsgCycleTime" BO_ 2364642814 20;
BA_ "GenMsgSendType" BO_ 2364642558 0;
BA_ "GenMsgCycleTime" BO_ 2364642558 100;
BA_ "GenMsgSendType" BO_ 2364642302 0;
BA_ "GenMsgCycleTime" BO_ 2364642302 20;
BA_ "GenMsgSendType" BO_ 2364642046 0;
BA_ "GenMsgCycleTime" BO_ 2364642046 20;
BA_ "GenMsgSendType" BO_ 2364641790 0;
BA_ "GenMsgCycleTime" BO_ 2364641790 20;
BA_ "GenMsgSendType" BO_ 2364641534 0;
BA_ "GenMsgCycleTime" BO_ 2364641534 100;
BA_ "GenMsgSendType" BO_ 2297532414 0;
BA_ "GenMsgCycleTime" BO_ 2297532414 1000;
BA_ "FsJ1939UseCrcAndCounter" BO_ 2565967614 "Bc";
BA_ "GenMsgSendType" BO_ 2565967614 0;
BA_ "GenMsgCycleTime" BO_ 2565967614 100;
BA_ "FsJ1939UseCrcAndCounter" BO_ 2565967358 "Bc";
BA_ "GenMsgSendType" BO_ 2565967358 0;
BA_ "GenMsgCycleTime" BO_ 2565967358 100;
BA_ "FsJ1939UseCrcAndCounter" BO_ 2565967102 "Bc";
BA_ "GenMsgSendType" BO_ 2565967102 0;
BA_ "GenMsgCycleTime" BO_ 2565967102 100;
BA_ "FsJ1939UseCrcAndCounter" BO_ 2565966846 "Bc";
BA_ "GenMsgSendType" BO_ 2565966846 0;
BA_ "GenMsgCycleTime" BO_ 2565966846 100;
BA_ "GenMsgSendType" BO_ 2565966590 0;
BA_ "GenMsgCycleTime" BO_ 2565966590 100;
BA_ "FsJ1939UseCrcAndCounter" BO_ 2565966334 "Bc";
BA_ "GenMsgSendType" BO_ 2565966334 0;
BA_ "GenMsgCycleTime" BO_ 2565966334 100;
BA_ "FsJ1939UseCrcAndCounter" BO_ 2565966078 "Bc";
BA_ "GenMsgSendType" BO_ 2565966078 0;
BA_ "GenMsgCycleTime" BO_ 2565966078 100;
BA_ "FsJ1939UseCrcAndCounter" BO_ 2565965822 "Bc";
BA_ "GenMsgSendType" BO_ 2565965822 0;
BA_ "GenMsgCycleTime" BO_ 2565965822 100;
BA_ "FsJ1939UseCrcAndCounter" BO_ 2364638974 "Bc";
BA_ "GenMsgSendType" BO_ 2364638974 0;
BA_ "GenMsgCycleTime" BO_ 2364638974 100;
BA_ "GenMsgSendType" BO_ 2565965310 0;
BA_ "GenMsgCycleTime" BO_ 2565965310 100;
BA_ "FsJ1939UseCrcAndCounter" BO_ 2565965054 "Bc";
BA_ "GenMsgSendType" BO_ 2565965054 0;
BA_ "GenMsgCycleTime" BO_ 2565965054 100;
BA_ "FsJ1939UseCrcAndCounter" BO_ 2565964798 "Bc";
BA_ "GenMsgSendType" BO_ 2565964798 0;
BA_ "GenMsgCycleTime" BO_ 2565964798 100;
BA_ "FsJ1939UseCrcAndCounter" BO_ 2565964542 "Bc";
BA_ "GenMsgSendType" BO_ 2565964542 0;
BA_ "GenMsgCycleTime" BO_ 2565964542 100;
BA_ "FsJ1939UseCrcAndCounter" BO_ 2364637694 "Bc";
BA_ "GenMsgSendType" BO_ 2364637694 0;
BA_ "GenMsgCycleTime" BO_ 2364637694 100;
BA_ "GenMsgSendType" BO_ 2364637438 0;
BA_ "GenMsgCycleTime" BO_ 2364637438 1000;
BA_ "GenMsgSendType" BO_ 2364637182 0;
BA_ "GenMsgCycleTime" BO_ 2364637182 1000;
BA_ "GenMsgSendType" BO_ 2364636926 0;
BA_ "GenMsgCycleTime" BO_ 2364636926 1000;
BA_ "GenMsgSendType" BO_ 2364636670 0;
BA_ "GenMsgCycleTime" BO_ 2364636670 1000;
BA_ "GenMsgSendType" BO_ 2364636414 0;
BA_ "GenMsgCycleTime" BO_ 2364636414 1000;
BA_ "GenMsgSendType" BO_ 2364636158 0;
BA_ "GenMsgCycleTime" BO_ 2364636158 1000;
BA_ "GenMsgSendType" BO_ 2364635902 0;
BA_ "GenMsgCycleTime" BO_ 2364635902 1000;
BA_ "GenMsgSendType" BO_ 2364635646 0;
BA_ "GenMsgCycleTime" BO_ 2364635646 1000;
BA_ "GenMsgSendType" BO_ 2364635390 0;
BA_ "GenMsgCycleTime" BO_ 2364635390 1000;
BA_ "GenMsgSendType" BO_ 2364635134 0;
BA_ "GenMsgCycleTime" BO_ 2364635134 1000;
BA_ "GenMsgSendType" BO_ 2364634878 0;
BA_ "GenMsgCycleTime" BO_ 2364634878 1000;
BA_ "GenMsgSendType" BO_ 2364634622 0;
BA_ "GenMsgCycleTime" BO_ 2364634622 1000;
BA_ "GenMsgSendType" BO_ 2364634366 0;
BA_ "GenMsgCycleTime" BO_ 2364634366 1000;
BA_ "GenMsgSendType" BO_ 2364634110 0;
BA_ "GenMsgCycleTime" BO_ 2364634110 1000;
BA_ "GenMsgSendType" BO_ 2364633854 0;
BA_ "GenMsgCycleTime" BO_ 2364633854 1000;
BA_ "GenMsgSendType" BO_ 2364633598 0;
BA_ "GenMsgCycleTime" BO_ 2364633598 1000;
BA_ "GenMsgSendType" BO_ 2364633342 0;
BA_ "GenMsgCycleTime" BO_ 2364633342 1000;
BA_ "GenMsgSendType" BO_ 2364633086 0;
BA_ "GenMsgCycleTime" BO_ 2364633086 1000;
BA_ "GenMsgSendType" BO_ 2364632830 0;
BA_ "GenMsgCycleTime" BO_ 2364632830 1000;
BA_ "GenMsgSendType" BO_ 2364632574 0;
BA_ "GenMsgCycleTime" BO_ 2364632574 1000;
BA_ "GenMsgSendType" BO_ 2364632318 0;
BA_ "GenMsgCycleTime" BO_ 2364632318 1000;
BA_ "GenMsgSendType" BO_ 2364632062 0;
BA_ "GenMsgCycleTime" BO_ 2364632062 1000;
BA_ "GenMsgSendType" BO_ 2364631806 0;
BA_ "GenMsgCycleTime" BO_ 2364631806 1000;
BA_ "GenMsgSendType" BO_ 2364631550 0;
BA_ "GenMsgCycleTime" BO_ 2364631550 1000;
BA_ "GenMsgSendType" BO_ 2364631294 0;
BA_ "GenMsgCycleTime" BO_ 2364631294 1000;
BA_ "GenMsgSendType" BO_ 2364631038 0;
BA_ "GenMsgCycleTime" BO_ 2364631038 1000;
BA_ "GenMsgSendType" BO_ 2364630782 0;
BA_ "GenMsgCycleTime" BO_ 2364630782 1000;
BA_ "GenMsgSendType" BO_ 2364630526 0;
BA_ "GenMsgCycleTime" BO_ 2364630526 1000;
BA_ "GenMsgSendType" BO_ 2364630270 0;
BA_ "GenMsgCycleTime" BO_ 2364630270 1000;
BA_ "GenMsgSendType" BO_ 2364630014 0;
BA_ "GenMsgCycleTime" BO_ 2364630014 1000;
BA_ "GenMsgSendType" BO_ 2364629758 0;
BA_ "GenMsgCycleTime" BO_ 2364629758 1000;
BA_ "GenMsgSendType" BO_ 2364629502 0;
BA_ "GenMsgCycleTime" BO_ 2364629502 1000;
BA_ "GenMsgSendType" BO_ 2364629246 0;
BA_ "GenMsgCycleTime" BO_ 2364629246 1000;
BA_ "GenMsgSendType" BO_ 2364628990 0;
BA_ "GenMsgCycleTime" BO_ 2364628990 1000;
BA_ "GenMsgSendType" BO_ 2364628734 0;
BA_ "GenMsgCycleTime" BO_ 2364628734 1000;
BA_ "GenMsgSendType" BO_ 2364628478 0;
BA_ "GenMsgCycleTime" BO_ 2364628478 1000;
BA_ "GenMsgSendType" BO_ 2364628222 0;
BA_ "GenMsgCycleTime" BO_ 2364628222 1000;
BA_ "GenMsgSendType" BO_ 2364627966 0;
BA_ "GenMsgCycleTime" BO_ 2364627966 1000;
BA_ "GenMsgSendType" BO_ 2364627710 0;
BA_ "GenMsgCycleTime" BO_ 2364627710 1000;
BA_ "GenMsgSendType" BO_ 2364627454 0;
BA_ "GenMsgCycleTime" BO_ 2364627454 1000;
BA_ "GenMsgSendType" BO_ 2364627198 0;
BA_ "GenMsgCycleTime" BO_ 2364627198 1000;
BA_ "GenMsgSendType" BO_ 2364626942 0;
BA_ "GenMsgCycleTime" BO_ 2364626942 1000;
BA_ "GenMsgSendType" BO_ 2364626686 0;
BA_ "GenMsgCycleTime" BO_ 2364626686 1000;
BA_ "GenMsgSendType" BO_ 2364626430 0;
BA_ "GenMsgCycleTime" BO_ 2364626430 1000;
BA_ "GenMsgSendType" BO_ 2364626174 0;
BA_ "GenMsgCycleTime" BO_ 2364626174 1000;
BA_ "GenMsgSendType" BO_ 2364625918 0;
BA_ "GenMsgCycleTime" BO_ 2364625918 1000;
BA_ "GenMsgSendType" BO_ 2364625662 0;
BA_ "GenMsgCycleTime" BO_ 2364625662 1000;
BA_ "GenMsgSendType" BO_ 2364625406 0;
BA_ "GenMsgCycleTime" BO_ 2364625406 1000;
BA_ "GenMsgSendType" BO_ 2364625150 0;
BA_ "GenMsgCycleTime" BO_ 2364625150 1000;
BA_ "GenMsgSendType" BO_ 2364624894 0;
BA_ "GenMsgCycleTime" BO_ 2364624894 1000;
BA_ "GenMsgSendType" BO_ 2364624638 0;
BA_ "GenMsgCycleTime" BO_ 2364624638 1000;
BA_ "GenMsgSendType" BO_ 2364624382 0;
BA_ "GenMsgCycleTime" BO_ 2364624382 1000;
BA_ "GenMsgSendType" BO_ 2364624126 0;
BA_ "GenMsgCycleTime" BO_ 2364624126 1000;
BA_ "GenMsgSendType" BO_ 2364623870 0;
BA_ "GenMsgCycleTime" BO_ 2364623870 1000;
BA_ "GenMsgSendType" BO_ 2364623614 0;
BA_ "GenMsgCycleTime" BO_ 2364623614 1000;
BA_ "GenMsgSendType" BO_ 2364623358 0;
BA_ "GenMsgCycleTime" BO_ 2364623358 1000;
BA_ "GenMsgSendType" BO_ 2364623102 0;
BA_ "GenMsgCycleTime" BO_ 2364623102 1000;
BA_ "GenMsgSendType" BO_ 2364622846 0;
BA_ "GenMsgCycleTime" BO_ 2364622846 1000;
BA_ "GenMsgSendType" BO_ 2364622590 0;
BA_ "GenMsgCycleTime" BO_ 2364622590 1000;
BA_ "SigType" SG_ 2364643326 Status1CRC 12;
BA_ "SPN" SG_ 2364643326 Status1CRC 13016;
BA_ "SigType" SG_ 2364643326 Status1Counter 11;
BA_ "SPN" SG_ 2364643326 Status1Counter 13015;
BA_ "SPN" SG_ 2364643326 OperationalStatus 11089;
BA_ "SPN" SG_ 2364643326 HVBusConnectionStatus 11088;
BA_ "SigType" SG_ 2364643326 InternalChargerStatus 5;
BA_ "SPN" SG_ 2364643326 InternalChargerStatus 11087;
BA_ "SigType" SG_ 2364643326 CellBalancingActive 4;
BA_ "SPN" SG_ 2364643326 CellBalancingActive 11086;
BA_ "SigType" SG_ 2364643326 CellBalanceStatus 4;
BA_ "SPN" SG_ 2364643326 CellBalanceStatus 11085;
BA_ "SPN" SG_ 2364643326 StOfChargeStatus 11084;
BA_ "SigType" SG_ 2364643326 InertiaSwStatus 4;
BA_ "SPN" SG_ 2364643326 InertiaSwStatus 11083;
BA_ "SigType" SG_ 2364643326 HVILStatus 4;
BA_ "SPN" SG_ 2364643326 HVILStatus 11082;
BA_ "SPN" SG_ 2364643326 HVBusPassiveIsolTestStatus 11081;
BA_ "SPN" SG_ 2364643326 HVBusActiveIsolTestStatus 11080;
BA_ "SigType" SG_ 2364643326 CenterOfPackContactorSt 4;
BA_ "SPN" SG_ 2364643326 CenterOfPackContactorSt 11079;
BA_ "SigType" SG_ 2364643326 HVBusPreChargeRelaySt 4;
BA_ "SPN" SG_ 2364643326 HVBusPreChargeRelaySt 11078;
BA_ "SPN" SG_ 2364643326 HVBusDisconnectForewarning 11077;
BA_ "SigType" SG_ 2364643326 HVBusContactorSt11076 4;
BA_ "SPN" SG_ 2364643326 HVBusContactorSt11076 11076;
BA_ "SigType" SG_ 2364643326 HVBusContactorSt 4;
BA_ "SPN" SG_ 2364643326 HVBusContactorSt 11075;
BA_ "SigType" SG_ 2364643070 Temp 1;
BA_ "SPN" SG_ 2364643070 Temp 11074;
BA_ "SigType" SG_ 2364643070 ETemp 1;
BA_ "SPN" SG_ 2364643070 ETemp 11073;
BA_ "SigType" SG_ 2364643070 OutCoolantTemp 1;
BA_ "SPN" SG_ 2364643070 OutCoolantTemp 11072;
BA_ "SigType" SG_ 2364643070 InCoolantTemp 1;
BA_ "SPN" SG_ 2364643070 InCoolantTemp 11071;
BA_ "SigType" SG_ 2364643070 IgntV 1;
BA_ "SPN" SG_ 2364643070 IgntV 11070;
BA_ "SigType" SG_ 2364643070 BusV 1;
BA_ "SPN" SG_ 2364643070 BusV 11069;
BA_ "SigType" SG_ 2364642814 HighestCellStOfCharge 1;
BA_ "SPN" SG_ 2364642814 HighestCellStOfCharge 11068;
BA_ "SigType" SG_ 2364642814 LowestCellStOfCharge 1;
BA_ "SPN" SG_ 2364642814 LowestCellStOfCharge 11067;
BA_ "SigType" SG_ 2364642814 ChargeCurLmt 1;
BA_ "GenSigStartValue" SG_ 2364642814 ChargeCurLmt 32000;
BA_ "SPN" SG_ 2364642814 ChargeCurLmt 11066;
BA_ "SigType" SG_ 2364642814 DisCurLmt 1;
BA_ "SPN" SG_ 2364642814 DisCurLmt 11065;
BA_ "SigType" SG_ 2364642558 CellBalancingCount 1;
BA_ "SPN" SG_ 2364642558 CellBalancingCount 11064;
BA_ "SigType" SG_ 2364642558 ChargeCapacity 1;
BA_ "SPN" SG_ 2364642558 ChargeCapacity 11063;
BA_ "SigType" SG_ 2364642558 DisCapacity 1;
BA_ "SPN" SG_ 2364642558 DisCapacity 11062;
BA_ "SigType" SG_ 2364642302 CellTempDiffStatus 4;
BA_ "SPN" SG_ 2364642302 CellTempDiffStatus 11061;
BA_ "SigType" SG_ 2364642302 AvgCellTemp 1;
BA_ "SPN" SG_ 2364642302 AvgCellTemp 11060;
BA_ "SigType" SG_ 2364642302 LowestCellTemp 1;
BA_ "SPN" SG_ 2364642302 LowestCellTemp 11059;
BA_ "SigType" SG_ 2364642302 HighestCellTemp 1;
BA_ "SPN" SG_ 2364642302 HighestCellTemp 11058;
BA_ "SPN" SG_ 2364642046 CellVDiffStatus 11057;
BA_ "SigType" SG_ 2364642046 LowestCellV 1;
BA_ "SPN" SG_ 2364642046 LowestCellV 11056;
BA_ "SigType" SG_ 2364642046 HighestCellV 1;
BA_ "SPN" SG_ 2364642046 HighestCellV 11055;
BA_ "SigType" SG_ 2364642046 FastUpdateStOfCharge 1;
BA_ "SPN" SG_ 2364642046 FastUpdateStOfCharge 11054;
BA_ "SigType" SG_ 2364641790 Cur 1;
BA_ "SPN" SG_ 2364641790 Cur 11053;
BA_ "SigType" SG_ 2364641790 Lvl 1;
BA_ "SPN" SG_ 2364641790 Lvl 11052;
BA_ "SigType" SG_ 2364641790 AvailableChargePwr 1;
BA_ "SPN" SG_ 2364641790 AvailableChargePwr 11051;
BA_ "SigType" SG_ 2364641790 AvailableDisPwr 1;
BA_ "SPN" SG_ 2364641790 AvailableDisPwr 11050;
BA_ "SigType" SG_ 2364641534 ChargePLDueToAnUndefinedCause 4;
BA_ "SPN" SG_ 2364641534 ChargePLDueToAnUndefinedCause 11049;
BA_ "SigType" SG_ 2364641534 ChargePLDueToBatCur 4;
BA_ "SPN" SG_ 2364641534 ChargePLDueToBatCur 11048;
BA_ "SigType" SG_ 2364641534 ChargePLDueToBatOrCellV 4;
BA_ "SPN" SG_ 2364641534 ChargePLDueToBatOrCellV 11047;
BA_ "SigType" SG_ 2364641534 ChargePLDueToBatDiagCondition 4;
BA_ "SPN" SG_ 2364641534 ChargePLDueToBatDiagCondition 11046;
BA_ "SigType" SG_ 2364641534 ChargePLDueToBatTemp 4;
BA_ "SPN" SG_ 2364641534 ChargePLDueToBatTemp 11045;
BA_ "SigType" SG_ 2364641534 ChargePLDueToStOfCharge 4;
BA_ "SPN" SG_ 2364641534 ChargePLDueToStOfCharge 11044;
BA_ "SigType" SG_ 2364641534 DisPLDueToAnUndefinedCause 4;
BA_ "SPN" SG_ 2364641534 DisPLDueToAnUndefinedCause 11043;
BA_ "SigType" SG_ 2364641534 DisPLDueToBatCur 4;
BA_ "SPN" SG_ 2364641534 DisPLDueToBatCur 11042;
BA_ "SigType" SG_ 2364641534 DisPLDueToBatOrCellV 4;
BA_ "SPN" SG_ 2364641534 DisPLDueToBatOrCellV 11041;
BA_ "SigType" SG_ 2364641534 DisPLDueToBatDiagCondition 4;
BA_ "SPN" SG_ 2364641534 DisPLDueToBatDiagCondition 11040;
BA_ "SigType" SG_ 2364641534 DisPLDueToBatTemp 4;
BA_ "SPN" SG_ 2364641534 DisPLDueToBatTemp 11039;
BA_ "SigType" SG_ 2364641534 DisPLDueToStOfCharge 4;
BA_ "SPN" SG_ 2364641534 DisPLDueToStOfCharge 11038;
BA_ "SigType" SG_ 2297532414 TimeSinceLastImposterPGDetected 1;
BA_ "SPN" SG_ 2297532414 TimeSinceLastImposterPGDetected 10844;
BA_ "SPN" SG_ 2297532414 PGN 10843;
BA_ "SPN" SG_ 2297532414 DestinationAddress 10842;
BA_ "SPN" SG_ 2297532414 SA 10841;
BA_ "SigType" SG_ 2297532414 EventDetectionCounter 1;
BA_ "SPN" SG_ 2297532414 EventDetectionCounter 10840;
BA_ "SPN" SG_ 2565967614 AbsTrqRateLmt 10839;
BA_ "SPN" SG_ 2565967614 AbsSpdRateLmt 10838;
BA_ "SigType" SG_ 2565967614 Counter 11;
BA_ "SPN" SG_ 2565967614 Counter 10837;
BA_ "SigType" SG_ 2565967614 CRC 12;
BA_ "SPN" SG_ 2565967614 CRC 10836;
BA_ "SPN" SG_ 2565967358 AvailableMinTrq 10805;
BA_ "SPN" SG_ 2565967358 AvailableMaxTrq 10804;
BA_ "SigType" SG_ 2565967358 Counter 11;
BA_ "SPN" SG_ 2565967358 Counter 10803;
BA_ "SigType" SG_ 2565967358 CRC 12;
BA_ "SPN" SG_ 2565967358 CRC 10802;
BA_ "SPN" SG_ 2565967102 AbsTrqRateLmt 10801;
BA_ "SPN" SG_ 2565967102 AbsSpdRateLmt 10800;
BA_ "SigType" SG_ 2565967102 Counter 11;
BA_ "SPN" SG_ 2565967102 Counter 10799;
BA_ "SigType" SG_ 2565967102 CRC 12;
BA_ "SPN" SG_ 2565967102 CRC 10798;
BA_ "SPN" SG_ 2565966846 AvailableMinTrq 10767;
BA_ "SPN" SG_ 2565966846 AvailableMaxTrq 10766;
BA_ "SigType" SG_ 2565966846 Counter 11;
BA_ "SPN" SG_ 2565966846 Counter 10765;
BA_ "SigType" SG_ 2565966846 CRC 12;
BA_ "SPN" SG_ 2565966846 CRC 10764;
BA_ "SigType" SG_ 2565966590 UnswitchedSLIV 1;
BA_ "SPN" SG_ 2565966590 UnswitchedSLIV 9118;
BA_ "SigType" SG_ 2565966590 SwitchedIgntV 1;
BA_ "SPN" SG_ 2565966590 SwitchedIgntV 9106;
BA_ "SPN" SG_ 2565966334 CurMin 10281;
BA_ "SPN" SG_ 2565966334 CurMax 10280;
BA_ "SPN" SG_ 2565966334 VMin 10279;
BA_ "SPN" SG_ 2565966334 VMax 10278;
BA_ "SigType" SG_ 2565966334 Counter 11;
BA_ "SPN" SG_ 2565966334 Counter 10277;
BA_ "SigType" SG_ 2565966334 CRC 12;
BA_ "SPN" SG_ 2565966334 CRC 10276;
BA_ "SPN" SG_ 2565966078 SpdMin 10265;
BA_ "SPN" SG_ 2565966078 SpdMax 10264;
BA_ "SPN" SG_ 2565966078 TrqMin 10263;
BA_ "SPN" SG_ 2565966078 TrqMax 10262;
BA_ "SigType" SG_ 2565966078 Counter 11;
BA_ "SPN" SG_ 2565966078 Counter 10261;
BA_ "SigType" SG_ 2565966078 CRC 12;
BA_ "SPN" SG_ 2565966078 CRC 10260;
BA_ "SPN" SG_ 2565965822 DCSidePwrMin 10253;
BA_ "SPN" SG_ 2565965822 DCSidePwrMax 10252;
BA_ "SPN" SG_ 2565965822 MechPwrMin 10251;
BA_ "SPN" SG_ 2565965822 MechPwrMax 10250;
BA_ "SigType" SG_ 2565965822 Counter 11;
BA_ "SPN" SG_ 2565965822 Counter 10249;
BA_ "SigType" SG_ 2565965822 CRC 12;
BA_ "SPN" SG_ 2565965822 CRC 10248;
BA_ "SigType" SG_ 2364638974 HVILStatus 4;
BA_ "SPN" SG_ 2364638974 HVILStatus 9104;
BA_ "SPN" SG_ 2364638974 CtrlSetpointMode 10233;
BA_ "SPN" SG_ 2364638974 CtrlLimitsOvrdMode 10232;
BA_ "SigType" SG_ 2364638974 Counter 11;
BA_ "SPN" SG_ 2364638974 Counter 10231;
BA_ "SigType" SG_ 2364638974 CRC 12;
BA_ "SPN" SG_ 2364638974 CRC 10230;
BA_ "SigType" SG_ 2565965310 UnswitchedSLIV 1;
BA_ "SPN" SG_ 2565965310 UnswitchedSLIV 9117;
BA_ "SigType" SG_ 2565965310 SwitchedIgntV 1;
BA_ "SPN" SG_ 2565965310 SwitchedIgntV 9105;
BA_ "SPN" SG_ 2565965054 CurMin 10215;
BA_ "SPN" SG_ 2565965054 CurMax 10214;
BA_ "SPN" SG_ 2565965054 VMin 10213;
BA_ "SPN" SG_ 2565965054 VMax 10212;
BA_ "SigType" SG_ 2565965054 Counter 11;
BA_ "SPN" SG_ 2565965054 Counter 10211;
BA_ "SigType" SG_ 2565965054 CRC 12;
BA_ "SPN" SG_ 2565965054 CRC 10210;
BA_ "SPN" SG_ 2565964798 SpdMin 10199;
BA_ "SPN" SG_ 2565964798 SpdMax 10198;
BA_ "SPN" SG_ 2565964798 TrqMin 10197;
BA_ "SPN" SG_ 2565964798 TrqMax 10196;
BA_ "SigType" SG_ 2565964798 Counter 11;
BA_ "SPN" SG_ 2565964798 Counter 10195;
BA_ "SigType" SG_ 2565964798 CRC 12;
BA_ "SPN" SG_ 2565964798 CRC 10194;
BA_ "SPN" SG_ 2565964542 DCSidePwrMin 10187;
BA_ "SPN" SG_ 2565964542 DCSidePwrMax 10186;
BA_ "SPN" SG_ 2565964542 MechPwrMin 10185;
BA_ "SPN" SG_ 2565964542 MechPwrMax 10184;
BA_ "SigType" SG_ 2565964542 Counter 11;
BA_ "SPN" SG_ 2565964542 Counter 10183;
BA_ "SigType" SG_ 2565964542 CRC 12;
BA_ "SPN" SG_ 2565964542 CRC 10182;
BA_ "SigType" SG_ 2364637694 HVILStatus 4;
BA_ "SPN" SG_ 2364637694 HVILStatus 9103;
BA_ "SPN" SG_ 2364637694 CtrlSetpointMode 10167;
BA_ "SPN" SG_ 2364637694 CtrlLimitsOvrdMode 10166;
BA_ "SigType" SG_ 2364637694 Counter 11;
BA_ "SPN" SG_ 2364637694 Counter 10165;
BA_ "SigType" SG_ 2364637694 CRC 12;
BA_ "SPN" SG_ 2364637694 CRC 10164;
BA_ "SigType" SG_ 2364637438 Temp 1;
BA_ "SPN" SG_ 2364637438 Temp 10758;
BA_ "SigType" SG_ 2364637438 MisfireRate 1;
BA_ "SPN" SG_ 2364637438 MisfireRate 1342;
BA_ "SigType" SG_ 2364637438 IndMeanEffPressCV 1;
BA_ "SPN" SG_ 2364637438 IndMeanEffPressCV 10076;
BA_ "SigType" SG_ 2364637438 InstantaneousIndMeanEffPress 1;
BA_ "SPN" SG_ 2364637438 InstantaneousIndMeanEffPress 10075;
BA_ "SigType" SG_ 2364637438 InstantaneousPeakCombPressTiming 1;
BA_ "SPN" SG_ 2364637438 InstantaneousPeakCombPressTiming 10074;
BA_ "SigType" SG_ 2364637182 Temp 1;
BA_ "SPN" SG_ 2364637182 Temp 10757;
BA_ "SigType" SG_ 2364637182 MisfireRate 1;
BA_ "SPN" SG_ 2364637182 MisfireRate 1341;
BA_ "SigType" SG_ 2364637182 IndMeanEffPressCV 1;
BA_ "SPN" SG_ 2364637182 IndMeanEffPressCV 10073;
BA_ "SigType" SG_ 2364637182 InstantaneousIndMeanEffPress 1;
BA_ "SPN" SG_ 2364637182 InstantaneousIndMeanEffPress 10072;
BA_ "SigType" SG_ 2364637182 InstantaneousPeakCombPressTiming 1;
BA_ "SPN" SG_ 2364637182 InstantaneousPeakCombPressTiming 10071;
BA_ "SigType" SG_ 2364636926 Temp 1;
BA_ "SPN" SG_ 2364636926 Temp 10756;
BA_ "SigType" SG_ 2364636926 MisfireRate 1;
BA_ "SPN" SG_ 2364636926 MisfireRate 1340;
BA_ "SigType" SG_ 2364636926 IndMeanEffPressCV 1;
BA_ "SPN" SG_ 2364636926 IndMeanEffPressCV 10070;
BA_ "SigType" SG_ 2364636926 InstantaneousIndMeanEffPress 1;
BA_ "SPN" SG_ 2364636926 InstantaneousIndMeanEffPress 10069;
BA_ "SigType" SG_ 2364636926 InstantaneousPeakCombPressTiming 1;
BA_ "SPN" SG_ 2364636926 InstantaneousPeakCombPressTiming 10068;
BA_ "SigType" SG_ 2364636670 Temp 1;
BA_ "SPN" SG_ 2364636670 Temp 10755;
BA_ "SigType" SG_ 2364636670 MisfireRate 1;
BA_ "SPN" SG_ 2364636670 MisfireRate 1339;
BA_ "SigType" SG_ 2364636670 IndMeanEffPressCV 1;
BA_ "SPN" SG_ 2364636670 IndMeanEffPressCV 10067;
BA_ "SigType" SG_ 2364636670 InstantaneousIndMeanEffPress 1;
BA_ "SPN" SG_ 2364636670 InstantaneousIndMeanEffPress 10066;
BA_ "SigType" SG_ 2364636670 InstantaneousPeakCombPressTiming 1;
BA_ "SPN" SG_ 2364636670 InstantaneousPeakCombPressTiming 10065;
BA_ "SigType" SG_ 2364636414 Temp 1;
BA_ "SPN" SG_ 2364636414 Temp 10754;
BA_ "SigType" SG_ 2364636414 MisfireRate 1;
BA_ "SPN" SG_ 2364636414 MisfireRate 1338;
BA_ "SigType" SG_ 2364636414 IndMeanEffPressCV 1;
BA_ "SPN" SG_ 2364636414 IndMeanEffPressCV 10064;
BA_ "SigType" SG_ 2364636414 InstantaneousIndMeanEffPress 1;
BA_ "SPN" SG_ 2364636414 InstantaneousIndMeanEffPress 10063;
BA_ "SigType" SG_ 2364636414 InstantaneousPeakCombPressTiming 1;
BA_ "SPN" SG_ 2364636414 InstantaneousPeakCombPressTiming 10062;
BA_ "SigType" SG_ 2364636158 Temp 1;
BA_ "SPN" SG_ 2364636158 Temp 10753;
BA_ "SigType" SG_ 2364636158 MisfireRate 1;
BA_ "SPN" SG_ 2364636158 MisfireRate 1337;
BA_ "SigType" SG_ 2364636158 IndMeanEffPressCV 1;
BA_ "SPN" SG_ 2364636158 IndMeanEffPressCV 10061;
BA_ "SigType" SG_ 2364636158 InstantaneousIndMeanEffPress 1;
BA_ "SPN" SG_ 2364636158 InstantaneousIndMeanEffPress 10060;
BA_ "SigType" SG_ 2364636158 InstantaneousPeakCombPressTiming 1;
BA_ "SPN" SG_ 2364636158 InstantaneousPeakCombPressTiming 10059;
BA_ "SigType" SG_ 2364635902 Temp 1;
BA_ "SPN" SG_ 2364635902 Temp 10752;
BA_ "SigType" SG_ 2364635902 MisfireRate 1;
BA_ "SPN" SG_ 2364635902 MisfireRate 1336;
BA_ "SigType" SG_ 2364635902 IndMeanEffPressCV 1;
BA_ "SPN" SG_ 2364635902 IndMeanEffPressCV 10058;
BA_ "SigType" SG_ 2364635902 InstantaneousIndMeanEffPress 1;
BA_ "SPN" SG_ 2364635902 InstantaneousIndMeanEffPress 10057;
BA_ "SigType" SG_ 2364635902 InstantaneousPeakCombPressTiming 1;
BA_ "SPN" SG_ 2364635902 InstantaneousPeakCombPressTiming 10056;
BA_ "SigType" SG_ 2364635646 Temp 1;
BA_ "SPN" SG_ 2364635646 Temp 10751;
BA_ "SigType" SG_ 2364635646 MisfireRate 1;
BA_ "SPN" SG_ 2364635646 MisfireRate 1335;
BA_ "SigType" SG_ 2364635646 IndMeanEffPressCV 1;
BA_ "SPN" SG_ 2364635646 IndMeanEffPressCV 10055;
BA_ "SigType" SG_ 2364635646 InstantaneousIndMeanEffPress 1;
BA_ "SPN" SG_ 2364635646 InstantaneousIndMeanEffPress 10054;
BA_ "SigType" SG_ 2364635646 InstantaneousPeakCombPressTiming 1;
BA_ "SPN" SG_ 2364635646 InstantaneousPeakCombPressTiming 10053;
BA_ "SigType" SG_ 2364635390 Temp 1;
BA_ "SPN" SG_ 2364635390 Temp 10750;
BA_ "SigType" SG_ 2364635390 MisfireRate 1;
BA_ "SPN" SG_ 2364635390 MisfireRate 1334;
BA_ "SigType" SG_ 2364635390 IndMeanEffPressCV 1;
BA_ "SPN" SG_ 2364635390 IndMeanEffPressCV 10052;
BA_ "SigType" SG_ 2364635390 InstantaneousIndMeanEffPress 1;
BA_ "SPN" SG_ 2364635390 InstantaneousIndMeanEffPress 10051;
BA_ "SigType" SG_ 2364635390 InstantaneousPeakCombPressTiming 1;
BA_ "SPN" SG_ 2364635390 InstantaneousPeakCombPressTiming 10050;
BA_ "SigType" SG_ 2364635134 Temp 1;
BA_ "SPN" SG_ 2364635134 Temp 10749;
BA_ "SigType" SG_ 2364635134 MisfireRate 1;
BA_ "SPN" SG_ 2364635134 MisfireRate 1333;
BA_ "SigType" SG_ 2364635134 IndMeanEffPressCV 1;
BA_ "SPN" SG_ 2364635134 IndMeanEffPressCV 10049;
BA_ "SigType" SG_ 2364635134 InstantaneousIndMeanEffPress 1;
BA_ "SPN" SG_ 2364635134 InstantaneousIndMeanEffPress 10048;
BA_ "SigType" SG_ 2364635134 InstantaneousPeakCombPressTiming 1;
BA_ "SPN" SG_ 2364635134 InstantaneousPeakCombPressTiming 10047;
BA_ "SigType" SG_ 2364634878 Temp 1;
BA_ "SPN" SG_ 2364634878 Temp 10748;
BA_ "SigType" SG_ 2364634878 MisfireRate 1;
BA_ "SPN" SG_ 2364634878 MisfireRate 1332;
BA_ "SigType" SG_ 2364634878 IndMeanEffPressCV 1;
BA_ "SPN" SG_ 2364634878 IndMeanEffPressCV 10046;
BA_ "SigType" SG_ 2364634878 InstantaneousIndMeanEffPress 1;
BA_ "SPN" SG_ 2364634878 InstantaneousIndMeanEffPress 10045;
BA_ "SigType" SG_ 2364634878 InstantaneousPeakCombPressTiming 1;
BA_ "SPN" SG_ 2364634878 InstantaneousPeakCombPressTiming 10044;
BA_ "SigType" SG_ 2364634622 Temp 1;
BA_ "SPN" SG_ 2364634622 Temp 10747;
BA_ "SigType" SG_ 2364634622 MisfireRate 1;
BA_ "SPN" SG_ 2364634622 MisfireRate 1331;
BA_ "SigType" SG_ 2364634622 IndMeanEffPressCV 1;
BA_ "SPN" SG_ 2364634622 IndMeanEffPressCV 10043;
BA_ "SigType" SG_ 2364634622 InstantaneousIndMeanEffPress 1;
BA_ "SPN" SG_ 2364634622 InstantaneousIndMeanEffPress 10042;
BA_ "SigType" SG_ 2364634622 InstantaneousPeakCombPressTiming 1;
BA_ "SPN" SG_ 2364634622 InstantaneousPeakCombPressTiming 10041;
BA_ "SigType" SG_ 2364634366 Temp 1;
BA_ "SPN" SG_ 2364634366 Temp 10746;
BA_ "SigType" SG_ 2364634366 MisfireRate 1;
BA_ "SPN" SG_ 2364634366 MisfireRate 1330;
BA_ "SigType" SG_ 2364634366 IndMeanEffPressCV 1;
BA_ "SPN" SG_ 2364634366 IndMeanEffPressCV 10040;
BA_ "SigType" SG_ 2364634366 InstantaneousIndMeanEffPress 1;
BA_ "SPN" SG_ 2364634366 InstantaneousIndMeanEffPress 10039;
BA_ "SigType" SG_ 2364634366 InstantaneousPeakCombPressTiming 1;
BA_ "SPN" SG_ 2364634366 InstantaneousPeakCombPressTiming 10038;
BA_ "SigType" SG_ 2364634110 Temp 1;
BA_ "SPN" SG_ 2364634110 Temp 10745;
BA_ "SigType" SG_ 2364634110 MisfireRate 1;
BA_ "SPN" SG_ 2364634110 MisfireRate 1329;
BA_ "SigType" SG_ 2364634110 IndMeanEffPressCV 1;
BA_ "SPN" SG_ 2364634110 IndMeanEffPressCV 10037;
BA_ "SigType" SG_ 2364634110 InstantaneousIndMeanEffPress 1;
BA_ "SPN" SG_ 2364634110 InstantaneousIndMeanEffPress 10036;
BA_ "SigType" SG_ 2364634110 InstantaneousPeakCombPressTiming 1;
BA_ "SPN" SG_ 2364634110 InstantaneousPeakCombPressTiming 10035;
BA_ "SigType" SG_ 2364633854 Temp 1;
BA_ "SPN" SG_ 2364633854 Temp 10744;
BA_ "SigType" SG_ 2364633854 MisfireRate 1;
BA_ "SPN" SG_ 2364633854 MisfireRate 1328;
BA_ "SigType" SG_ 2364633854 IndMeanEffPressCV 1;
BA_ "SPN" SG_ 2364633854 IndMeanEffPressCV 10034;
BA_ "SigType" SG_ 2364633854 InstantaneousIndMeanEffPress 1;
BA_ "SPN" SG_ 2364633854 InstantaneousIndMeanEffPress 10033;
BA_ "SigType" SG_ 2364633854 InstantaneousPeakCombPressTiming 1;
BA_ "SPN" SG_ 2364633854 InstantaneousPeakCombPressTiming 10032;
BA_ "SigType" SG_ 2364633598 Temp 1;
BA_ "SPN" SG_ 2364633598 Temp 10743;
BA_ "SigType" SG_ 2364633598 MisfireRate 1;
BA_ "SPN" SG_ 2364633598 MisfireRate 1327;
BA_ "SigType" SG_ 2364633598 IndMeanEffPressCV 1;
BA_ "SPN" SG_ 2364633598 IndMeanEffPressCV 10031;
BA_ "SigType" SG_ 2364633598 InstantaneousIndMeanEffPress 1;
BA_ "SPN" SG_ 2364633598 InstantaneousIndMeanEffPress 10030;
BA_ "SigType" SG_ 2364633598 InstantaneousPeakCombPressTiming 1;
BA_ "SPN" SG_ 2364633598 InstantaneousPeakCombPressTiming 10029;
BA_ "SigType" SG_ 2364633342 Temp 1;
BA_ "SPN" SG_ 2364633342 Temp 10742;
BA_ "SigType" SG_ 2364633342 MisfireRate 1;
BA_ "SPN" SG_ 2364633342 MisfireRate 1326;
BA_ "SigType" SG_ 2364633342 IndMeanEffPressCV 1;
BA_ "SPN" SG_ 2364633342 IndMeanEffPressCV 10028;
BA_ "SigType" SG_ 2364633342 InstantaneousIndMeanEffPress 1;
BA_ "SPN" SG_ 2364633342 InstantaneousIndMeanEffPress 10027;
BA_ "SigType" SG_ 2364633342 InstantaneousPeakCombPressTiming 1;
BA_ "SPN" SG_ 2364633342 InstantaneousPeakCombPressTiming 10026;
BA_ "SigType" SG_ 2364633086 Temp 1;
BA_ "SPN" SG_ 2364633086 Temp 10741;
BA_ "SigType" SG_ 2364633086 MisfireRate 1;
BA_ "SPN" SG_ 2364633086 MisfireRate 1325;
BA_ "SigType" SG_ 2364633086 IndMeanEffPressCV 1;
BA_ "SPN" SG_ 2364633086 IndMeanEffPressCV 10025;
BA_ "SigType" SG_ 2364633086 InstantaneousIndMeanEffPress 1;
BA_ "SPN" SG_ 2364633086 InstantaneousIndMeanEffPress 10024;
BA_ "SigType" SG_ 2364633086 InstantaneousPeakCombPressTiming 1;
BA_ "SPN" SG_ 2364633086 InstantaneousPeakCombPressTiming 10023;
BA_ "SigType" SG_ 2364632830 Temp 1;
BA_ "SPN" SG_ 2364632830 Temp 10740;
BA_ "SigType" SG_ 2364632830 MisfireRate 1;
BA_ "SPN" SG_ 2364632830 MisfireRate 1324;
BA_ "SigType" SG_ 2364632830 IndMeanEffPressCV 1;
BA_ "SPN" SG_ 2364632830 IndMeanEffPressCV 10022;
BA_ "SigType" SG_ 2364632830 InstantaneousIndMeanEffPress 1;
BA_ "SPN" SG_ 2364632830 InstantaneousIndMeanEffPress 10021;
BA_ "SigType" SG_ 2364632830 InstantaneousPeakCombPressTiming 1;
BA_ "SPN" SG_ 2364632830 InstantaneousPeakCombPressTiming 10020;
BA_ "SigType" SG_ 2364632574 Temp 1;
BA_ "SPN" SG_ 2364632574 Temp 10739;
BA_ "SigType" SG_ 2364632574 MisfireRate 1;
BA_ "SPN" SG_ 2364632574 MisfireRate 1323;
BA_ "SigType" SG_ 2364632574 IndMeanEffPressCV 1;
BA_ "SPN" SG_ 2364632574 IndMeanEffPressCV 10019;
BA_ "SigType" SG_ 2364632574 InstantaneousIndMeanEffPress 1;
BA_ "SPN" SG_ 2364632574 InstantaneousIndMeanEffPress 10018;
BA_ "SigType" SG_ 2364632574 InstantaneousPeakCombPressTiming 1;
BA_ "SPN" SG_ 2364632574 InstantaneousPeakCombPressTiming 10017;
BA_ "SigType" SG_ 2364632318 InstantaneousCombTimingPoint2 1;
BA_ "SPN" SG_ 2364632318 InstantaneousCombTimingPoint2 10016;
BA_ "SigType" SG_ 2364632318 InstantaneousCombTimingPoint1 1;
BA_ "SPN" SG_ 2364632318 InstantaneousCombTimingPoint1 10015;
BA_ "SigType" SG_ 2364632318 InstantaneousCenterOfCombTiming 1;
BA_ "SPN" SG_ 2364632318 InstantaneousCenterOfCombTiming 10014;
BA_ "SigType" SG_ 2364632318 InstantaneousStartOfCombTiming 1;
BA_ "SPN" SG_ 2364632318 InstantaneousStartOfCombTiming 10013;
BA_ "SigType" SG_ 2364632062 InstantaneousCombTimingPoint2 1;
BA_ "SPN" SG_ 2364632062 InstantaneousCombTimingPoint2 10012;
BA_ "SigType" SG_ 2364632062 InstantaneousCombTimingPoint1 1;
BA_ "SPN" SG_ 2364632062 InstantaneousCombTimingPoint1 10011;
BA_ "SigType" SG_ 2364632062 InstantaneousCenterOfCombTiming 1;
BA_ "SPN" SG_ 2364632062 InstantaneousCenterOfCombTiming 10010;
BA_ "SigType" SG_ 2364632062 InstantaneousStartOfCombTiming 1;
BA_ "SPN" SG_ 2364632062 InstantaneousStartOfCombTiming 10009;
BA_ "SigType" SG_ 2364631806 InstantaneousCombTimingPoint2 1;
BA_ "SPN" SG_ 2364631806 InstantaneousCombTimingPoint2 10008;
BA_ "SigType" SG_ 2364631806 InstantaneousCombTimingPoint1 1;
BA_ "SPN" SG_ 2364631806 InstantaneousCombTimingPoint1 10007;
BA_ "SigType" SG_ 2364631806 InstantaneousCenterOfCombTiming 1;
BA_ "SPN" SG_ 2364631806 InstantaneousCenterOfCombTiming 10006;
BA_ "SigType" SG_ 2364631806 InstantaneousStartOfCombTiming 1;
BA_ "SPN" SG_ 2364631806 InstantaneousStartOfCombTiming 10005;
BA_ "SigType" SG_ 2364631550 InstantaneousCombTimingPoint2 1;
BA_ "SPN" SG_ 2364631550 InstantaneousCombTimingPoint2 10004;
BA_ "SigType" SG_ 2364631550 InstantaneousCombTimingPoint1 1;
BA_ "SPN" SG_ 2364631550 InstantaneousCombTimingPoint1 10003;
BA_ "SigType" SG_ 2364631550 InstantaneousCenterOfCombTiming 1;
BA_ "SPN" SG_ 2364631550 InstantaneousCenterOfCombTiming 10002;
BA_ "SigType" SG_ 2364631550 InstantaneousStartOfCombTiming 1;
BA_ "SPN" SG_ 2364631550 InstantaneousStartOfCombTiming 10001;
BA_ "SigType" SG_ 2364631294 InstantaneousCombTimingPoint2 1;
BA_ "SPN" SG_ 2364631294 InstantaneousCombTimingPoint2 10000;
BA_ "SigType" SG_ 2364631294 InstantaneousCombTimingPoint1 1;
BA_ "SPN" SG_ 2364631294 InstantaneousCombTimingPoint1 9999;
BA_ "SigType" SG_ 2364631294 InstantaneousCenterOfCombTiming 1;
BA_ "SPN" SG_ 2364631294 InstantaneousCenterOfCombTiming 9998;
BA_ "SigType" SG_ 2364631294 InstantaneousStartOfCombTiming 1;
BA_ "SPN" SG_ 2364631294 InstantaneousStartOfCombTiming 9997;
BA_ "SigType" SG_ 2364631038 InstantaneousCombTimingPoint2 1;
BA_ "SPN" SG_ 2364631038 InstantaneousCombTimingPoint2 9996;
BA_ "SigType" SG_ 2364631038 InstantaneousCombTimingPoint1 1;
BA_ "SPN" SG_ 2364631038 InstantaneousCombTimingPoint1 9995;
BA_ "SigType" SG_ 2364631038 InstantaneousCenterOfCombTiming 1;
BA_ "SPN" SG_ 2364631038 InstantaneousCenterOfCombTiming 9994;
BA_ "SigType" SG_ 2364631038 InstantaneousStartOfCombTiming 1;
BA_ "SPN" SG_ 2364631038 InstantaneousStartOfCombTiming 9993;
BA_ "SigType" SG_ 2364630782 InstantaneousCombTimingPoint2 1;
BA_ "SPN" SG_ 2364630782 InstantaneousCombTimingPoint2 9992;
BA_ "SigType" SG_ 2364630782 InstantaneousCombTimingPoint1 1;
BA_ "SPN" SG_ 2364630782 InstantaneousCombTimingPoint1 9991;
BA_ "SigType" SG_ 2364630782 InstantaneousCenterOfCombTiming 1;
BA_ "SPN" SG_ 2364630782 InstantaneousCenterOfCombTiming 9990;
BA_ "SigType" SG_ 2364630782 InstantaneousStartOfCombTiming 1;
BA_ "SPN" SG_ 2364630782 InstantaneousStartOfCombTiming 9989;
BA_ "SigType" SG_ 2364630526 InstantaneousCombTimingPoint2 1;
BA_ "SPN" SG_ 2364630526 InstantaneousCombTimingPoint2 9988;
BA_ "SigType" SG_ 2364630526 InstantaneousCombTimingPoint1 1;
BA_ "SPN" SG_ 2364630526 InstantaneousCombTimingPoint1 9987;
BA_ "SigType" SG_ 2364630526 InstantaneousCenterOfCombTiming 1;
BA_ "SPN" SG_ 2364630526 InstantaneousCenterOfCombTiming 9986;
BA_ "SigType" SG_ 2364630526 InstantaneousStartOfCombTiming 1;
BA_ "SPN" SG_ 2364630526 InstantaneousStartOfCombTiming 9985;
BA_ "SigType" SG_ 2364630270 InstantaneousCombTimingPoint2 1;
BA_ "SPN" SG_ 2364630270 InstantaneousCombTimingPoint2 9984;
BA_ "SigType" SG_ 2364630270 InstantaneousCombTimingPoint1 1;
BA_ "SPN" SG_ 2364630270 InstantaneousCombTimingPoint1 9983;
BA_ "SigType" SG_ 2364630270 InstantaneousCenterOfCombTiming 1;
BA_ "SPN" SG_ 2364630270 InstantaneousCenterOfCombTiming 9982;
BA_ "SigType" SG_ 2364630270 InstantaneousStartOfCombTiming 1;
BA_ "SPN" SG_ 2364630270 InstantaneousStartOfCombTiming 9981;
BA_ "SigType" SG_ 2364630014 InstantaneousCombTimingPoint2 1;
BA_ "SPN" SG_ 2364630014 InstantaneousCombTimingPoint2 9980;
BA_ "SigType" SG_ 2364630014 InstantaneousCombTimingPoint1 1;
BA_ "SPN" SG_ 2364630014 InstantaneousCombTimingPoint1 9979;
BA_ "SigType" SG_ 2364630014 InstantaneousCenterOfCombTiming 1;
BA_ "SPN" SG_ 2364630014 InstantaneousCenterOfCombTiming 9978;
BA_ "SigType" SG_ 2364630014 InstantaneousStartOfCombTiming 1;
BA_ "SPN" SG_ 2364630014 InstantaneousStartOfCombTiming 9977;
BA_ "SigType" SG_ 2364629758 InstantaneousCombTimingPoint2 1;
BA_ "SPN" SG_ 2364629758 InstantaneousCombTimingPoint2 9976;
BA_ "SigType" SG_ 2364629758 InstantaneousCombTimingPoint1 1;
BA_ "SPN" SG_ 2364629758 InstantaneousCombTimingPoint1 9975;
BA_ "SigType" SG_ 2364629758 InstantaneousCenterOfCombTiming 1;
BA_ "SPN" SG_ 2364629758 InstantaneousCenterOfCombTiming 9974;
BA_ "SigType" SG_ 2364629758 InstantaneousStartOfCombTiming 1;
BA_ "SPN" SG_ 2364629758 InstantaneousStartOfCombTiming 9973;
BA_ "SigType" SG_ 2364629502 InstantaneousCombTimingPoint2 1;
BA_ "SPN" SG_ 2364629502 InstantaneousCombTimingPoint2 9972;
BA_ "SigType" SG_ 2364629502 InstantaneousCombTimingPoint1 1;
BA_ "SPN" SG_ 2364629502 InstantaneousCombTimingPoint1 9971;
BA_ "SigType" SG_ 2364629502 InstantaneousCenterOfCombTiming 1;
BA_ "SPN" SG_ 2364629502 InstantaneousCenterOfCombTiming 9970;
BA_ "SigType" SG_ 2364629502 InstantaneousStartOfCombTiming 1;
BA_ "SPN" SG_ 2364629502 InstantaneousStartOfCombTiming 9969;
BA_ "SigType" SG_ 2364629246 InstantaneousCombTimingPoint2 1;
BA_ "SPN" SG_ 2364629246 InstantaneousCombTimingPoint2 9968;
BA_ "SigType" SG_ 2364629246 InstantaneousCombTimingPoint1 1;
BA_ "SPN" SG_ 2364629246 InstantaneousCombTimingPoint1 9967;
BA_ "SigType" SG_ 2364629246 InstantaneousCenterOfCombTiming 1;
BA_ "SPN" SG_ 2364629246 InstantaneousCenterOfCombTiming 9966;
BA_ "SigType" SG_ 2364629246 InstantaneousStartOfCombTiming 1;
BA_ "SPN" SG_ 2364629246 InstantaneousStartOfCombTiming 9965;
BA_ "SigType" SG_ 2364628990 InstantaneousCombTimingPoint2 1;
BA_ "SPN" SG_ 2364628990 InstantaneousCombTimingPoint2 9964;
BA_ "SigType" SG_ 2364628990 InstantaneousCombTimingPoint1 1;
BA_ "SPN" SG_ 2364628990 InstantaneousCombTimingPoint1 9963;
BA_ "SigType" SG_ 2364628990 InstantaneousCenterOfCombTiming 1;
BA_ "SPN" SG_ 2364628990 InstantaneousCenterOfCombTiming 9962;
BA_ "SigType" SG_ 2364628990 InstantaneousStartOfCombTiming 1;
BA_ "SPN" SG_ 2364628990 InstantaneousStartOfCombTiming 9961;
BA_ "SigType" SG_ 2364628734 InstantaneousCombTimingPoint2 1;
BA_ "SPN" SG_ 2364628734 InstantaneousCombTimingPoint2 9960;
BA_ "SigType" SG_ 2364628734 InstantaneousCombTimingPoint1 1;
BA_ "SPN" SG_ 2364628734 InstantaneousCombTimingPoint1 9959;
BA_ "SigType" SG_ 2364628734 InstantaneousCenterOfCombTiming 1;
BA_ "SPN" SG_ 2364628734 InstantaneousCenterOfCombTiming 9958;
BA_ "SigType" SG_ 2364628734 InstantaneousStartOfCombTiming 1;
BA_ "SPN" SG_ 2364628734 InstantaneousStartOfCombTiming 9957;
BA_ "SigType" SG_ 2364628478 InstantaneousCombTimingPoint2 1;
BA_ "SPN" SG_ 2364628478 InstantaneousCombTimingPoint2 9956;
BA_ "SigType" SG_ 2364628478 InstantaneousCombTimingPoint1 1;
BA_ "SPN" SG_ 2364628478 InstantaneousCombTimingPoint1 9955;
BA_ "SigType" SG_ 2364628478 InstantaneousCenterOfCombTiming 1;
BA_ "SPN" SG_ 2364628478 InstantaneousCenterOfCombTiming 9954;
BA_ "SigType" SG_ 2364628478 InstantaneousStartOfCombTiming 1;
BA_ "SPN" SG_ 2364628478 InstantaneousStartOfCombTiming 9953;
BA_ "SigType" SG_ 2364628222 InstantaneousCombTimingPoint2 1;
BA_ "SPN" SG_ 2364628222 InstantaneousCombTimingPoint2 9952;
BA_ "SigType" SG_ 2364628222 InstantaneousCombTimingPoint1 1;
BA_ "SPN" SG_ 2364628222 InstantaneousCombTimingPoint1 9951;
BA_ "SigType" SG_ 2364628222 InstantaneousCenterOfCombTiming 1;
BA_ "SPN" SG_ 2364628222 InstantaneousCenterOfCombTiming 9950;
BA_ "SigType" SG_ 2364628222 InstantaneousStartOfCombTiming 1;
BA_ "SPN" SG_ 2364628222 InstantaneousStartOfCombTiming 9949;
BA_ "SigType" SG_ 2364627966 InstantaneousCombTimingPoint2 1;
BA_ "SPN" SG_ 2364627966 InstantaneousCombTimingPoint2 9948;
BA_ "SigType" SG_ 2364627966 InstantaneousCombTimingPoint1 1;
BA_ "SPN" SG_ 2364627966 InstantaneousCombTimingPoint1 9947;
BA_ "SigType" SG_ 2364627966 InstantaneousCenterOfCombTiming 1;
BA_ "SPN" SG_ 2364627966 InstantaneousCenterOfCombTiming 9946;
BA_ "SigType" SG_ 2364627966 InstantaneousStartOfCombTiming 1;
BA_ "SPN" SG_ 2364627966 InstantaneousStartOfCombTiming 9945;
BA_ "SigType" SG_ 2364627710 InstantaneousCombTimingPoint2 1;
BA_ "SPN" SG_ 2364627710 InstantaneousCombTimingPoint2 9944;
BA_ "SigType" SG_ 2364627710 InstantaneousCombTimingPoint1 1;
BA_ "SPN" SG_ 2364627710 InstantaneousCombTimingPoint1 9943;
BA_ "SigType" SG_ 2364627710 InstantaneousCenterOfCombTiming 1;
BA_ "SPN" SG_ 2364627710 InstantaneousCenterOfCombTiming 9942;
BA_ "SigType" SG_ 2364627710 InstantaneousStartOfCombTiming 1;
BA_ "SPN" SG_ 2364627710 InstantaneousStartOfCombTiming 9941;
BA_ "SigType" SG_ 2364627454 InstantaneousCombTimingPoint2 1;
BA_ "SPN" SG_ 2364627454 InstantaneousCombTimingPoint2 9940;
BA_ "SigType" SG_ 2364627454 InstantaneousCombTimingPoint1 1;
BA_ "SPN" SG_ 2364627454 InstantaneousCombTimingPoint1 9939;
BA_ "SigType" SG_ 2364627454 InstantaneousCenterOfCombTiming 1;
BA_ "SPN" SG_ 2364627454 InstantaneousCenterOfCombTiming 9938;
BA_ "SigType" SG_ 2364627454 InstantaneousStartOfCombTiming 1;
BA_ "SPN" SG_ 2364627454 InstantaneousStartOfCombTiming 9937;
BA_ "SigType" SG_ 2364627198 Timing4Press 1;
BA_ "SPN" SG_ 2364627198 Timing4Press 9932;
BA_ "SigType" SG_ 2364627198 Timing3Press 1;
BA_ "SPN" SG_ 2364627198 Timing3Press 9931;
BA_ "SigType" SG_ 2364627198 Timing2Press 1;
BA_ "SPN" SG_ 2364627198 Timing2Press 9930;
BA_ "SigType" SG_ 2364627198 Timing1Press 1;
BA_ "SPN" SG_ 2364627198 Timing1Press 9929;
BA_ "SigType" SG_ 2364626942 Timing4Press 1;
BA_ "SPN" SG_ 2364626942 Timing4Press 9928;
BA_ "SigType" SG_ 2364626942 Timing3Press 1;
BA_ "SPN" SG_ 2364626942 Timing3Press 9927;
BA_ "SigType" SG_ 2364626942 Timing2Press 1;
BA_ "SPN" SG_ 2364626942 Timing2Press 9926;
BA_ "SigType" SG_ 2364626942 Timing1Press 1;
BA_ "SPN" SG_ 2364626942 Timing1Press 9925;
BA_ "SigType" SG_ 2364626686 Timing4Press 1;
BA_ "SPN" SG_ 2364626686 Timing4Press 9924;
BA_ "SigType" SG_ 2364626686 Timing3Press 1;
BA_ "SPN" SG_ 2364626686 Timing3Press 9923;
BA_ "SigType" SG_ 2364626686 Timing2Press 1;
BA_ "SPN" SG_ 2364626686 Timing2Press 9922;
BA_ "SigType" SG_ 2364626686 Timing1Press 1;
BA_ "SPN" SG_ 2364626686 Timing1Press 9921;
BA_ "SigType" SG_ 2364626430 Timing4Press 1;
BA_ "SPN" SG_ 2364626430 Timing4Press 9920;
BA_ "SigType" SG_ 2364626430 Timing3Press 1;
BA_ "SPN" SG_ 2364626430 Timing3Press 9919;
BA_ "SigType" SG_ 2364626430 Timing2Press 1;
BA_ "SPN" SG_ 2364626430 Timing2Press 9918;
BA_ "SigType" SG_ 2364626430 Timing1Press 1;
BA_ "SPN" SG_ 2364626430 Timing1Press 9917;
BA_ "SigType" SG_ 2364626174 Timing4Press 1;
BA_ "SPN" SG_ 2364626174 Timing4Press 9916;
BA_ "SigType" SG_ 2364626174 Timing3Press 1;
BA_ "SPN" SG_ 2364626174 Timing3Press 9915;
BA_ "SigType" SG_ 2364626174 Timing2Press 1;
BA_ "SPN" SG_ 2364626174 Timing2Press 9914;
BA_ "SigType" SG_ 2364626174 Timing1Press 1;
BA_ "SPN" SG_ 2364626174 Timing1Press 9913;
BA_ "SigType" SG_ 2364625918 Timing4Press 1;
BA_ "SPN" SG_ 2364625918 Timing4Press 9912;
BA_ "SigType" SG_ 2364625918 Timing3Press 1;
BA_ "SPN" SG_ 2364625918 Timing3Press 9911;
BA_ "SigType" SG_ 2364625918 Timing2Press 1;
BA_ "SPN" SG_ 2364625918 Timing2Press 9910;
BA_ "SigType" SG_ 2364625918 Timing1Press 1;
BA_ "SPN" SG_ 2364625918 Timing1Press 9909;
BA_ "SigType" SG_ 2364625662 Timing4Press 1;
BA_ "SPN" SG_ 2364625662 Timing4Press 9908;
BA_ "SigType" SG_ 2364625662 Timing3Press 1;
BA_ "SPN" SG_ 2364625662 Timing3Press 9907;
BA_ "SigType" SG_ 2364625662 Timing2Press 1;
BA_ "SPN" SG_ 2364625662 Timing2Press 9906;
BA_ "SigType" SG_ 2364625662 Timing1Press 1;
BA_ "SPN" SG_ 2364625662 Timing1Press 9905;
BA_ "SigType" SG_ 2364625406 Timing4Press 1;
BA_ "SPN" SG_ 2364625406 Timing4Press 9904;
BA_ "SigType" SG_ 2364625406 Timing3Press 1;
BA_ "SPN" SG_ 2364625406 Timing3Press 9903;
BA_ "SigType" SG_ 2364625406 Timing2Press 1;
BA_ "SPN" SG_ 2364625406 Timing2Press 9902;
BA_ "SigType" SG_ 2364625406 Timing1Press 1;
BA_ "SPN" SG_ 2364625406 Timing1Press 9901;
BA_ "SigType" SG_ 2364625150 Timing4Press 1;
BA_ "SPN" SG_ 2364625150 Timing4Press 9900;
BA_ "SigType" SG_ 2364625150 Timing3Press 1;
BA_ "SPN" SG_ 2364625150 Timing3Press 9899;
BA_ "SigType" SG_ 2364625150 Timing2Press 1;
BA_ "SPN" SG_ 2364625150 Timing2Press 9898;
BA_ "SigType" SG_ 2364625150 Timing1Press 1;
BA_ "SPN" SG_ 2364625150 Timing1Press 9897;
BA_ "SigType" SG_ 2364624894 Timing4Press 1;
BA_ "SPN" SG_ 2364624894 Timing4Press 9896;
BA_ "SigType" SG_ 2364624894 Timing3Press 1;
BA_ "SPN" SG_ 2364624894 Timing3Press 9895;
BA_ "SigType" SG_ 2364624894 Timing2Press 1;
BA_ "SPN" SG_ 2364624894 Timing2Press 9894;
BA_ "SigType" SG_ 2364624894 Timing1Press 1;
BA_ "SPN" SG_ 2364624894 Timing1Press 9893;
BA_ "SigType" SG_ 2364624638 Timing4Press 1;
BA_ "SPN" SG_ 2364624638 Timing4Press 9892;
BA_ "SigType" SG_ 2364624638 Timing3Press 1;
BA_ "SPN" SG_ 2364624638 Timing3Press 9891;
BA_ "SigType" SG_ 2364624638 Timing2Press 1;
BA_ "SPN" SG_ 2364624638 Timing2Press 9890;
BA_ "SigType" SG_ 2364624638 Timing1Press 1;
BA_ "SPN" SG_ 2364624638 Timing1Press 9889;
BA_ "SigType" SG_ 2364624382 Timing4Press 1;
BA_ "SPN" SG_ 2364624382 Timing4Press 9888;
BA_ "SigType" SG_ 2364624382 Timing3Press 1;
BA_ "SPN" SG_ 2364624382 Timing3Press 9887;
BA_ "SigType" SG_ 2364624382 Timing2Press 1;
BA_ "SPN" SG_ 2364624382 Timing2Press 9886;
BA_ "SigType" SG_ 2364624382 Timing1Press 1;
BA_ "SPN" SG_ 2364624382 Timing1Press 9885;
BA_ "SigType" SG_ 2364624126 Timing4Press 1;
BA_ "SPN" SG_ 2364624126 Timing4Press 9884;
BA_ "SigType" SG_ 2364624126 Timing3Press 1;
BA_ "SPN" SG_ 2364624126 Timing3Press 9883;
BA_ "SigType" SG_ 2364624126 Timing2Press 1;
BA_ "SPN" SG_ 2364624126 Timing2Press 9882;
BA_ "SigType" SG_ 2364624126 Timing1Press 1;
BA_ "SPN" SG_ 2364624126 Timing1Press 9881;
BA_ "SigType" SG_ 2364623870 Timing4Press 1;
BA_ "SPN" SG_ 2364623870 Timing4Press 9880;
BA_ "SigType" SG_ 2364623870 Timing3Press 1;
BA_ "SPN" SG_ 2364623870 Timing3Press 9879;
BA_ "SigType" SG_ 2364623870 Timing2Press 1;
BA_ "SPN" SG_ 2364623870 Timing2Press 9878;
BA_ "SigType" SG_ 2364623870 Timing1Press 1;
BA_ "SPN" SG_ 2364623870 Timing1Press 9877;
BA_ "SigType" SG_ 2364623614 Timing4Press 1;
BA_ "SPN" SG_ 2364623614 Timing4Press 9876;
BA_ "SigType" SG_ 2364623614 Timing3Press 1;
BA_ "SPN" SG_ 2364623614 Timing3Press 9875;
BA_ "SigType" SG_ 2364623614 Timing2Press 1;
BA_ "SPN" SG_ 2364623614 Timing2Press 9874;
BA_ "SigType" SG_ 2364623614 Timing1Press 1;
BA_ "SPN" SG_ 2364623614 Timing1Press 9873;
BA_ "SigType" SG_ 2364623358 Timing4Press 1;
BA_ "SPN" SG_ 2364623358 Timing4Press 9872;
BA_ "SigType" SG_ 2364623358 Timing3Press 1;
BA_ "SPN" SG_ 2364623358 Timing3Press 9871;
BA_ "SigType" SG_ 2364623358 Timing2Press 1;
BA_ "SPN" SG_ 2364623358 Timing2Press 9870;
BA_ "SigType" SG_ 2364623358 Timing1Press 1;
BA_ "SPN" SG_ 2364623358 Timing1Press 9869;
BA_ "SigType" SG_ 2364623102 Timing4Press 1;
BA_ "SPN" SG_ 2364623102 Timing4Press 9868;
BA_ "SigType" SG_ 2364623102 Timing3Press 1;
BA_ "SPN" SG_ 2364623102 Timing3Press 9867;
BA_ "SigType" SG_ 2364623102 Timing2Press 1;
BA_ "SPN" SG_ 2364623102 Timing2Press 9866;
BA_ "SigType" SG_ 2364623102 Timing1Press 1;
BA_ "SPN" SG_ 2364623102 Timing1Press 9865;
BA_ "SigType" SG_ 2364622846 Timing4Press 1;
BA_ "SPN" SG_ 2364622846 Timing4Press 9864;
BA_ "SigType" SG_ 2364622846 Timing3Press 1;
BA_ "SPN" SG_ 2364622846 Timing3Press 9863;
BA_ "SigType" SG_ 2364622846 Timing2Press 1;
BA_ "SPN" SG_ 2364622846 Timing2Press 9862;
BA_ "SigType" SG_ 2364622846 Timing1Press 1;
BA_ "SPN" SG_ 2364622846 Timing1Press 9861;
BA_ "SigType" SG_ 2364622590 Timing4Press 1;
BA_ "SPN" SG_ 2364622590 Timing4Press 9860;
BA_ "SigType" SG_ 2364622590 Timing3Press 1;
BA_ "SPN" SG_ 2364622590 Timing3Press 9859;
BA_ "SigType" SG_ 2364622590 Timing2Press 1;
BA_ "SPN" SG_ 2364622590 Timing2Press 9858;
BA_ "SigType" SG_ 2364622590 Timing1Press 1;
BA_ "SPN" SG_ 2364622590 Timing1Press 9857;
VAL_ 2364643326 OperationalStatus 15 "Not Available" 14 "Error" 13 "Reserved" 12 "Reserved" 11 "Reserved" 10 "Reserved" 9 "Reserved" 8 "Reserved" 7 "Reserved" 6 "Disabled by internal decision of HVES controller" 5 "Disabled by external command" 4 "Emergency Power-Down In Process" 3 "Normal Power-Down in Process" 2 "Operational." 1 "Initialization Complete" 0 "Initialization in process" ;
VAL_ 2364643326 HVBusConnectionStatus 15 "Not Available" 14 "Error" 13 "Reserved" 12 "Reserved" 11 "Reserved" 10 "Reserved" 9 "Reserved" 8 "Reserved" 7 "Reserved" 6 "Reserved" 5 "Reserved" 4 "Disconnected,  Precharge Failed" 3 "Disconnection in Process" 2 "Connection in Process" 1 "Connected" 0 "Disconnected,  One or more contactors are open" ;
VAL_ 2364643326 InternalChargerStatus 3 "Not Available" 2 "Error" 1 "Charging on" 0 "Charging off" ;
VAL_ 2364643326 CellBalancingActive 3 "Not Available" 2 "Error" 1 "Cell balancing is active" 0 "Cell balancing is not active" ;
VAL_ 2364643326 CellBalanceStatus 3 "Not Available" 2 "Error" 1 "Cells are unbalanced" 0 "Cells are balanced" ;
VAL_ 2364643326 StOfChargeStatus 15 "Not  Available" 14 "Error" 13 "Reserved" 12 "Reserved" 11 "Reserved" 10 "Reserved" 9 "Reserved" 8 "Reserved" 7 "Reserved" 6 "SOC is above its recommended upper limit" 5 "SOC is at its recommended upper limit" 4 "SOC is approaching its recommended upper limit" 3 "SOC is below its recommended lower limit" 2 "SOC is at its recommended lower limit" 1 "SOC is approaching its recommended lower limit" 0 "SOC level is acceptable" ;
VAL_ 2364643326 InertiaSwStatus 3 "Not Available" 2 "Error" 1 "Impact sensed" 0 "No impact sensed" ;
VAL_ 2364643326 HVILStatus 3 "Not Available" 2 "Error" 1 "HVIL Open" 0 "HVIL Closed" ;
VAL_ 2364643326 HVBusPassiveIsolTestStatus 15 "Not available" 14 "Error" 13 "Reserved" 12 "Reserved" 11 "Reserved" 10 "Reserved" 9 "Reserved" 8 "Reserved" 7 "Reserved" 6 "Reserved" 5 "Test complete,  isolation fault" 4 "Test complete,  isolation marginal" 3 "Test complete,  isolation acceptable" 2 "Test in process" 1 "Test requested but not yet in process" 0 "No test requested / No test in process" ;
VAL_ 2364643326 HVBusActiveIsolTestStatus 15 "Not available" 14 "Error" 13 "Reserved" 12 "Reserved" 11 "Reserved" 10 "Reserved" 9 "Reserved" 8 "Reserved" 7 "Reserved" 6 "Reserved" 5 "Test complete,  isolation fault" 4 "Test complete,  isolation marginal" 3 "Test complete,  isolation acceptable" 2 "Test in process" 1 "Test requested but not yet in process" 0 "No test requested / No test in process" ;
VAL_ 2364643326 CenterOfPackContactorSt 3 "Not Available" 2 "Error" 1 "Contactor Closed" 0 "Contactor Open" ;
VAL_ 2364643326 HVBusPreChargeRelaySt 3 "Not Available" 2 "Error" 1 "Relay Closed" 0 "Relay Open" ;
VAL_ 2364643326 HVBusDisconnectForewarning 15 "Not Available" 14 "Error" 13 "Disconnect imminent" 12 "Reserved" 11 "Reserved" 10 "Reserved" 9 "Reserved" 8 "Reserved" 7 "Disconnect imminent due to battery pack current approaching maximum acceptable level" 6 "Disconnect imminent due to cell voltage approaching maximum acceptable level" 5 "Disconnect imminent due to cell voltage approaching minimum acceptable level" 4 "Disconnect imminent due to module voltage approaching maximum acceptable level" 3 "Disconnect imminent due to module voltage approaching minimum acceptable level" 2 "Disconnect imminent due to battery pack voltage approaching maximum acceptable level" 1 "Disconnect imminent due to battery pack voltage approaching minimum acceptable level" 0 "Disconnect not pending" ;
VAL_ 2364643326 HVBusContactorSt11076 3 "Not Available" 2 "Error" 1 "Contactor Closed" 0 "Contactor Open" ;
VAL_ 2364643326 HVBusContactorSt 3 "Not Available" 2 "Error" 1 "Contactor Closed" 0 "Contactor Open" ;
VAL_ 2364642302 CellTempDiffStatus 3 "Not Available" 2 "Error" 1 "Cell-to-cell temperature differential exceeds acceptable limits" 0 "Cell-to-cell temperature differential is within acceptable limits" ;
VAL_ 2364642046 CellVDiffStatus 15 "Not Available" 14 "Error" 13 "Reserved" 12 "Reserved" 11 "Reserved" 10 "Reserved" 9 "Reserved" 8 "Reserved" 7 "Reserved" 6 "Reserved" 5 "Reserved" 4 "Exceeds limits and it is not known whether balancing can restore performance" 3 "Exceeds limits and external maintenance balancing cannot restore performance" 2 "Exceeds limits and external maintenance balancing is required" 1 "Exceeds limits and can be corrected via auto-balancing" 0 "Is within acceptable limits" ;
VAL_ 2364641534 ChargePLDueToAnUndefinedCause 3 "Not Available" 2 "Error" 1 "Power limited for this reason" 0 "No power limit for this reason" ;
VAL_ 2364641534 ChargePLDueToBatCur 3 "Not Available" 2 "Error" 1 "Power limited for this reason" 0 "No power limit for this reason" ;
VAL_ 2364641534 ChargePLDueToBatOrCellV 3 "Not Available" 2 "Error" 1 "Power limited for this reason" 0 "No power limit for this reason" ;
VAL_ 2364641534 ChargePLDueToBatDiagCondition 3 "Not Available" 2 "Error" 1 "Power limited for this reason" 0 "No power limit for this reason" ;
VAL_ 2364641534 ChargePLDueToBatTemp 3 "Not Available" 2 "Error" 1 "Power limited for this reason" 0 "No power limit for this reason" ;
VAL_ 2364641534 ChargePLDueToStOfCharge 3 "Not Available" 2 "Error" 1 "Power limited for this reason" 0 "No power limit for this reason" ;
VAL_ 2364641534 DisPLDueToAnUndefinedCause 3 "Not Available" 2 "Error" 1 "Power limited for this reason" 0 "No power limit for this reason" ;
VAL_ 2364641534 DisPLDueToBatCur 3 "Not Available" 2 "Error" 1 "Power limited for this reason" 0 "No power limit for this reason" ;
VAL_ 2364641534 DisPLDueToBatOrCellV 3 "Not Available" 2 "Error" 1 "Power limited for this reason" 0 "No power limit for this reason" ;
VAL_ 2364641534 DisPLDueToBatDiagCondition 3 "Not Available" 2 "Error" 1 "Power limited for this reason" 0 "No power limit for this reason" ;
VAL_ 2364641534 DisPLDueToBatTemp 3 "Not Available" 2 "Error" 1 "Power limited for this reason" 0 "No power limit for this reason" ;
VAL_ 2364641534 DisPLDueToStOfCharge 3 "Not Available" 2 "Error" 1 "Power limited for this reason" 0 "No power limit for this reason" ;
VAL_ 2297532414 TimeSinceLastImposterPGDetected 253 "The Impostor PG is not active" 252 "The Impostor PG is actively being detected" 251 "No impostor PG has been detected during the current ECU power cycle" ;
VAL_ 2364638974 HVILStatus 3 "Not Available" 2 "Error" 1 "HVIL Open" 0 "HVIL Closed" ;
VAL_ 2364638974 CtrlSetpointMode 31 "Not Available" 30 "Error" 29 "Manufacturer specific special mode 2" 28 "Manufacturer specific special mode 1" 27 "Manufacturer specific special mode 4" 26 "Manufacturer specific special mode 3" 25 "SAE Reserved" 24 "SAE Reserved" 23 "SAE Reserved" 22 "SAE Reserved" 21 "Inverter power down command" 20 "Inverter active discharge mode e.g" 19 "Manufacturer specific active mode 2" 18 "Manufacturer specific active mode 1" 17 "SAE Reserved" 16 "SAE Reserved" 15 "SAE Reserved" 14 "SAE Reserved" 13 "SAE Reserved" 12 "DC Power Control Mode" 11 "Mechanical Power Control Mode" 10 "DC Side Current Mode" 9 "DC Side Voltage Mode" 8 "Speed Control Mode" 7 "Torque Control Mode" 6 "Manufacturer specific passive mode 2" 5 "Manufacturer specific passive mode 1" 4 "SAE Reserved" 3 "SAE Reserved" 2 "Standby" 1 "Waiting for Operational conditions" 0 "Powered On" ;
VAL_ 2364638974 CtrlLimitsOvrdMode 15 "Not Available" 14 "Error" 13 "SAE Reserved" 12 "SAE Reserved" 11 "SAE Reserved" 10 "SAE Reserved" 9 "SAE Reserved" 8 "SAE Reserved" 7 "SAE Reserved" 6 "Mechanical Power Limits Mode" 5 "DC Side Power Limits Mode" 4 "DC Side Current Limits Mode" 3 "DC Side Voltage Limits Mode" 2 "Speed Limits Mode" 1 "Torque Limits Mode" 0 "Operating limits are not overridden" ;
VAL_ 2364637694 HVILStatus 3 "Not Available" 2 "Error" 1 "HVIL Open" 0 "HVIL Closed" ;
VAL_ 2364637694 CtrlSetpointMode 31 "Not Available" 30 "Error" 29 "Manufacturer specific special mode 2" 28 "Manufacturer specific special mode 1" 27 "Manufacturer specific special mode 4" 26 "Manufacturer specific special mode 3" 25 "SAE Reserved" 24 "SAE Reserved" 23 "SAE Reserved" 22 "SAE Reserved" 21 "Inverter power down command" 20 "Inverter active discharge mode e.g" 19 "Manufacturer specific active mode 2" 18 "Manufacturer specific active mode 1" 17 "SAE Reserved" 16 "SAE Reserved" 15 "SAE Reserved" 14 "SAE Reserved" 13 "SAE Reserved" 12 "DC Power Control Mode" 11 "Mechanical Power Control Mode" 10 "DC Side Current Mode" 9 "DC Side Voltage Mode" 8 "Speed Control Mode" 7 "Torque Control Mode" 6 "Manufacturer specific passive mode 2" 5 "Manufacturer specific passive mode 1" 4 "SAE Reserved" 3 "SAE Reserved" 2 "Standby" 1 "Waiting for Operational conditions" 0 "Powered On" ;
VAL_ 2364637694 CtrlLimitsOvrdMode 15 "Not Available" 14 "Error" 13 "SAE Reserved" 12 "SAE Reserved" 11 "SAE Reserved" 10 "SAE Reserved" 9 "SAE Reserved" 8 "SAE Reserved" 7 "SAE Reserved" 6 "Mechanical Power Limits Mode" 5 "DC Side Power Limits Mode" 4 "DC Side Current Limits Mode" 3 "DC Side Voltage Limits Mode" 2 "Speed Limits Mode" 1 "Torque Limits Mode" 0 "Operating limits are not overridden" ;
